VERSION "HNNBNNNYNNNNNNNNNNNNNNNNNNNNNNNNNNNNNNNNNN/4/%%%/4/'%**4NNN///"

NS_ :

BS_:

BU_: BAP_Tester CGS Gateway Gateway_PAG HUD Kombi Kombi_LB Kombi_PAG Waehlhebel_SB

BO_ 980 SMLS_01: 8 Gateway
 SG_ SMLS_01_CRC : 0|8@1+ (1,0) [0|255] ""  Vector__XXX
 SG_ SMLS_01_BZ : 8|4@1+ (1,0) [0|15] ""  Vector__XXX
 SG_ BH_Blinker_li : 12|1@1+ (1.0,0.0) [0.0|1] ""  Vector__XXX
 SG_ BH_Blinker_re : 13|1@1+ (1.0,0.0) [0.0|1] ""  Vector__XXX
 SG_ BH_Lichthupe : 14|1@1+ (1.0,0.0) [0.0|1] ""  Vector__XXX
 SG_ BH_Fernlicht : 15|1@1+ (1.0,0.0) [0.0|1] ""  Vector__XXX
 SG_ WH_Tipwischen : 16|1@1+ (1.0,0.0) [0.0|1] ""  Vector__XXX
 SG_ WH_Intervall : 17|1@1+ (1.0,0.0) [0.0|1] ""  Kombi_LB
 SG_ WH_WischerStufe1 : 18|1@1+ (1.0,0.0) [0.0|1] ""  Kombi_LB
 SG_ WH_WischerStufe2 : 19|1@1+ (1.0,0.0) [0.0|1] ""  Kombi_LB
 SG_ WH_Frontwaschen : 20|1@1+ (1.0,0.0) [0.0|1] ""  Vector__XXX
 SG_ WH_Heckintervall : 21|1@1+ (1.0,0.0) [0.0|1] ""  Kombi,Kombi_LB
 SG_ WH_Heckwaschen : 22|1@1+ (1.0,0.0) [0.0|1] ""  Vector__XXX
 SG_ WH_Intervallstufen : 23|4@1+ (1.0,0.0) [0.0|15] ""  Vector__XXX
 SG_ FAS_Taster : 27|1@1+ (1.0,0.0) [0.0|1] ""  Kombi,Kombi_LB
 SG_ FAS_Taster_Fehler : 28|1@1+ (1.0,0.0) [0.0|1] ""  Vector__XXX
 SG_ SMLS_Hupe : 29|1@1+ (1.0,0.0) [0.0|1] ""  Vector__XXX
 SG_ LRH_On_Off : 30|2@1+ (1.0,0.0) [0.0|3] ""  Kombi,Kombi_LB,Kombi_PAG
 SG_ LRH_aktiv : 40|1@1+ (1.0,0.0) [0.0|1] ""  Vector__XXX
 SG_ SMLS_P_verriegelt_plausibel : 43|1@1+ (1.0,0.0) [0.0|1] ""  Vector__XXX
 SG_ WH_SRA : 44|1@1+ (1.0,0.0) [0.0|1] ""  Vector__XXX
 SG_ WH_Wischer_Fehler : 45|1@1+ (1.0,0.0) [0.0|1] ""  Vector__XXX
 SG_ BH_Blinker_Fehler : 46|1@1+ (1.0,0.0) [0.0|1] ""  Vector__XXX
 SG_ SMLS_PTT : 47|1@1+ (1.0,0.0) [0.0|1] ""  Vector__XXX
 SG_ WH_Tipwischen_lang : 48|1@1+ (1.0,0.0) [0.0|1] ""  Vector__XXX

BO_ 904 SpoilerSG_01: 8 Gateway
 SG_ SpoilerSG_01_CRC : 0|8@1+ (1,0) [0|255] ""  Kombi,Kombi_PAG
 SG_ SpoilerSG_01_BZ : 8|4@1+ (1,0) [0|15] ""  Kombi,Kombi_PAG
 SG_ SpoilerSG_HSpoiler_IstPos : 12|8@1+ (4,0) [0|1012] ""  Kombi_PAG
 SG_ SpoilerSG_Fehler : 20|2@1+ (1.0,0.0) [0.0|3] ""  Kombi,Kombi_PAG
 SG_ SpoilerSG_Anf_ESP_Zuschaltung : 22|1@1+ (1.0,0.0) [0.0|1] ""  Vector__XXX
 SG_ SpoilerSG_Status : 23|2@1+ (1.0,0.0) [0.0|3] ""  Kombi_PAG
 SG_ LFE_Status : 25|1@1+ (1.0,0.0) [0.0|1] ""  Kombi_PAG
 SG_ TE_TrunkEntrapment_Fehler : 26|1@1+ (1.0,0.0) [0.0|1] ""  Vector__XXX
 SG_ SpoilerSG_AeroZustand : 27|4@1+ (1.0,0.0) [0.0|15] ""  Vector__XXX
 SG_ BugSp_AOCCT_Fehlerstatus : 31|1@1+ (1.0,0.0) [0.0|1] ""  Vector__XXX
 SG_ BugSp_AOCCT_Teststatus : 32|1@1+ (1.0,0.0) [0.0|1] ""  Vector__XXX
 SG_ BugSp_AOCCT_timer1_count : 33|1@1+ (1.0,0.0) [0.0|1] ""  Vector__XXX
 SG_ BugSp_AOCCT_timer1_verbaut : 34|1@1+ (1.0,0.0) [0.0|1] ""  Vector__XXX
 SG_ BugSp_AOCCT_timer2_count : 35|1@1+ (1.0,0.0) [0.0|1] ""  Vector__XXX
 SG_ BugSp_AOCCT_timer2_verbaut : 36|1@1+ (1.0,0.0) [0.0|1] ""  Vector__XXX
 SG_ HeckSp_AOCCT_Fehlerstatus : 37|1@1+ (1.0,0.0) [0.0|1] ""  Vector__XXX
 SG_ HeckSp_AOCCT_Teststatus : 38|1@1+ (1.0,0.0) [0.0|1] ""  Vector__XXX
 SG_ HeckSp_AOCCT_timer1_count : 39|1@1+ (1.0,0.0) [0.0|1] ""  Vector__XXX
 SG_ HeckSp_AOCCT_timer1_verbaut : 40|1@1+ (1.0,0.0) [0.0|1] ""  Vector__XXX
 SG_ HeckSp_AOCCT_timer2_count : 41|1@1+ (1.0,0.0) [0.0|1] ""  Vector__XXX
 SG_ HeckSp_AOCCT_timer2_verbaut : 42|1@1+ (1.0,0.0) [0.0|1] ""  Vector__XXX
 SG_ SpoilerSG_SKE_PosSens_Status : 43|2@1+ (1.0,0.0) [0.0|3] ""  Vector__XXX

BO_ 1313 STH_01: 8 Gateway
 SG_ STH_Funk_ein : 0|1@1+ (1.0,0.0) [0.0|1] ""  Vector__XXX
 SG_ STH_Funk_aus : 1|1@1+ (1.0,0.0) [0.0|1] ""  Vector__XXX
 SG_ STH_Zusatzheizung : 2|1@1+ (1.0,0.0) [0.0|1] ""  Vector__XXX
 SG_ STH_LED : 3|1@1+ (1.0,0.0) [0.0|1] ""  Kombi,Kombi_PAG
 SG_ STH_Pumpe_ein : 4|1@1+ (1,0) [0|1] ""  Vector__XXX
 SG_ STH_Geblaese : 5|1@1+ (1.0,0.0) [0.0|1] ""  Vector__XXX
 SG_ STH_EKP_Anst : 6|1@1+ (1.0,0.0) [0.0|1] ""  Vector__XXX
 SG_ STH_Start_folgt : 7|1@1+ (1.0,0.0) [0.0|1] ""  Vector__XXX
 SG_ STH_Ventiloeffnungszeit : 8|6@1+ (1,0) [0|63] "Unit_Minut"  Vector__XXX
 SG_ STH_Ventil_Status : 14|1@1+ (1.0,0.0) [0.0|1] ""  Vector__XXX
 SG_ STH_Fehler_ElWaPu : 15|1@1+ (1.0,0.0) [0.0|1] ""  Vector__XXX
 SG_ STH_Waermeeintrag : 16|6@1+ (1,0) [0|63] "Unit_None"  Vector__XXX
 SG_ STH_Pumpen_Anf_extern : 22|1@1+ (1.0,0.0) [0.0|1] ""  Vector__XXX
 SG_ STH_KL_HUP : 23|1@1+ (1.0,0.0) [0.0|1] ""  Vector__XXX
 SG_ STH_KVS : 24|13@1+ (1,0) [0|8191] "Unit_MilliLiter"  Kombi,Kombi_PAG
 SG_ STH_Fehlerstatus : 37|3@1+ (1.0,0.0) [0.0|7] ""  Vector__XXX
 SG_ STH_Heizleistung : 40|8@1+ (1,0) [0|255] ""  Vector__XXX
 SG_ STH_Wassertemp : 48|8@1+ (0.75,-40) [-40.00|142.25] "Unit_DegreCelsi"  Vector__XXX
 SG_ STH_Texte : 56|3@1+ (1.0,0.0) [0.0|7] ""  Kombi,Kombi_PAG
 SG_ STH_Motorvorwaermung : 59|1@1+ (1.0,0.0) [0.0|1] ""  Vector__XXX
 SG_ STH_Servicemode : 60|1@1+ (1.0,0.0) [0.0|1] ""  Vector__XXX
 SG_ STH_war_aktiv : 61|1@1+ (1.0,0.0) [0.0|1] ""  Vector__XXX
 SG_ STH_KVS_Ueberlauf : 62|1@1+ (1.0,0.0) [0.0|1] ""  Kombi,Kombi_LB,Kombi_PAG
 SG_ STH_SH_ZH : 63|1@1+ (1.0,0.0) [0.0|1] ""  Vector__XXX

BO_ 505 STP_03: 8 Gateway
 SG_ STP_03_CRC : 0|8@1+ (1,0) [0|255] ""  Vector__XXX
 SG_ STP_03_BZ : 8|4@1+ (1,0) [0|15] ""  Vector__XXX
 SG_ STP_Slave_Status : 12|4@1+ (1.0,0.0) [0.0|15] ""  Vector__XXX
 SG_ FZE_STP_Abschaltbedingung : 16|3@1+ (1.0,0.0) [0.0|7] ""  Vector__XXX
 SG_ ACA_HF_Grund_AV_AB : 19|3@1+ (1.0,0.0) [0.0|7] ""  Vector__XXX
 SG_ FZE_STP_Status : 22|2@1+ (1.0,0.0) [0.0|3] ""  Vector__XXX
 SG_ STP_Notlaufaktivierung : 25|1@1+ (1.0,0.0) [0.0|1] ""  Vector__XXX
 SG_ STP_Funktion_freigegeben : 26|1@1+ (1.0,0.0) [0.0|1] ""  Vector__XXX
 SG_ ACA_QF_Status_Anzeige : 27|4@1+ (1.0,0.0) [0.0|15] ""  HUD,Kombi,Kombi_LB,Kombi_PAG
 SG_ ACF_SwuFahrerUnaufmerksam : 31|1@1+ (1.0,0.0) [0.0|1] ""  Vector__XXX
 SG_ ACA_QF_Fahreruebernahme : 32|2@1+ (1.0,0.0) [0.0|3] ""  Kombi_PAG
 SG_ ACA_HF_Status : 34|4@1+ (1.0,0.0) [0.0|15] ""  Vector__XXX
 SG_ FZE_Spurwechsel_erkannt_li : 40|1@1+ (1.0,0.0) [0.0|1] ""  Vector__XXX
 SG_ FZE_Spurwechsel_erkannt_re : 41|1@1+ (1.0,0.0) [0.0|1] ""  Vector__XXX
 SG_ ACF_Spurwechsel_moeglich : 42|1@1+ (1.0,0.0) [0.0|1] ""  Vector__XXX
 SG_ ACF_Spurwechsel_wahrscheinlich : 43|1@1+ (1.0,0.0) [0.0|1] ""  Vector__XXX
 SG_ FZE_STP_Aktivierverhinderung : 44|2@1+ (1.0,0.0) [0.0|3] ""  Vector__XXX

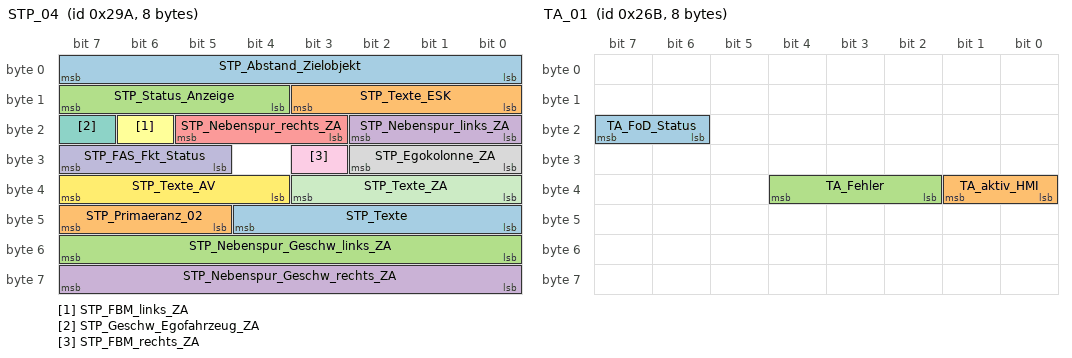
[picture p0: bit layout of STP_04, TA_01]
BO_ 666 STP_04: 8 Gateway
 SG_ STP_Abstand_Zielobjekt : 0|8@1+ (1,0) [1|250] ""  Kombi,Kombi_LB,Kombi_PAG
 SG_ STP_Texte_ESK : 8|4@1+ (1.0,0.0) [0.0|15] ""  Kombi,Kombi_LB,Kombi_PAG
 SG_ STP_Status_Anzeige : 12|4@1+ (1.0,0.0) [0.0|15] ""  HUD,Kombi,Kombi_LB,Kombi_PAG
 SG_ STP_Nebenspur_links_ZA : 16|3@1+ (1.0,0.0) [0.0|7] ""  Kombi,Kombi_LB,Kombi_PAG
 SG_ STP_Nebenspur_rechts_ZA : 19|3@1+ (1.0,0.0) [0.0|7] ""  Kombi,Kombi_LB,Kombi_PAG
 SG_ STP_FBM_links_ZA : 22|1@1+ (1.0,0.0) [0.0|1] ""  Kombi,Kombi_LB,Kombi_PAG
 SG_ STP_Geschw_Egofahrzeug_ZA : 23|1@1+ (1.0,0.0) [0.0|1] ""  Kombi,Kombi_LB,Kombi_PAG
 SG_ STP_Egokolonne_ZA : 24|3@1+ (1.0,0.0) [0.0|7] ""  Kombi,Kombi_LB,Kombi_PAG
 SG_ STP_FBM_rechts_ZA : 27|1@1+ (1.0,0.0) [0.0|1] ""  Kombi,Kombi_LB,Kombi_PAG
 SG_ STP_FAS_Fkt_Status : 29|3@1+ (1.0,0.0) [0.0|7] ""  HUD
 SG_ STP_Texte_ZA : 32|4@1+ (1.0,0.0) [0.0|15] ""  Kombi,Kombi_LB,Kombi_PAG
 SG_ STP_Texte_AV : 36|4@1+ (1.0,0.0) [0.0|15] ""  Kombi,Kombi_LB,Kombi_PAG
 SG_ STP_Texte : 40|5@1+ (1.0,0.0) [0.0|31] ""  Kombi,Kombi_LB,Kombi_PAG
 SG_ STP_Primaeranz_02 : 45|3@1+ (1.0,0.0) [0.0|7] ""  HUD,Kombi,Kombi_LB,Kombi_PAG
 SG_ STP_Nebenspur_Geschw_links_ZA : 48|8@1+ (1,0) [0|250] "Unit_KiloMeterPerHour"  Kombi,Kombi_LB
 SG_ STP_Nebenspur_Geschw_rechts_ZA : 56|8@1+ (1,0) [0|250] "Unit_KiloMeterPerHour"  Kombi,Kombi_LB

BO_ 1172 STS_01: 8 Gateway
 SG_ STS_01_CRC : 0|8@1+ (1,0) [0|255] ""  Vector__XXX
 SG_ STS_01_BZ : 8|4@1+ (1,0) [0|15] ""  Vector__XXX
 SG_ STS_Car_not_under_theft : 12|1@1+ (1.0,0.0) [0.0|1] ""  Vector__XXX
 SG_ STS_Car_under_theft : 13|1@1+ (1.0,0.0) [0.0|1] ""  Vector__XXX
 SG_ STS_Door_Lock : 14|1@1+ (1.0,0.0) [0.0|1] ""  Vector__XXX
 SG_ STS_Anlassersperre : 15|1@1+ (1.0,0.0) [0.0|1] ""  Vector__XXX
 SG_ STS_Typencodierung : 16|5@1+ (1.0,0.0) [0.0|31] ""  Vector__XXX
 SG_ STS_Spiegel_Anklappen : 21|1@1+ (1.0,0.0) [0.0|1] ""  Vector__XXX
 SG_ GW_STS2_Privatsphaere : 22|1@1+ (1.0,0.0) [0.0|1] ""  Vector__XXX
 SG_ STS_LIN_aktiv : 23|1@1+ (1.0,0.0) [0.0|1] ""  Vector__XXX
 SG_ STS_Standlicht : 24|1@1+ (1.0,0.0) [0.0|1] ""  Vector__XXX
 SG_ STS_Fahrlicht : 25|1@1+ (1.0,0.0) [0.0|1] ""  Vector__XXX
 SG_ STS_Alarm_still : 26|1@1+ (1.0,0.0) [0.0|1] ""  Vector__XXX
 SG_ STS_Texte : 27|4@1+ (1.0,0.0) [0.0|15] ""  Kombi,Kombi_LB,Kombi_PAG
 SG_ STS_Laderelais : 38|1@1+ (1.0,0.0) [0.0|1] ""  Vector__XXX
 SG_ STS_Summer : 48|1@1+ (1.0,0.0) [0.0|1] ""  Vector__XXX
 SG_ STS_Alarm_Blinker : 50|1@1+ (1.0,0.0) [0.0|1] ""  Vector__XXX
 SG_ STS_Notstart : 51|1@1+ (1.0,0.0) [0.0|1] ""  Vector__XXX
 SG_ STS_Signalhorn : 55|1@1+ (1.0,0.0) [0.0|1] ""  Vector__XXX
 SG_ STS_Leerlaufschaltung : 56|1@1+ (1.0,0.0) [0.0|1] ""  Vector__XXX

BO_ 783 SWA_01: 8 Gateway
 SG_ SWA_01_CRC : 0|8@1+ (1,0) [0|255] ""  Vector__XXX
 SG_ SWA_01_BZ : 8|4@1+ (1,0) [0|15] ""  Vector__XXX
 SG_ SWA_Anzeigen : 12|4@1+ (1.0,0.0) [0.0|15] ""  Kombi,Kombi_LB,Kombi_PAG
 SG_ SWA_Blindheit_erkannt : 16|1@1+ (1.0,0.0) [0.0|1] ""  Vector__XXX
 SG_ SWA_rel_Nichtverf : 17|1@1+ (1.0,0.0) [0.0|1] ""  Vector__XXX
 SG_ SWA_rel_Fehler : 18|1@1+ (1.0,0.0) [0.0|1] ""  Vector__XXX
 SG_ SWA_Sta_aktiv : 19|1@1+ (1.0,0.0) [0.0|1] ""  Kombi_PAG
 SG_ SWA_Sta_passiv : 20|1@1+ (1.0,0.0) [0.0|1] ""  Kombi_PAG
 SG_ SWA_FT_RueckLED : 21|1@1+ (1.0,0.0) [0.0|1] ""  Vector__XXX
 SG_ ASW_Status : 22|2@1+ (1.0,0.0) [0.0|3] ""  Kombi_PAG
 SG_ SWA_Standziele_li : 24|1@1+ (1.0,0.0) [0.0|1] ""  Vector__XXX
 SG_ SWA_Kolonne_li : 25|1@1+ (1.0,0.0) [0.0|1] ""  Vector__XXX
 SG_ SWA_Infostufe_SWA_li : 26|1@1+ (1.0,0.0) [0.0|1] ""  Kombi
 SG_ SWA_Warnung_SWA_li : 27|1@1+ (1.0,0.0) [0.0|1] ""  Kombi
 SG_ ASW_Warnung_FS : 28|1@1+ (1.0,0.0) [0.0|1] ""  Vector__XXX
 SG_ ASW_Warnung_BFS : 29|1@1+ (1.0,0.0) [0.0|1] ""  Vector__XXX
 SG_ ASW_Kombitexte : 30|3@1+ (1.0,0.0) [0.0|7] ""  Kombi,Kombi_LB,Kombi_PAG
 SG_ SWA_Kolonne_mi : 33|1@1+ (1.0,0.0) [0.0|1] ""  Vector__XXX
 SG_ ASW_Modus : 34|3@1+ (1.0,0.0) [0.0|7] ""  Vector__XXX
 SG_ SWA_Modus : 37|3@1+ (1.0,0.0) [0.0|7] ""  Vector__XXX
 SG_ SWA_Standziele_re : 40|1@1+ (1.0,0.0) [0.0|1] ""  Vector__XXX
 SG_ SWA_Kolonne_re : 41|1@1+ (1.0,0.0) [0.0|1] ""  Vector__XXX
 SG_ SWA_Infostufe_SWA_re : 42|1@1+ (1.0,0.0) [0.0|1] ""  Kombi
 SG_ SWA_Warnung_SWA_re : 43|1@1+ (1.0,0.0) [0.0|1] ""  Kombi
 SG_ HRE_Anzeigetexte : 44|4@1+ (1.0,0.0) [0.0|15] ""  Vector__XXX
 SG_ SWA_Status_02 : 48|2@1+ (1.0,0.0) [0.0|3] ""  Vector__XXX
 SG_ Heckradar_Kombitexte : 56|5@1+ (1.0,0.0) [0.0|31] ""  Kombi,Kombi_LB,Kombi_PAG
 SG_ RCTA_Kombitexte : 61|3@1+ (1.0,0.0) [0.0|7] ""  Kombi,Kombi_LB,Kombi_PAG

BO_ 1413 Systeminfo_01: 8 Gateway
 SG_ SI_Sammel_SG_Fehler : 0|6@1+ (1,0) [0|60] ""  Vector__XXX
 SG_ SI_Diagnose_Aktiv : 7|1@1+ (1.0,0.0) [0.0|1] ""  Vector__XXX
 SG_ SI_QRS_Mode : 8|1@1+ (1.0,0.0) [0.0|1] ""  HUD,Kombi,Kombi_LB,Kombi_PAG
 SG_ SI_T_Mode : 9|1@1+ (1.0,0.0) [0.0|1] ""  HUD,Kombi,Kombi_LB,Kombi_PAG
 SG_ SI_NWDF : 10|1@1+ (1.0,0.0) [0.0|1] ""  CGS,HUD,Kombi,Kombi_LB,Kombi_PAG,Waehlhebel_SB
 SG_ SI_NWDF_gueltig : 11|1@1+ (1.0,0.0) [0.0|1] ""  CGS,HUD,Kombi,Kombi_LB,Kombi_PAG,Waehlhebel_SB
 SG_ SI_Sammelfehler : 12|1@1+ (1.0,0.0) [0.0|1] ""  Kombi,Kombi_LB
 SG_ GW_KD_Fehler : 13|1@1+ (1.0,0.0) [0.0|1] ""  Vector__XXX
 SG_ SI_T_Schutz : 14|1@1+ (1.0,0.0) [0.0|1] ""  Kombi,Kombi_LB,Kombi_PAG
 SG_ SI_BUS_01 : 16|1@1+ (1.0,0.0) [0.0|1] ""  HUD,Kombi,Kombi_LB,Kombi_PAG
 SG_ SI_BUS_02 : 17|1@1+ (1.0,0.0) [0.0|1] ""  Vector__XXX
 SG_ SI_BUS_03 : 18|1@1+ (1.0,0.0) [0.0|1] ""  HUD,Kombi,Kombi_LB,Kombi_PAG
 SG_ SI_BUS_04 : 19|1@1+ (1.0,0.0) [0.0|1] ""  HUD,Kombi,Kombi_LB,Kombi_PAG
 SG_ SI_BUS_05 : 20|1@1+ (1.0,0.0) [0.0|1] ""  Vector__XXX
 SG_ SI_BUS_06 : 21|1@1+ (1.0,0.0) [0.0|1] ""  HUD,Kombi,Kombi_LB,Kombi_PAG
 SG_ SI_BUS_07 : 22|1@1+ (1.0,0.0) [0.0|1] ""  Vector__XXX
 SG_ SI_BUS_08 : 23|1@1+ (1.0,0.0) [0.0|1] ""  Vector__XXX
 SG_ SI_BUS_09 : 24|1@1+ (1.0,0.0) [0.0|1] ""  Vector__XXX
 SG_ SI_BUS_10 : 25|1@1+ (1.0,0.0) [0.0|1] ""  CGS,Kombi,Kombi_LB,Kombi_PAG,Waehlhebel_SB
 SG_ SI_BUS_11 : 26|1@1+ (1.0,0.0) [0.0|1] ""  Vector__XXX
 SG_ SI_BUS_12 : 27|1@1+ (1.0,0.0) [0.0|1] ""  Kombi,Kombi_LB,Kombi_PAG
 SG_ SI_BUS_13 : 28|1@1+ (1.0,0.0) [0.0|1] ""  Kombi,Kombi_LB,Kombi_PAG
 SG_ SI_BUS_14 : 29|1@1+ (1.0,0.0) [0.0|1] ""  Vector__XXX
 SG_ SI_BUS_15 : 30|1@1+ (1.0,0.0) [0.0|1] ""  Vector__XXX
 SG_ SI_Bus_Identifikation : 32|8@1+ (1.0,0.0) [0.0|255] ""  Vector__XXX
 SG_ SI_CAB : 40|24@1+ (1.0,0.0) [0.0|16777215] ""  Vector__XXX

BO_ 619 TA_01: 8 Gateway
 SG_ TA_FoD_Status : 22|2@1+ (1.0,0.0) [0.0|3] ""  Kombi
 SG_ TA_aktiv_HMI : 32|2@1+ (1.0,0.0) [0.0|3] ""  HUD,Kombi
 SG_ TA_Fehler : 34|3@1+ (1.0,0.0) [0.0|7] ""  HUD,Kombi

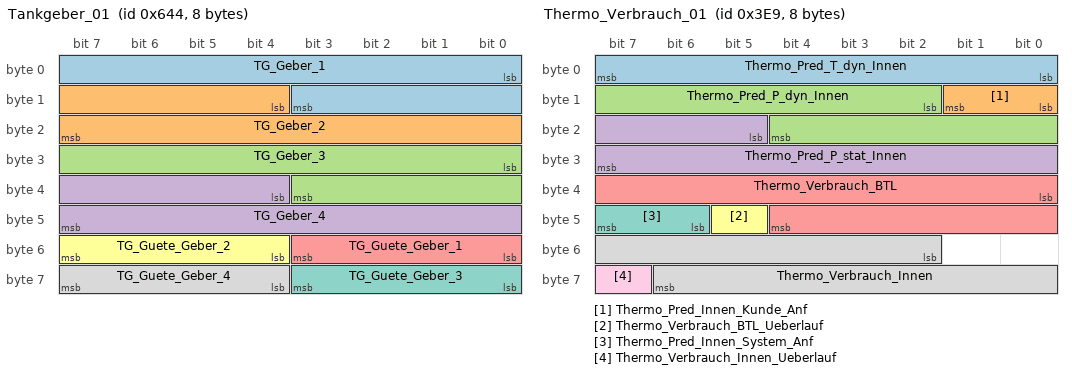
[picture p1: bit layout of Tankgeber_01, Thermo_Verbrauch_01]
BO_ 1604 Tankgeber_01: 8 Gateway
 SG_ TG_Geber_1 : 0|12@1+ (1,0) [1|4094] "Unit_Ohm"  Kombi,Kombi_LB,Kombi_PAG
 SG_ TG_Geber_2 : 12|12@1+ (1,0) [1|4094] "Unit_Ohm"  Kombi,Kombi_LB,Kombi_PAG
 SG_ TG_Geber_3 : 24|12@1+ (1,0) [1|4094] "Unit_Ohm"  Kombi,Kombi_LB,Kombi_PAG
 SG_ TG_Geber_4 : 36|12@1+ (1,0) [1|4094] "Unit_Ohm"  Kombi,Kombi_LB,Kombi_PAG
 SG_ TG_Guete_Geber_1 : 48|4@1+ (1.0,0.0) [0.0|15] ""  Kombi,Kombi_LB,Kombi_PAG
 SG_ TG_Guete_Geber_2 : 52|4@1+ (1.0,0.0) [0.0|15] ""  Kombi,Kombi_LB,Kombi_PAG
 SG_ TG_Guete_Geber_3 : 56|4@1+ (1.0,0.0) [0.0|15] ""  Kombi,Kombi_LB,Kombi_PAG
 SG_ TG_Guete_Geber_4 : 60|4@1+ (1.0,0.0) [0.0|15] ""  Kombi,Kombi_LB,Kombi_PAG

BO_ 1001 Thermo_Verbrauch_01: 8 Gateway
 SG_ Thermo_Pred_T_dyn_Innen : 0|8@1+ (1,0) [0|253] "Unit_Minut"  Kombi,Kombi_LB
 SG_ Thermo_Pred_Innen_Kunde_Anf : 8|2@1+ (1,0) [0|3] "Unit_None"  Kombi,Kombi_LB
 SG_ Thermo_Pred_P_dyn_Innen : 10|11@1+ (10,0) [0|20450] "Unit_Watt"  Kombi,Kombi_LB
 SG_ Thermo_Pred_P_stat_Innen : 21|11@1+ (10,0) [0|20450] "Unit_Watt"  Kombi,Kombi_LB
 SG_ Thermo_Verbrauch_BTL : 32|13@1+ (1,0) [0|8191] "Unit_WattSecond"  Kombi,Kombi_LB,Kombi_PAG
 SG_ Thermo_Verbrauch_BTL_Ueberlauf : 45|1@1+ (1.0,0.0) [0.0|1] ""  Kombi,Kombi_LB,Kombi_PAG
 SG_ Thermo_Pred_Innen_System_Anf : 46|2@1+ (1,0) [0|3] "Unit_None"  Vector__XXX
 SG_ Thermo_Verbrauch_Innen : 50|13@1+ (1,0) [0|8191] "Unit_WattSecond"  Kombi,Kombi_LB,Kombi_PAG
 SG_ Thermo_Verbrauch_Innen_Ueberlauf : 63|1@1+ (1.0,0.0) [0.0|1] ""  Kombi,Kombi_LB,Kombi_PAG

BO_ 1375 TME_10: 8 Gateway
 SG_ TME_VoKo_Strategie_Anzeige : 2|4@1+ (1.0,0.0) [0.0|15] ""  Kombi_PAG
 SG_ TME_Zuheizer_Freigabe : 6|1@1+ (1.0,0.0) [0.0|1] ""  Vector__XXX
 SG_ TME_AC_LED : 7|1@1+ (1.0,0.0) [0.0|1] ""  Vector__XXX
 SG_ TME_Heizstrategie : 8|4@1+ (1.0,0.0) [0.0|15] ""  Vector__XXX
 SG_ TME_Systemstatus : 12|2@1+ (1.0,0.0) [0.0|3] ""  Vector__XXX
 SG_ TME_Kbr_Innenraum : 14|1@1+ (1.0,0.0) [0.0|1] ""  Vector__XXX
 SG_ TME_Freigabe_Vorkond : 15|1@1+ (1.0,0.0) [0.0|1] ""  Vector__XXX
 SG_ TME_Verdampfer_Status : 16|1@1+ (1.0,0.0) [0.0|1] ""  Vector__XXX
 SG_ TME_Kuehlmittel_Sensor : 17|1@1+ (1.0,0.0) [0.0|1] ""  Kombi,Kombi_LB,Kombi_PAG
 SG_ TME_AC_Rueckmeldung : 18|2@1+ (1.0,0.0) [0.0|3] ""  Vector__XXX
 SG_ TME_Heizungspumpen_Anst : 20|4@1+ (10,0) [0|100] "Unit_PerCent"  Vector__XXX
 SG_ TME_Frischluftklappe_Soll : 24|7@1+ (1,0) [0|100] "Unit_PerCent"  Vector__XXX
 SG_ TME_Freigabe_Luft_PTC : 31|1@1+ (1.0,0.0) [0.0|1] ""  Vector__XXX
 SG_ TME_Umluftklappe_Soll : 32|7@1+ (1,0) [0|100] "Unit_PerCent"  Vector__XXX
 SG_ TME_Waermepumpe_aktiv : 39|1@1+ (1.0,0.0) [0.0|1] ""  Vector__XXX
 SG_ TME_Nachlaufzeit_Heizp : 40|6@1+ (15,0) [0|945] "Unit_Secon"  Vector__XXX
 SG_ TME_Absperrventil1_oeffnen : 46|2@1+ (1.0,0.0) [0.0|3] ""  Vector__XXX
 SG_ TME_Klima_Defizit : 48|8@1+ (40,0) [0|10000] "Unit_Watt"  Vector__XXX
 SG_ TME_Temp_KM_vor_HWT : 56|8@1+ (0.75,-40) [-40.00|149.75] "Unit_DegreCelsi"  Vector__XXX

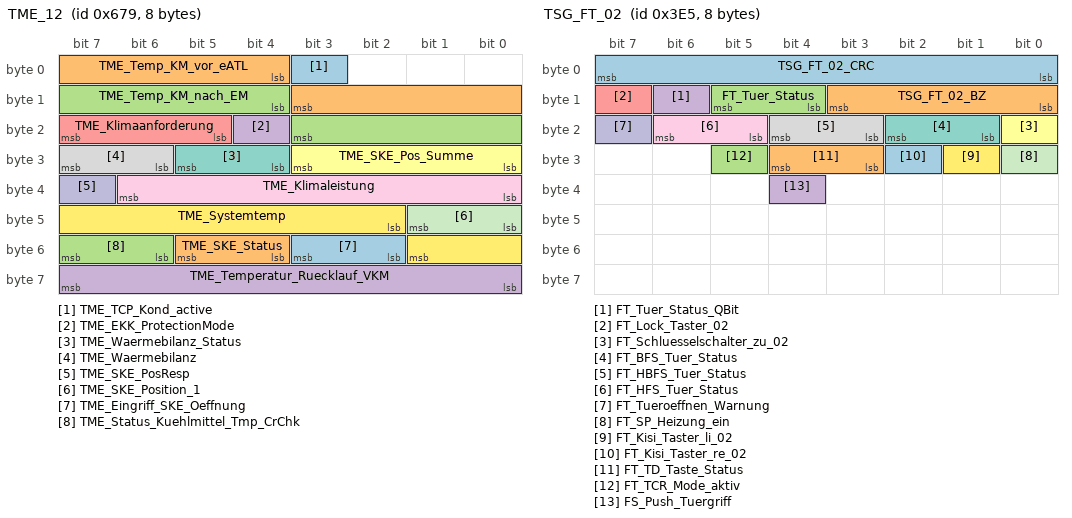
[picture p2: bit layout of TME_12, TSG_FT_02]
BO_ 1657 TME_12: 8 Gateway
 SG_ TME_TCP_Kond_active : 3|1@1+ (1.0,0.0) [0.0|1] ""  Kombi,Kombi_PAG
 SG_ TME_Temp_KM_vor_eATL : 4|8@1+ (1,-40) [-40|213] "Unit_DegreCelsi"  Vector__XXX
 SG_ TME_Temp_KM_nach_EM : 12|8@1+ (0.75,-48) [-48.00|141.00] "Unit_DegreCelsi"  Vector__XXX
 SG_ TME_EKK_ProtectionMode : 20|1@1+ (1.0,0.0) [0.0|1] ""  Vector__XXX
 SG_ TME_Klimaanforderung : 21|3@1+ (1.0,0.0) [0.0|7] ""  Vector__XXX
 SG_ TME_SKE_Pos_Summe : 24|4@1+ (10,0) [0|100] "Unit_PerCent"  Vector__XXX
 SG_ TME_Waermebilanz_Status : 28|2@1+ (1.0,0.0) [0.0|3] ""  Vector__XXX
 SG_ TME_Waermebilanz : 30|2@1+ (1.0,0.0) [0.0|3] ""  Vector__XXX
 SG_ TME_Klimaleistung : 32|7@1+ (0.04,0) [0.00|5.00] "Unit_KiloWatt"  Vector__XXX
 SG_ TME_SKE_PosResp : 39|1@1+ (1.0,0.0) [0.0|1] ""  Vector__XXX
 SG_ TME_SKE_Position_1 : 40|2@1+ (1.0,0.0) [0.0|3] ""  Vector__XXX
 SG_ TME_Systemtemp : 42|8@1+ (0.75,-48) [-48.00|141.75] "Unit_DegreCelsi"  Kombi,Kombi_LB
 SG_ TME_Eingriff_SKE_Oeffnung : 50|2@1+ (1.0,0.0) [0.0|3] ""  Vector__XXX
 SG_ TME_SKE_Status : 52|2@1+ (1.0,0.0) [0.0|3] ""  Vector__XXX
 SG_ TME_Status_Kuehlmittel_Tmp_CrChk : 54|2@1+ (1.0,0.0) [0.0|3] ""  Vector__XXX
 SG_ TME_Temperatur_Ruecklauf_VKM : 56|8@1+ (0.75,-40) [-40.00|149.75] "Unit_DegreCelsi"  Vector__XXX

BO_ 2527679762 TPUI_03: 8 Gateway
 SG_ TPUI_WarnLvlCmft : 12|4@1+ (1.0,0.0) [0.0|15] ""  Kombi
 SG_ TPUI_WarnLvlMaxV : 16|4@1+ (1.0,0.0) [0.0|15] ""  Kombi

BO_ 977 TSG_BT_01: 8 Gateway
 SG_ BT_Tuer_geoeffnet : 0|1@1+ (1.0,0.0) [0.0|1] ""  Vector__XXX
 SG_ BT_verriegelt : 1|1@1+ (1.0,0.0) [0.0|1] ""  Vector__XXX
 SG_ BT_gesafet : 2|1@1+ (1.0,0.0) [0.0|1] ""  Vector__XXX
 SG_ BT_Schluesselschalter_auf : 3|1@1+ (1.0,0.0) [0.0|1] ""  Vector__XXX
 SG_ BT_Schluesselschalter_zu : 4|1@1+ (1.0,0.0) [0.0|1] ""  Vector__XXX
 SG_ BT_Unlock_Taster : 5|1@1+ (1.0,0.0) [0.0|1] ""  Vector__XXX
 SG_ BT_Lock_Taster : 6|1@1+ (1.0,0.0) [0.0|1] ""  Vector__XXX
 SG_ BT_Sperrklinke : 7|1@1+ (1.0,0.0) [0.0|1] ""  Vector__XXX
 SG_ BT_TAG_betaetigt : 8|1@1+ (1.0,0.0) [0.0|1] ""  Vector__XXX
 SG_ BT_TIG_betaetigt : 9|1@1+ (1.0,0.0) [0.0|1] ""  Vector__XXX
 SG_ BT_EC_Spiegel_Helligkeit : 10|5@1+ (3.125,0) [0.000|96.875] "Unit_PerCent"  Vector__XXX
 SG_ BT_Sp_Heizung_Anf : 15|1@1+ (100,0) [0|100] "Unit_PerCent"  Vector__XXX
 SG_ BT_Tuer_Status : 16|2@1+ (1.0,0.0) [0.0|3] ""  Kombi_PAG
 SG_ BT_TSG_hinten_verbaut : 18|1@1+ (1.0,0.0) [0.0|1] ""  Vector__XXX
 SG_ BT_Sp_Blk_def : 19|1@1+ (1.0,0.0) [0.0|1] ""  Kombi,Kombi_LB,Kombi_PAG
 SG_ BT_FH_S_ManHoch : 20|1@1+ (1.0,0.0) [0.0|1] ""  Vector__XXX
 SG_ BT_FH_S_AutoHoch : 21|1@1+ (1.0,0.0) [0.0|1] ""  Vector__XXX
 SG_ BT_FH_S_ManTief : 22|1@1+ (1.0,0.0) [0.0|1] ""  Vector__XXX
 SG_ BT_FH_S_AutoTief : 23|1@1+ (1.0,0.0) [0.0|1] ""  Vector__XXX
 SG_ BT_FH_Oeffnung : 24|8@1+ (0.5,0) [0.0|100.0] "Unit_PerCent"  Vector__XXX
 SG_ BT_FH_Bew_hoch : 32|1@1+ (1.0,0.0) [0.0|1] ""  Vector__XXX
 SG_ BT_FH_Bew_tief : 33|1@1+ (1.0,0.0) [0.0|1] ""  Vector__XXX
 SG_ BT_FH_Fang : 34|1@1+ (1.0,0.0) [0.0|1] ""  Vector__XXX
 SG_ BT_FH_Block : 35|1@1+ (1.0,0.0) [0.0|1] ""  Vector__XXX
 SG_ BT_FH_Thermo : 36|1@1+ (1.0,0.0) [0.0|1] ""  Vector__XXX
 SG_ BT_UEKB_aktiviert : 37|1@1+ (1.0,0.0) [0.0|1] ""  Vector__XXX
 SG_ BT_Kisi_Fehler : 38|1@1+ (1.0,0.0) [0.0|1] ""  Vector__XXX
 SG_ BT_FH_normiert : 39|1@1+ (1.0,0.0) [0.0|1] ""  Vector__XXX
 SG_ BT_Schliesstaster : 40|1@1+ (1.0,0.0) [0.0|1] ""  Vector__XXX
 SG_ BT_Zuziehhilfe_aktiv : 41|1@1+ (1.0,0.0) [0.0|1] ""  Vector__XXX
 SG_ BT_SP_ausgerastet : 42|1@1+ (1.0,0.0) [0.0|1] ""  Vector__XXX
 SG_ BT_SP_lr_aktiv : 43|1@1+ (1.0,0.0) [0.0|1] ""  Vector__XXX
 SG_ BT_SP_ht_aktiv : 44|1@1+ (1.0,0.0) [0.0|1] ""  Vector__XXX
 SG_ BT_SP_Heizung_aktiv : 45|1@1+ (1.0,0.0) [0.0|1] ""  Vector__XXX
 SG_ BT_Oben_Block_erw : 46|1@1+ (1.0,0.0) [0.0|1] ""  Vector__XXX
 SG_ BT_Unten_Block_erw : 47|1@1+ (1.0,0.0) [0.0|1] ""  Vector__XXX
 SG_ BT_Tuer_Status_QBit : 48|1@1+ (1.0,0.0) [0.0|1] ""  Vector__XXX
 SG_ BFS_Status_eTAG : 49|2@1+ (1.0,0.0) [0.0|3] ""  Vector__XXX
 SG_ BT_TCR_Mode_aktiv : 51|1@1+ (1.0,0.0) [0.0|1] ""  Kombi_PAG
 SG_ BT_SP_Heizung_Status : 55|1@1+ (1.0,0.0) [0.0|1] ""  Vector__XXX
 SG_ ASW_Warnung_aktiv_BFS : 56|1@1+ (1.0,0.0) [0.0|1] ""  Kombi,Kombi_LB,Kombi_PAG
 SG_ BT_FH_Pos_oben : 57|1@1+ (1.0,0.0) [0.0|1] ""  Vector__XXX
 SG_ BT_Tuerschloss_defekt : 58|1@1+ (1.0,0.0) [0.0|1] ""  Kombi,Kombi_LB,Kombi_PAG
 SG_ BT_Tueroeffnen_Warnung : 59|1@1+ (1.0,0.0) [0.0|1] ""  Kombi,Kombi_LB,Kombi_PAG
 SG_ BT_Lock_Taster_inv : 60|1@1+ (1.0,0.0) [0.0|1] ""  Vector__XXX
 SG_ BT_Schluesselschalter_zu_inv : 61|1@1+ (1.0,0.0) [0.0|1] ""  Vector__XXX
 SG_ BT_SWA_HMI_defekt : 62|1@1+ (1.0,0.0) [0.0|1] ""  Vector__XXX
 SG_ BT_ASW_HMI_defekt : 63|1@1+ (1.0,0.0) [0.0|1] ""  Vector__XXX

BO_ 976 TSG_FT_01: 8 Gateway
 SG_ FT_Tuer_geoeffnet : 0|1@1+ (1.0,0.0) [0.0|1] ""  Vector__XXX
 SG_ FT_verriegelt : 1|1@1+ (1.0,0.0) [0.0|1] ""  HUD
 SG_ FT_gesafet : 2|1@1+ (1.0,0.0) [0.0|1] ""  Vector__XXX
 SG_ FT_Schluesselschalter_auf : 3|1@1+ (1.0,0.0) [0.0|1] ""  Vector__XXX
 SG_ FT_Schluesselschalter_zu : 4|1@1+ (1.0,0.0) [0.0|1] ""  Vector__XXX
 SG_ FT_Unlock_Taster : 5|1@1+ (1.0,0.0) [0.0|1] ""  Vector__XXX
 SG_ FT_Lock_Taster : 6|1@1+ (1.0,0.0) [0.0|1] ""  Vector__XXX
 SG_ FT_Sperrklinke : 7|1@1+ (1.0,0.0) [0.0|1] ""  Vector__XXX
 SG_ FT_TAG_betaetigt : 8|1@1+ (1.0,0.0) [0.0|1] ""  Vector__XXX
 SG_ FT_TIG_betaetigt : 9|1@1+ (1.0,0.0) [0.0|1] ""  Vector__XXX
 SG_ FT_IRUE_Taste : 10|1@1+ (1.0,0.0) [0.0|1] ""  Vector__XXX
 SG_ FT_HD_Taste : 11|1@1+ (1.0,0.0) [0.0|1] ""  Vector__XXX
 SG_ FT_TD_Taste_Fehler : 12|1@1+ (1.0,0.0) [0.0|1] ""  Vector__XXX
 SG_ FT_TD_Taste : 13|1@1+ (1.0,0.0) [0.0|1] ""  Vector__XXX
 SG_ SSR_Temp_Freigabe : 14|1@1+ (1.0,0.0) [0.0|1] ""  Vector__XXX
 SG_ FT_Sp_Heizung_Anf : 15|1@1+ (100,0) [0|100] "Unit_PerCent"  Vector__XXX
 SG_ FT_HD_Taste_2 : 16|1@1+ (1.0,0.0) [0.0|1] ""  Vector__XXX
 SG_ FT_TSG_hinten_verbaut : 18|1@1+ (1.0,0.0) [0.0|1] ""  Vector__XXX
 SG_ FT_Sp_Blk_def : 19|1@1+ (1.0,0.0) [0.0|1] ""  Kombi,Kombi_LB,Kombi_PAG
 SG_ FT_FH_S_ManHoch : 20|1@1+ (1.0,0.0) [0.0|1] ""  Vector__XXX
 SG_ FT_FH_S_AutoHoch : 21|1@1+ (1.0,0.0) [0.0|1] ""  Vector__XXX
 SG_ FT_FH_S_ManTief : 22|1@1+ (1.0,0.0) [0.0|1] ""  Vector__XXX
 SG_ FT_FH_S_AutoTief : 23|1@1+ (1.0,0.0) [0.0|1] ""  Vector__XXX
 SG_ FT_FH_Oeffnung : 24|8@1+ (0.5,0) [0.0|100.0] "Unit_PerCent"  Vector__XXX
 SG_ FT_FH_Bew_hoch : 32|1@1+ (1.0,0.0) [0.0|1] ""  Vector__XXX
 SG_ FT_FH_Bew_tief : 33|1@1+ (1.0,0.0) [0.0|1] ""  Vector__XXX
 SG_ FT_FH_Fang : 34|1@1+ (1.0,0.0) [0.0|1] ""  Vector__XXX
 SG_ FT_FH_Block : 35|1@1+ (1.0,0.0) [0.0|1] ""  Vector__XXX
 SG_ FT_FH_Thermo : 36|1@1+ (1.0,0.0) [0.0|1] ""  Vector__XXX
 SG_ FT_UEKB_aktiviert : 37|1@1+ (1.0,0.0) [0.0|1] ""  Vector__XXX
 SG_ ASW_HMI_defekt : 38|1@1+ (1.0,0.0) [0.0|1] ""  Vector__XXX
 SG_ FT_FH_normiert : 39|1@1+ (1.0,0.0) [0.0|1] ""  Vector__XXX
 SG_ FT_Schliesstaster : 40|1@1+ (1.0,0.0) [0.0|1] ""  Vector__XXX
 SG_ FT_Zuziehhilfe_aktiv : 41|1@1+ (1.0,0.0) [0.0|1] ""  Vector__XXX
 SG_ FT_SP_ausgerastet : 42|1@1+ (1.0,0.0) [0.0|1] ""  Vector__XXX
 SG_ FT_SP_lr_aktiv : 43|1@1+ (1.0,0.0) [0.0|1] ""  Vector__XXX
 SG_ FT_SP_ht_aktiv : 44|1@1+ (1.0,0.0) [0.0|1] ""  Vector__XXX
 SG_ ASW_wakeup : 45|1@1+ (1.0,0.0) [0.0|1] ""  Vector__XXX
 SG_ FT_Oben_Block_erw : 46|1@1+ (1.0,0.0) [0.0|1] ""  Vector__XXX
 SG_ FT_Unten_Block_erw : 47|1@1+ (1.0,0.0) [0.0|1] ""  Vector__XXX
 SG_ FT_Kisi_li_aktiv : 48|1@1+ (1.0,0.0) [0.0|1] ""  Vector__XXX
 SG_ FT_Kisi_re_aktiv : 49|1@1+ (1.0,0.0) [0.0|1] ""  Vector__XXX
 SG_ FT_Kisi_Taster_li : 50|1@1+ (1.0,0.0) [0.0|1] ""  Vector__XXX
 SG_ FT_Kisi_Taster_re : 51|1@1+ (1.0,0.0) [0.0|1] ""  Vector__XXX
 SG_ FT_BFS_Fond_Freigabe : 52|1@1+ (1.0,0.0) [0.0|1] ""  Vector__XXX
 SG_ FT_Kisi_Fehler : 53|1@1+ (1.0,0.0) [0.0|1] ""  Kombi,Kombi_LB,Kombi_PAG
 SG_ FT_Daemmglas : 54|1@1+ (1.0,0.0) [0.0|1] ""  Vector__XXX
 SG_ FT_SP_Heizung_Status : 55|1@1+ (1.0,0.0) [0.0|1] ""  Vector__XXX
 SG_ ASW_Warnung_aktiv_FS : 56|1@1+ (1.0,0.0) [0.0|1] ""  Kombi,Kombi_LB,Kombi_PAG
 SG_ FT_FH_Pos_oben : 57|1@1+ (1.0,0.0) [0.0|1] ""  Vector__XXX
 SG_ FT_Tuerschloss_defekt : 58|1@1+ (1.0,0.0) [0.0|1] ""  Kombi,Kombi_LB,Kombi_PAG
 SG_ FT_SWA_Taster : 59|1@1+ (1.0,0.0) [0.0|1] ""  Vector__XXX
 SG_ SWA_HMI_Diagnose : 60|2@1+ (1.0,0.0) [0.0|3] ""  Vector__XXX
 SG_ FS_Status_eTAG : 62|2@1+ (1.0,0.0) [0.0|3] ""  Vector__XXX

BO_ 997 TSG_FT_02: 8 Gateway
 SG_ TSG_FT_02_CRC : 0|8@1+ (1,0) [0|255] ""  Kombi,Kombi_LB,Kombi_PAG
 SG_ TSG_FT_02_BZ : 8|4@1+ (1,0) [0|15] ""  Kombi,Kombi_LB,Kombi_PAG
 SG_ FT_Tuer_Status : 12|2@1+ (1.0,0.0) [0.0|3] ""  HUD,Kombi,Kombi_LB,Kombi_PAG
 SG_ FT_Tuer_Status_QBit : 14|1@1+ (1.0,0.0) [0.0|1] ""  Vector__XXX
 SG_ FT_Lock_Taster_02 : 15|1@1+ (1.0,0.0) [0.0|1] ""  Vector__XXX
 SG_ FT_Schluesselschalter_zu_02 : 16|1@1+ (1.0,0.0) [0.0|1] ""  Vector__XXX
 SG_ FT_BFS_Tuer_Status : 17|2@1+ (1.0,0.0) [0.0|3] ""  Vector__XXX
 SG_ FT_HBFS_Tuer_Status : 19|2@1+ (1.0,0.0) [0.0|3] ""  Vector__XXX
 SG_ FT_HFS_Tuer_Status : 21|2@1+ (1.0,0.0) [0.0|3] ""  Vector__XXX
 SG_ FT_Tueroeffnen_Warnung : 23|1@1+ (1.0,0.0) [0.0|1] ""  Kombi,Kombi_LB,Kombi_PAG
 SG_ FT_SP_Heizung_ein : 24|1@1+ (1.0,0.0) [0.0|1] ""  Vector__XXX
 SG_ FT_Kisi_Taster_li_02 : 25|1@1+ (1.0,0.0) [0.0|1] ""  Vector__XXX
 SG_ FT_Kisi_Taster_re_02 : 26|1@1+ (1.0,0.0) [0.0|1] ""  Vector__XXX
 SG_ FT_TD_Taste_Status : 27|2@1+ (1.0,0.0) [0.0|3] ""  Vector__XXX
 SG_ FT_TCR_Mode_aktiv : 29|1@1+ (1.0,0.0) [0.0|1] ""  Kombi_PAG
 SG_ FS_Push_Tuergriff : 36|1@1+ (1.0,0.0) [0.0|1] ""  Vector__XXX

BO_ 975 TSG_HBFS_01: 8 Gateway
 SG_ HBFS_Tuer_geoeffnet : 0|1@1+ (1.0,0.0) [0.0|1] ""  Vector__XXX
 SG_ HBFS_verriegelt : 1|1@1+ (1.0,0.0) [0.0|1] ""  Vector__XXX
 SG_ HBFS_gesafet : 2|1@1+ (1.0,0.0) [0.0|1] ""  Vector__XXX
 SG_ HBFS_Heckrollotaster_betaetigt : 3|1@1+ (1.0,0.0) [0.0|1] ""  Vector__XXX
 SG_ HBFS_Tuerschloss_defekt : 4|1@1+ (1.0,0.0) [0.0|1] ""  Kombi,Kombi_LB,Kombi_PAG
 SG_ HBFS_Unlock_Taster : 5|1@1+ (1.0,0.0) [0.0|1] ""  Vector__XXX
 SG_ HBFS_Lock_Taster : 6|1@1+ (1.0,0.0) [0.0|1] ""  Vector__XXX
 SG_ HBFS_Sperrklinke : 7|1@1+ (1.0,0.0) [0.0|1] ""  Vector__XXX
 SG_ HBFS_TAG_betaetigt : 8|1@1+ (1.0,0.0) [0.0|1] ""  Vector__XXX
 SG_ HBFS_TIG_betaetigt : 9|1@1+ (1.0,0.0) [0.0|1] ""  Vector__XXX
 SG_ HBFS_FH_S_HFS_AutoHoch : 10|1@1+ (1.0,0.0) [0.0|1] ""  Vector__XXX
 SG_ HBFS_FH_S_HFS_AutoTief : 11|1@1+ (1.0,0.0) [0.0|1] ""  Vector__XXX
 SG_ HBFS_FH_S_HFS_ManHoch : 12|1@1+ (1.0,0.0) [0.0|1] ""  Vector__XXX
 SG_ HBFS_FH_S_HFS_ManTief : 13|1@1+ (1.0,0.0) [0.0|1] ""  Vector__XXX
 SG_ HBFS_Tuer_Status : 14|2@1+ (1.0,0.0) [0.0|3] ""  Kombi_PAG
 SG_ HBFS_SAD_Schalter : 16|4@1+ (1.0,0.0) [0.0|15] ""  Vector__XXX
 SG_ HBFS_FH_S_ManHoch : 20|1@1+ (1.0,0.0) [0.0|1] ""  Vector__XXX
 SG_ HBFS_FH_S_AutoHoch : 21|1@1+ (1.0,0.0) [0.0|1] ""  Vector__XXX
 SG_ HBFS_FH_S_ManTief : 22|1@1+ (1.0,0.0) [0.0|1] ""  Vector__XXX
 SG_ HBFS_FH_S_AutoTief : 23|1@1+ (1.0,0.0) [0.0|1] ""  Vector__XXX
 SG_ HBFS_FH_Oeffnung : 24|8@1+ (0.5,0) [0.0|100.0] "Unit_PerCent"  Vector__XXX
 SG_ HBFS_FH_Bew_hoch : 32|1@1+ (1.0,0.0) [0.0|1] ""  Vector__XXX
 SG_ HBFS_FH_Bew_tief : 33|1@1+ (1.0,0.0) [0.0|1] ""  Vector__XXX
 SG_ HBFS_FH_Fang : 34|1@1+ (1.0,0.0) [0.0|1] ""  Vector__XXX
 SG_ HBFS_FH_Block : 35|1@1+ (1.0,0.0) [0.0|1] ""  Vector__XXX
 SG_ HBFS_FH_Thermo : 36|1@1+ (1.0,0.0) [0.0|1] ""  Vector__XXX
 SG_ HBFS_UEKB_aktiviert : 37|1@1+ (1.0,0.0) [0.0|1] ""  Vector__XXX
 SG_ HBFS_Tueroeffnen_Warnung : 38|1@1+ (1.0,0.0) [0.0|1] ""  Kombi,Kombi_LB,Kombi_PAG
 SG_ HBFS_FH_normiert : 39|1@1+ (1.0,0.0) [0.0|1] ""  Vector__XXX
 SG_ ASW_Warnung_aktiv_HBFS : 40|1@1+ (1.0,0.0) [0.0|1] ""  Kombi,Kombi_LB,Kombi_PAG
 SG_ HBFS_Zuziehhilfe_aktiv : 41|1@1+ (1.0,0.0) [0.0|1] ""  Vector__XXX
 SG_ HBFS_Seitenrollo_hoch : 42|1@1+ (1.0,0.0) [0.0|1] ""  Vector__XXX
 SG_ HBFS_Seitenrollo_tief : 43|1@1+ (1.0,0.0) [0.0|1] ""  Vector__XXX
 SG_ HBFS_Status_KiSi : 44|1@1+ (1.0,0.0) [0.0|1] ""  Kombi_PAG
 SG_ SSR_HBFS_Pos_Unten : 45|1@1+ (1.0,0.0) [0.0|1] ""  Vector__XXX
 SG_ HBFS_Oben_Block_erw : 46|1@1+ (1.0,0.0) [0.0|1] ""  Vector__XXX
 SG_ HBFS_Unten_Block_erw : 47|1@1+ (1.0,0.0) [0.0|1] ""  Vector__XXX
 SG_ MTHBFS_M_Taste : 48|1@1+ (1.0,0.0) [0.0|1] ""  Vector__XXX
 SG_ MTHBFS_Pos1 : 49|1@1+ (1.0,0.0) [0.0|1] ""  Vector__XXX
 SG_ MTHBFS_Pos2 : 50|1@1+ (1.0,0.0) [0.0|1] ""  Vector__XXX
 SG_ MTHBFS_Pos3 : 51|1@1+ (1.0,0.0) [0.0|1] ""  Vector__XXX
 SG_ HBFS_MRollo_Schalter : 52|3@1+ (1.0,0.0) [0.0|7] ""  Vector__XXX
 SG_ HBFS_Lock_Taster_inv : 55|1@1+ (1.0,0.0) [0.0|1] ""  Vector__XXX
 SG_ HBFS_Status_KiSi_inv : 56|1@1+ (1.0,0.0) [0.0|1] ""  Vector__XXX
 SG_ HBFS_Status_eTAG : 57|2@1+ (1.0,0.0) [0.0|3] ""  Vector__XXX
 SG_ HBFS_Tuer_Status_QBit : 59|1@1+ (1.0,0.0) [0.0|1] ""  Vector__XXX
 SG_ HBFS_TIG_betaetigt_schliessen : 60|1@1+ (1.0,0.0) [0.0|1] ""  Vector__XXX

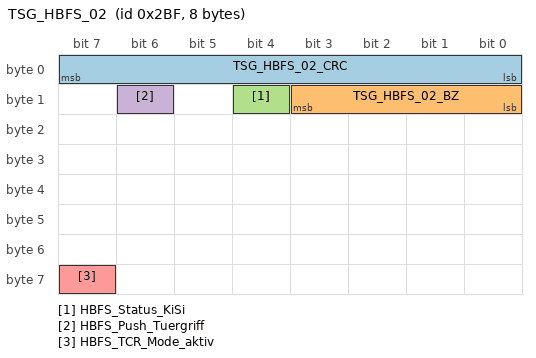
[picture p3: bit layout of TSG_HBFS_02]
BO_ 703 TSG_HBFS_02: 8 Gateway_PAG
 SG_ TSG_HBFS_02_CRC : 0|8@1+ (1,0) [0|255] ""  Vector__XXX
 SG_ TSG_HBFS_02_BZ : 8|4@1+ (1,0) [0|15] ""  Vector__XXX
 SG_ HBFS_Status_KiSi : 12|1@1+ (1.0,0.0) [0.0|1] ""  Vector__XXX
 SG_ HBFS_Push_Tuergriff : 14|1@1+ (1.0,0.0) [0.0|1] ""  Vector__XXX
 SG_ HBFS_TCR_Mode_aktiv : 63|1@1+ (1.0,0.0) [0.0|1] ""  Kombi_PAG

BO_TX_BU_ 980 :Gateway,Gateway_PAG;
BO_TX_BU_ 904 :Gateway,Gateway_PAG;
BO_TX_BU_ 1313 :Gateway,Gateway_PAG;
BO_TX_BU_ 505 :Gateway,Gateway_PAG;
BO_TX_BU_ 666 :Gateway,Gateway_PAG;
BO_TX_BU_ 1172 :Gateway,Gateway_PAG;
BO_TX_BU_ 783 :Gateway,Gateway_PAG;
BO_TX_BU_ 1413 :Gateway,Gateway_PAG;
BO_TX_BU_ 619 :Gateway,Gateway_PAG;
BO_TX_BU_ 1604 :Gateway,Gateway_PAG;
BO_TX_BU_ 1001 :Gateway,Gateway_PAG;
BO_TX_BU_ 1375 :Gateway,Gateway_PAG;
BO_TX_BU_ 1657 :Gateway,Gateway_PAG;
BO_TX_BU_ 2527679762 :Gateway,Gateway_PAG;
BO_TX_BU_ 977 :Gateway,Gateway_PAG;
BO_TX_BU_ 976 :Gateway,Gateway_PAG;
BO_TX_BU_ 997 :Gateway,Gateway_PAG;
BO_TX_BU_ 975 :Gateway,Gateway_PAG;
CM_ BO_ 980 "Ab MQB 7.2";
CM_ BO_ 783 "ab MQB mit CRC-8";
CM_ BO_ 1413 "MQB, MLBevo";
CM_ BO_ 1604 "Tankgeberwerte für Algorithmus im Kombi";
CM_ BO_ 977 "ab MQB 7.05";
CM_ BO_ 976 "ab MQB 7.05";

CM_ SG_ 980 BH_Blinker_Fehler "Anzeige, ob am Lenkstockschalter ein Fehler anliegt.
Notwendig aufgrund ASIL-Einstufung";
CM_ SG_ 980 BH_Blinker_li "Blinkerhebel Richtung links";
CM_ SG_ 980 BH_Blinker_re "Blinkerhebel Richtung rechts";
CM_ SG_ 980 BH_Fernlicht "Betaetigung Fernlicht
";
CM_ SG_ 980 BH_Lichthupe "Betaetigung Lichthupe
";
CM_ SG_ 980 FAS_Taster "Betaetigung FAS Taster
";
CM_ SG_ 980 FAS_Taster_Fehler "Fehlerstatus FAS Taster
";
CM_ SG_ 980 LRH_aktiv "Signal gibt an, ob ein Heizstrom durch die Lenkradheizung fließt. Es dient der Auswertung durch das Energiemanagement.";
CM_ SG_ 980 LRH_On_Off "Status Lenkradheizung";
CM_ SG_ 980 SMLS_01_BZ "4bit Botschaftszaehler, wird mit jeder Sendebotschaft inkrementiert";
CM_ SG_ 980 SMLS_01_CRC "Für MLB:
'Berechnung siehe Lastenheft 'Kommunikationsabsicherung für FlexRay und CAN''

Ab MQB und MLBevo:
'Berechnung siehe Lastenheft 'End-to-End Kommunikationsabsicherung''

Endwerte siehe Begleitdokument 'S-PDU Kennungsfolgen'";
CM_ SG_ 980 SMLS_Hupe "Betaetigung Hupe
";
CM_ SG_ 980 SMLS_P_verriegelt_plausibel "Signal stellt den Plausibilisierungstatus des Signals p_verriegelt auf den Fahrzeugbus zur Verfügung. Eine Plausibilität muss explizit erkannt werden. Initial wird 'unplausibel' gesendet. Ein plausibles Signal wird erkannt, wenn p_verriegelt plausibel geg";
CM_ SG_ 980 SMLS_PTT "Betaetigung PTT";
CM_ SG_ 980 WH_Frontwaschen "Wischerhebel: Stellung Wisch Wasch vorne
";
CM_ SG_ 980 WH_Heckintervall "Wischerhebel: Stellung Heckintervall
";
CM_ SG_ 980 WH_Heckwaschen "Wischerhebel: Stellung Wisch Wasch hinten
";
CM_ SG_ 980 WH_Intervall "Wischerhebel: Stellung Intervall
";
CM_ SG_ 980 WH_Intervallstufen "Wischerhebel: Stellung Intervallstufen";
CM_ SG_ 980 WH_SRA "Scheinwerferreinigungsanlage

derzeit nur bei PAG umgesetzt";
CM_ SG_ 980 WH_Tipwischen "Wischerhebel: Tippwischen

MQB A0/ PQ26: Bei Verbau LSS (kein SMLS): gespiegelter Wert zu Signal WH_WischerStufe1";
CM_ SG_ 980 WH_Tipwischen_lang "Wischerhebel: Tippwischen lang
(dient zur Auswertung für die Unterscheidung Tippwischen oder Serviceposition Wischer)";
CM_ SG_ 980 WH_Wischer_Fehler "Anzeige, ob am Lenkstockschalter ein Fehler anliegt.
Notwendig aufgrund ASIL-Einstufung";
CM_ SG_ 980 WH_WischerStufe1 "Wischerhebel: Stufe Wischen 1
";
CM_ SG_ 980 WH_WischerStufe2 "Wischerhebel: Stufe Wischen 2
";

CM_ SG_ 904 BugSp_AOCCT_Fehlerstatus "Berechnung ActiveOffCycleCreditTechnology: Bug-Spoiler Fehler";
CM_ SG_ 904 BugSp_AOCCT_Teststatus "Berechnung ActiveOffCycleCreditTechnology: Bug-Spoiler Diagnose durchgeführt";
CM_ SG_ 904 BugSp_AOCCT_timer1_count "Berechnung ActiveOffCycleCreditTechnology: Timer 1 für Bug-Spoiler Position <75%";
CM_ SG_ 904 BugSp_AOCCT_timer1_verbaut "Berechnung ActiveOffCycleCreditTechnology: Timer 1 für Bug-Spoiler verbaut und codiert";
CM_ SG_ 904 BugSp_AOCCT_timer2_count "Berechnung ActiveOffCycleCreditTechnology: Timer 2 für Bug-Spoiler Position >=75%";
CM_ SG_ 904 BugSp_AOCCT_timer2_verbaut "Berechnung ActiveOffCycleCreditTechnology: Timer 2 für Bug-Spoiler verbaut und codiert";
CM_ SG_ 904 HeckSp_AOCCT_Fehlerstatus "Berechnung ActiveOffCycleCreditTechnology: Heck-Spoiler Fehler";
CM_ SG_ 904 HeckSp_AOCCT_Teststatus "Berechnung ActiveOffCycleCreditTechnology: Heck-Spoiler Diagnose gelaufen";
CM_ SG_ 904 HeckSp_AOCCT_timer1_count "Berechnung ActiveOffCycleCreditTechnology: Timer 1 für Heck-Spoiler Position <75%";
CM_ SG_ 904 HeckSp_AOCCT_timer1_verbaut "Berechnung ActiveOffCycleCreditTechnology: Timer 1 für Heck-Spoiler verbaut und codiert";
CM_ SG_ 904 HeckSp_AOCCT_timer2_count "Berechnung ActiveOffCycleCreditTechnology: Timer 2 für Heck-Spoiler >=75%";
CM_ SG_ 904 HeckSp_AOCCT_timer2_verbaut "Berechnung ActiveOffCycleCreditTechnology: Timer 2 für Heck-Spoiler verbaut und codiert";
CM_ SG_ 904 LFE_Status "Anzeige des aktuellen Status der Lehnenfernentriegelung (entriegelt / verriegelt) im Kombi.";
CM_ SG_ 904 SpoilerSG_01_BZ "Botschaftszähler";
CM_ SG_ 904 SpoilerSG_01_CRC "Checksumme
End-to-End Kommunikationsabsicherung aufgrund FuSi-relevanter Signale";
CM_ SG_ 904 SpoilerSG_AeroZustand "Aerodynamischer Systemzustand aus Gesamtfahrzeugsicht als Information für die Fahrwerkregelsysteme";
CM_ SG_ 904 SpoilerSG_Anf_ESP_Zuschaltung "Anforderung der Zuschaltung eines deaktivierten ESP";
CM_ SG_ 904 SpoilerSG_Fehler "Anzeige einer Warnung oder Fehlers.";
CM_ SG_ 904 SpoilerSG_HSpoiler_IstPos "Aktuelle Istposition des Heckspoilers.";
CM_ SG_ 904 SpoilerSG_SKE_PosSens_Status "Status der Sensorik Kühlerjalousie";
CM_ SG_ 904 SpoilerSG_Status "Anzeige des aktuellen Status(eingefahren / ausgefahren) des Spoilers.";
CM_ SG_ 904 TE_TrunkEntrapment_Fehler "Fehler Signal für Trunk Entrapment Steuerung";

CM_ SG_ 1313 STH_EKP_Anst "STH sendet die Anforderung zur Ansteuerung der EKP an den Motor, um Kraftstoffbehälter der STH zu befüllen.";
CM_ SG_ 1313 STH_Fehler_ElWaPu "Fehler der el. Zusatzwasserpumpe der zur Deaktivierung der Wasserpumpe führt ";
CM_ SG_ 1313 STH_Fehlerstatus "Übermittlung der unterschiedlichen Fehlerzustände der Standheizung";
CM_ SG_ 1313 STH_Funk_aus "Funkbefehl über Funkfernbedienung zum Ausschalten Standheizung";
CM_ SG_ 1313 STH_Funk_ein "Funkbefehl über Funkfernbedienung zum Einschalten Standheizung";
CM_ SG_ 1313 STH_Geblaese "Ein-/ Ausschaltbefehl an die Klimaanlage, Gebläse";
CM_ SG_ 1313 STH_Heizleistung "Heizleistung in %";
CM_ SG_ 1313 STH_KL_HUP "Signal HUP Aktivierung an Klima

0 = HUP aus
1 = HUP ein";
CM_ SG_ 1313 STH_KVS "Kraftstoffverbrauch";
CM_ SG_ 1313 STH_KVS_Ueberlauf "Kraftstoffverbrauch, Überlauf hat stattgefunden";
CM_ SG_ 1313 STH_LED "Funktionslampe";
CM_ SG_ 1313 STH_Motorvorwaermung "Info an der Motor, dass der Aufheizvorgang mit Motorvorwärmung erfolgt ist";
CM_ SG_ 1313 STH_Pumpen_Anf_extern "Anforderung der motorseitigen elektr. (externen) Wasserpumpe zur Kreislaufunterstützung im Standheizbetrieb";
CM_ SG_ 1313 STH_Servicemode "Rückmeldung, dass die Standheizung sich gerade im Diagnosemodus befindet, gestartet über Diagnosetester";
CM_ SG_ 1313 STH_SH_ZH "0 = Heizgerät ist Standheizung
1 = Heizgerät ist Zuheizer
Gerätekennung WZH oder ZH
";
CM_ SG_ 1313 STH_Start_folgt "Thema Start/Stop: Im Stop-Modus muß das KBT einen Wiederstart anfordern, da ein STH-Start notwendig ist.";
CM_ SG_ 1313 STH_Texte "Anforderung der unterschiedlichen Anzeigetexte im Mitteldisplay des Kombi.

0: Keine Anzeige
1: Kein Standheizungs- bzw Lueftungsbetrieb wegen Batteriemanagementeinschraenkung
2: Kein Standheizungs- bzw Lueftungsbetrieb wegen Kraftstoffmangels
3: Kei";
CM_ SG_ 1313 STH_Ventil_Status "Statusrückmeldung Ansteuerung 3/2 Wege-Ventil";
CM_ SG_ 1313 STH_Ventiloeffnungszeit "Die Standheizung sendet an den Motor die Information darüber wie lange das Magnetventil die Wasserkreisläufe von 'klein' aus 'gross' geschaltet hat. ";
CM_ SG_ 1313 STH_Waermeeintrag "Signal enthält die Brenndauer in 1min-Schritten, über welche die Standheizung gelaufen ist";
CM_ SG_ 1313 STH_war_aktiv "Bit beeinhaltet die Info, dass die Standheizung während der letzten halbe Stunde aktiv war.";
CM_ SG_ 1313 STH_Wassertemp "Kühlmitteltemperatur der Standheizung";
CM_ SG_ 1313 STH_Zusatzheizung "Kraftstoffzuheizer aktiv";

CM_ SG_ 505 ACA_HF_Grund_AV_AB "Abschaltbedingung und Aktivierverhinderung";
CM_ SG_ 505 ACA_HF_Status "Status der Hands-Off-Querfuehrung";
CM_ SG_ 505 ACA_QF_Fahreruebernahme "Anforderung einer Fahrerübernhame durch die ACA Querführung für die HMI Ansteuerung im ACC-SG";
CM_ SG_ 505 ACA_QF_Status_Anzeige "Status der ACA Querführung, angepasst für die HMI Ansteuerung im ACC-SG";
CM_ SG_ 505 ACF_Spurwechsel_moeglich "Spurwechselmöglichkeit in Überholrichtung (verkehrssinnabh.) gegeben";
CM_ SG_ 505 ACF_Spurwechsel_wahrscheinlich "Spurwechsel in Überholrichtung (verkehrssinnabh.) wahrscheinlich";
CM_ SG_ 505 ACF_SwuFahrerUnaufmerksam "Erkannte Fahrerunaufmerksamkeit von der FZE (ACF)";
CM_ SG_ 505 FZE_Spurwechsel_erkannt_li "Spurwechsel nach links erkannt.";
CM_ SG_ 505 FZE_Spurwechsel_erkannt_re "Spurwechsel nach rechts erkannt.";
CM_ SG_ 505 FZE_STP_Abschaltbedingung "Es liegt eine FZE Bedienhandlung für eine Abschaltung vor";
CM_ SG_ 505 FZE_STP_Aktivierverhinderung "Aktivierverhinderungen STP aus Sicht der FZE";
CM_ SG_ 505 FZE_STP_Status "'Initialisierung / Auskodiert
FZE_STP Signale können verwendet werden
Es liegt ein reversibler Fehler für STP Signale vor
Es liegt ein irreversibler Fehler für STP Signale vor'
";
CM_ SG_ 505 STP_03_BZ "Botschaftszähler
Botschaft asynchron geroutet. Zählerwert kann springen.";
CM_ SG_ 505 STP_03_CRC "End-to-End Absicherung";
CM_ SG_ 505 STP_Funktion_freigegeben "Gibt in ASIL D an, ob die Funktion Staupilot zum Betrieb freigegeben ist.";
CM_ SG_ 505 STP_Notlaufaktivierung "Aktivierung des Notlaufs im ESC/EBKV durch den STP";
CM_ SG_ 505 STP_Slave_Status "Zustandsbeschreibung für STP-Slave-State-Machine";

CM_ SG_ 666 STP_Abstand_Zielobjekt "Signal dient zur Anzeige des Abstands des STP Zielobjekts im Kombi";
CM_ SG_ 666 STP_Egokolonne_ZA "Ansteuerung einer Anzeige der Fahrzeugkolonne auf der Egospur in der Zusatzanzeige";
CM_ SG_ 666 STP_FAS_Fkt_Status "Dient zur Interaktion mit dem FAS-Profilemaster. ";
CM_ SG_ 666 STP_FBM_links_ZA "Ansteuerung einer Anzeige der linken Fahrbahnmarkierung in der Zusatzanzeige";
CM_ SG_ 666 STP_FBM_rechts_ZA "Ansteuerung einer Anzeige der rechten Fahrbahnmarkierung in der Zusatzanzeige";
CM_ SG_ 666 STP_Geschw_Egofahrzeug_ZA "Zusatzinformation zur Anzeige des Fahrzeugs auf der Egospur in der Zusatzanzeige";
CM_ SG_ 666 STP_Nebenspur_Geschw_links_ZA "Anzeige von Seitenanimationen in der Kombi-Zusatzanzeige";
CM_ SG_ 666 STP_Nebenspur_Geschw_rechts_ZA "Anzeige von Seitenanimationen in der Kombi-Zusatzanzeige";
CM_ SG_ 666 STP_Nebenspur_links_ZA "Ansteuerung einer Anzeige von Objekten auf der linken Nebenspur in der Zusatzanzeige";
CM_ SG_ 666 STP_Nebenspur_rechts_ZA "Ansteuerung einer Anzeige von Objekten auf der rechten Nebenspur in der Zusatzanzeige";
CM_ SG_ 666 STP_Primaeranz_02 "Primaeranzeige des Staupiloten";
CM_ SG_ 666 STP_Status_Anzeige "Status nur zur Defintion von Anzeige im Kombi.";
CM_ SG_ 666 STP_Texte "Signal zur Ansteuerung von Warnungen und Fahrerhinweisen bzgl. des STP im Mitteldisplay";
CM_ SG_ 666 STP_Texte_AV "Grund der Aktivierverhinderung";
CM_ SG_ 666 STP_Texte_ESK "Grund der Eskalation";
CM_ SG_ 666 STP_Texte_ZA "Signal zur Ansteuerung eines Textes für Fahrerhinweise und bzgl. des STP-Systemzustands in der Zusatzanzeige";

CM_ SG_ 1172 GW_STS2_Privatsphaere "Übertraegt den Status der Privatsphaere vom ZR/MIB an das Steuergeraet VTS (STS2).";
CM_ SG_ 1172 STS_01_BZ "4bit Botschaftszähler, wird in jeder Sendebotschaft inkrementiert
";
CM_ SG_ 1172 STS_01_CRC "Für MLB:
'Berechnung siehe Lastenheft 'Kommunikationsabsicherung für FlexRay und CAN''

Ab MQB und MLBevo:
'Berechnung siehe Lastenheft 'End-to-End Kommunikationsabsicherung''

Endwerte siehe Begleitdokument 'S-PDU Kennungsfolgen'";
CM_ SG_ 1172 STS_Alarm_Blinker "Taxialarmblinken, wie DWA ohne Fanfare";
CM_ SG_ 1172 STS_Alarm_still "VTS hat einen Alarm erkannt. Alarm ist aber noch nicht bestätigt.";
CM_ SG_ 1172 STS_Anlassersperre "Wiederstartverhinderung (Anlassersperre)";
CM_ SG_ 1172 STS_Door_Lock "Remote Door lock angefordert: ZV zu/verriegeln";
CM_ SG_ 1172 STS_Fahrlicht "statisch oder auch mit Blink_modi für interm. Fahrlicht";
CM_ SG_ 1172 STS_Laderelais "Signal für die Auswertung zur Anzeige der Batterie-Schwach-Anzeige im Kombi ";
CM_ SG_ 1172 STS_Leerlaufschaltung "Versetzt das Fahrzeug in einen Zustand in dem es nicht mehr auf EGas-Anforderungen reagiert";
CM_ SG_ 1172 STS_LIN_aktiv "Tracking System über LIN";
CM_ SG_ 1172 STS_Notstart "Signal zeigt an, dass ein Notstart erfolgte.";
CM_ SG_ 1172 STS_Signalhorn "Versehrte, Fahrschule oder Taxi (bei Alarm)";
CM_ SG_ 1172 STS_Spiegel_Anklappen "Anklappen der Außenspiegel über Remote MOD Anforderung";
CM_ SG_ 1172 STS_Standlicht "statisch oder auch mit Blink_modi für Taxialarm";
CM_ SG_ 1172 STS_Summer "Warnsummer für Funkhauptschalter und Fahrschulpedal";
CM_ SG_ 1172 STS_Texte "Nummer des Textes die im Kombi angezeigt werden soll.

Signalwert ---- Meldungstext Audi ---- Meldungstext PAG:
0x0, kein_Text ---- kein Text ---- kein Text
0x1, Text_01 ---- kein Text ---- Driver Card nicht erkannt
0x2, Text_02 ---- Ortungsassistent";
CM_ SG_ 1172 STS_Typencodierung "Typcodierung Schnittstelle für Tracking Systeme
";

CM_ SG_ 783 ASW_Kombitexte "ASW_Kombitexte bestimmt welcher Text im Kombi angezeigt wird. Darüber hinaus werden auch Kombi-Akkustik durch dieses Signal ausgelöst.

Dieses Signal ersetzt SWA_Anzeigen für den ASW-Anteil. Der SWA-Anteil des alten Signals findet sich in SWA-Kombitexte";
CM_ SG_ 783 ASW_Modus "gibt die Verfügbarkeit der ASW Modus an";
CM_ SG_ 783 ASW_Status "Funktionsstatus Ausstiegswarnung (ASW)";
CM_ SG_ 783 ASW_Warnung_BFS "Modus Beifahrerseite der Funktion Ausstiegswarnung (ASW)";
CM_ SG_ 783 ASW_Warnung_FS "Modus Beifahrerseite der Funktion Ausstiegswarnung (ASW)";
CM_ SG_ 783 Heckradar_Kombitexte "Heckradar_Kombitexte bestimmt welcher Text im Kombi angezeigt wird. Darüber hinaus werden auch Kombi-Akkustik durch dieses Signal ausgelöst.

Dieses Signal ersetzt SWA_Anzeigen und deckt alle Kombinationsmöglichkeiten der Heckradarfunktionen ab. Die Fun";
CM_ SG_ 783 HRE_Anzeigetexte "HRE-Texte und -Akustik zur Anzeige im Kombiinstrument";
CM_ SG_ 783 RCTA_Kombitexte "RCTA_Kombitexte bestimmt welcher Text im Kombi angezeigt wird. Darüber hinaus werden auch Kombi-Akkustik durch dieses Signal ausgelöst.";
CM_ SG_ 783 SWA_01_BZ "Fehlende Beschreibung (Import)
Botschaft asynchron geroutet. Zählerwert kann springen.";
CM_ SG_ 783 SWA_01_CRC "Für MLB:
'Berechnung siehe Lastenheft 'Kommunikationsabsicherung für FlexRay und CAN''

Ab MQB und MLBevo:
'Berechnung siehe Lastenheft 'End-to-End Kommunikationsabsicherung''

Endwerte siehe Begleitdokument 'S-PDU Kennungsfolgen'";
CM_ SG_ 783 SWA_Anzeigen "SWA- Texte und -Akustik zur Anzeige im Kombiinstrument
0x7-0xF = reserviert";
CM_ SG_ 783 SWA_Blindheit_erkannt "SWA erkennt selbständig eigene Blindheit durch äußere Einflüsse.";
CM_ SG_ 783 SWA_FT_RueckLED "SWA/ASW Rückmelde-LED. Zeigt den Aktivierungszustand der Funktionen SWA/ASW";
CM_ SG_ 783 SWA_Infostufe_SWA_li "Aktion der SWA-Funktion auf der entsprechenden Fahrzeugseite";
CM_ SG_ 783 SWA_Infostufe_SWA_re "Aktion der SWA-Funktion auf der entsprechenden Fahrzeugseite";
CM_ SG_ 783 SWA_Kolonne_li "Info, dass auf der entspr. Spur mehr als zwei Fahrzeuge zu finden sind. ";
CM_ SG_ 783 SWA_Kolonne_mi "Info, dass auf der entspr. Spur mehr als zwei Fahrzeuge zu finden sind. ";
CM_ SG_ 783 SWA_Kolonne_re "Info, dass auf der entspr. Spur mehr als zwei Fahrzeuge zu finden sind. ";
CM_ SG_ 783 SWA_Modus "gibt die Verfügbarkeit der SWA Modus an";
CM_ SG_ 783 SWA_rel_Fehler "Hinweis: In Zukunft das Signal SWA_Modus anstatt SWA_rel_Fehler verwenden!

SWA erkennt einen Fehler, die Objektdetektion betreffend, mit FSP-Eintrag.";
CM_ SG_ 783 SWA_rel_Nichtverf "Hinweis: In Zukunft das Signal SWA_Modus anstatt SWA_rel_Nichtverf verwenden!

SWA erkennt eine Nichtverfuegbarkeit, die Objektdetektion betreffend, ohne FSP-Eintrag";
CM_ SG_ 783 SWA_Sta_aktiv "SWA Status aktiv; Lampenansteuerung im Kombi";
CM_ SG_ 783 SWA_Sta_passiv "Hinweis: In Zukunft das Signal SWA_Status anstatt SWA_Sta_passiv verwenden!

SWA Status passiv; Lampenansteuerung im Kombi";
CM_ SG_ 783 SWA_Standziele_li "Hinweis: In Zukunft das Signal SWA_StrukturLinks_querAbstand anstatt SWA_Standziele_li verwenden!

Abstand zwischen Fahrzeug und Standziele links geringer als ein applizierbarer Wert.";
CM_ SG_ 783 SWA_Standziele_re "Hinweis: In Zukunft das Signal SWA_StrukturRechts_querAbstand anstatt SWA_Standziele_re verwenden!

Abstand zwischen Fahrzeug und Standziele links geringer als ein applizierbarer Wert.";
CM_ SG_ 783 SWA_Status_02 "gibt die Verfügbarkeit der SWA_Status an";
CM_ SG_ 783 SWA_Warnung_SWA_li "Aktion der SWA-Funktion auf der entsprechenden Fahrzeugseite";
CM_ SG_ 783 SWA_Warnung_SWA_re "Aktion der SWA-Funktion auf der entsprechenden Fahrzeugseite";

CM_ SG_ 1413 GW_KD_Fehler "Kundendienstfehlerbit Gateway zur Anzeige eines im Gateway abgelegten Fehlerspeichereintrages.";
CM_ SG_ 1413 SI_BUS_01 "MQB/MQB_A0/PQ26: ACAN
MQB2020: ACAN(FD)
MLBevo: HCAN
E3_Volumen: ACAN(FD)
MQBw_Baseline: ACAN(FD)";
CM_ SG_ 1413 SI_BUS_02 "MQB/MQB A0 Standard+, High: FCAN
MQB2020: FCAN(FD)
MLBevo: Frei
E3_Volumen: FCAN(FD)
MQBw_Baseline: FCAN(FD)";
CM_ SG_ 1413 SI_BUS_03 "MQB/MQB A0/PQ26: KCAN
MQB2020: KCAN
MLBevo: KCAN
E3_Volumen: KCAN(HS) / K2CAN(FD) (Buskopplung)
MQBw_Baseline: KCAN(HS)";
CM_ SG_ 1413 SI_BUS_04 "MQB/MQB A0 Standard+, High: ICAN
MQB2020: ICAN(HS)
MLBevo: ICAN
E3_Volumen: ABCAN(FD)
MQBw_Baseline: ICAN(HS)";
CM_ SG_ 1413 SI_BUS_05 "MQB/MQB A0/PQ26: DiagCAN
MQB2020: DiagCAN(FD)
MLBevo: DiagCAN
E3_Volumen: DiagCAN(FD)
MQBw_Baseline: DiagCAN(FD)";
CM_ SG_ 1413 SI_BUS_06 "MQB/MQB A0/PQ26: ECAN
MQB2020: FASCAN(FD)
MLBevo: ECAN
E3_Volumen: FASCAN_1(FD)
MQBw_Baseline: FASCAN_1(FD)";
CM_ SG_ 1413 SI_BUS_07 "MQB: LIN1 (Energie)
MQB2020: LIN1 (Energie)
MLBevo: LIN1 (Energie)
E3_Volumen: LIN 1 (Energie)
MQBw_Baseline: LIN1 (Energie)";
CM_ SG_ 1413 SI_BUS_08 "MQB: LIN2 (MFL)
MQB2020: LIN2 (MFL)
MLBevo: LIN2 (MFL)
E3_Volumen: LIN2 (MFL)
MQBw_Baseline: LIN2 (MFL)";
CM_ SG_ 1413 SI_BUS_09 "MQB: LIN3 (unbelegt)
MQB2020: LIN3 (Uhr/FES)
MLBevo: LIN3 (Energie2)
MEB: LIN3
E³ 1.1 UNECE: MDKCAN";
CM_ SG_ 1413 SI_BUS_10 "MLBevo: Flexray
MQB2020: MCAN
MQBw_Baseline: FASCAN_2(FD)
E³ 1.1 UNECE: FASCAN_2(FD)";
CM_ SG_ 1413 SI_BUS_11 "MLBevo: Ethernet
MEB: LIN4";
CM_ SG_ 1413 SI_BUS_12 "MQB: unbelegt
MLBevo: K2CAN
E3_Volumen: MFLCAN
MQBw_Baseline: K2CAN(FD)";
CM_ SG_ 1413 SI_BUS_13 "MQB: unbelegt
MLBevo: DCAN
MEB: CCAN
MQBw_Baseline: K3CAN(FD)";
CM_ SG_ 1413 SI_BUS_14 "MQB/MQB A0: unbelegt
MQB2020: HCAN
MLBevo: CCAN
E3_Volumen: EVCAN(FD)
MQBw_Baseline: EVCANFD(FD)";
CM_ SG_ 1413 SI_BUS_15 "MQB: frei
MQB2020: frei
MLBevo: frei
MEB: AFSCAN";
CM_ SG_ 1413 SI_Bus_Identifikation "Das Signal identifiziert den Bus eindeutig. Das Signal ist konstant auf jedem Bus.
Der Signalwert entspricht dem Wert 'Busnummer' aus der VW80127 Gateway_component_list_databus_identification (0x2A2D) 'Bus-Identifier'.";
CM_ SG_ 1413 SI_CAB "CAB = Clusteraktivbits 
(Verwendung nur für Empfänger die nicht den AutoSar-SSW Stack implementiert haben)";
CM_ SG_ 1413 SI_Diagnose_Aktiv "Gibt an ob Diagnose-Botschaften empfangen werden und somit eine Diagnose aktiv ist.
MQB: Gibt an ob Diagnose-Bus Botschaften empfangen werden und somit eine Diagnose aktiv ist.";
CM_ SG_ 1413 SI_NWDF "Netzwerk-Diagnose Freigebe zur zentralen Aktivierung der Netzwerkdiagnose";
CM_ SG_ 1413 SI_NWDF_gueltig "Gültigkeitsbit zu SI_NWDF gemäß Lastenheft: Zentrale Aktivierung Netzwerkdiagnose";
CM_ SG_ 1413 SI_QRS_Mode "Messmodus Quick-Ruhestrom";
CM_ SG_ 1413 SI_Sammel_SG_Fehler "Anzahl der gesetzten KD-Fehler direkt angeschlossener Steuergeräte der DK3 und DK4 gemäß 80127.
Hinweis: Ein Subbusmaster stellt nur die gesammelte Information der an ihn angeschlossenen Steuergeräte der DK3 und DK4 zur Verfügung.

Für ServiceKey Auswe";
CM_ SG_ 1413 SI_Sammelfehler "Sammelfehlermeldung zur Anzeige im Kombi - siehe Spez. Sammelfehlermeldung
Hinweis: Einzelne Steuergeräte können zur Anpassung an den Produktionsprozess im Gateway auskodiert werden!";
CM_ SG_ 1413 SI_T_Mode "0x0: Transportmodus nicht aktiv
0x1: Transportmodus aktiv";
CM_ SG_ 1413 SI_T_Schutz "Transportschutz-Signal, das bei Transportmodus und Motorlauf aktiv bleibt
0x0: Transportschutz nicht aktiv
0x1: Transportschutz aktiv";

CM_ SG_ 619 TA_aktiv_HMI "Signalwert an Anzeigegerät welche Funktion aktiv";
CM_ SG_ 619 TA_Fehler "Fehler im Modus Travel Assist";
CM_ SG_ 619 TA_FoD_Status "TAwird durch FoD geschützt sein und so reicht die PR/Zieldatencontainer basierte Codierung nicht mehr aus.

Aus diesem Grund brauch wir ein separates Signal, dass uns den Freischaltezustand mitteilt.";

CM_ SG_ 1604 TG_Geber_1 "Rohwert der Tankgeber";
CM_ SG_ 1604 TG_Geber_2 "Rohwert der Tankgeber";
CM_ SG_ 1604 TG_Geber_3 "Rohwert der Tankgeber";
CM_ SG_ 1604 TG_Geber_4 "Rohwert der Tankgeber";
CM_ SG_ 1604 TG_Guete_Geber_1 "Güte-Information der Rohwerte der Tankgeber";
CM_ SG_ 1604 TG_Guete_Geber_2 "Güte-Information der Rohwerte der Tankgeber";
CM_ SG_ 1604 TG_Guete_Geber_3 "Güte-Information der Rohwerte der Tankgeber";
CM_ SG_ 1604 TG_Guete_Geber_4 "Güte-Information der Rohwerte der Tankgeber";

CM_ SG_ 1001 Thermo_Pred_Innen_Kunde_Anf "Änderung der Prädiktion iniziiert durch Kundenaktion";
CM_ SG_ 1001 Thermo_Pred_Innen_System_Anf "Systemseitig initiierte Änderung der Prädiktion; Signal ist einheitsloser Zähler mit Überlauf. 
Eine Inkrementierung steht für die Änderung der Umgebungsbedingungen mit dazugehöriger Klimaleistungsänderung.";
CM_ SG_ 1001 Thermo_Pred_P_dyn_Innen "Dynamsiche Leistung für Headup / Cooldown";
CM_ SG_ 1001 Thermo_Pred_P_stat_Innen "Stationäre Leistung für Heizen / Kühlen";
CM_ SG_ 1001 Thermo_Pred_T_dyn_Innen "Zeit bis zum Übergang vom dynamischen in stationären Betrieb";
CM_ SG_ 1001 Thermo_Verbrauch_BTL "Verbrauch für Heizen und Kühlen der Bauteile";
CM_ SG_ 1001 Thermo_Verbrauch_BTL_Ueberlauf "Überlauf-Bit Verbrauch Bauteil";
CM_ SG_ 1001 Thermo_Verbrauch_Innen "Verbrauch für Heizen und Kühlen Innenraum";
CM_ SG_ 1001 Thermo_Verbrauch_Innen_Ueberlauf "Überlauf-Bit Verbrauch Innenraum";

CM_ SG_ 1375 TME_Absperrventil1_oeffnen "Signal an Standheizungs-SG das Absperrrventil anzusteuern";
CM_ SG_ 1375 TME_AC_LED "Steuerung der LED in der AC-Taste des KBTs";
CM_ SG_ 1375 TME_AC_Rueckmeldung "Status des Elektrischen Klimakompressors";
CM_ SG_ 1375 TME_Freigabe_Luft_PTC "Freigabe des Zuheizers im Klimagerät";
CM_ SG_ 1375 TME_Freigabe_Vorkond "Freigabe an das KBT, mit dem Innenraumkonditionieren zu beginnen.";
CM_ SG_ 1375 TME_Frischluftklappe_Soll "Sollvorgabe der Frischluftklappenstellung bei speziellem Heizbetrieb, z.B. Wärmepumpe";
CM_ SG_ 1375 TME_Heizstrategie "Info über aktuelle Heizstrategie an KBT";
CM_ SG_ 1375 TME_Heizungspumpen_Anst "Anforderung Heizungspumpenansteuerung";
CM_ SG_ 1375 TME_Kbr_Innenraum "Vorhandensein der Klimabereitschaft für Innenraum";
CM_ SG_ 1375 TME_Klima_Defizit "Für Innennraumklimatisierung aktuell nicht verfügbare  Leistung (Defizit = Istleistung - Solleistung)";
CM_ SG_ 1375 TME_Kuehlmittel_Sensor "Signal der Sensorelektroden für die Kühlmittelreserve aktuell, entstört, bewertet (OK/Mangel)
Signalaenderung BEV: Zusaetzlich zum Kuehlmittelsensor werden Fehler an Wasserpumpe des Kuehlsystems auf das Fehlerbit gemappt.";
CM_ SG_ 1375 TME_Nachlaufzeit_Heizp "Nachlaufzeit für Heizungspumpe";
CM_ SG_ 1375 TME_Systemstatus "Systemstatus der TME";
CM_ SG_ 1375 TME_Temp_KM_vor_HWT "Kühlmitteltemperatur vor HWT";
CM_ SG_ 1375 TME_Umluftklappe_Soll "Sollvorgabe der Umluftklappenstellung bei speziellem Heizbetrieb, z.B. Wärmepumpe";
CM_ SG_ 1375 TME_Verdampfer_Status "Verdampfer wird vom Kältemittel durchströmt";
CM_ SG_ 1375 TME_VoKo_Strategie_Anzeige "rueckgemeldete VoKo-Strategie fuer Anzeige
";
CM_ SG_ 1375 TME_Waermepumpe_aktiv "Aktivierungszustand der Wärmepumpe für Innenraumheizen";
CM_ SG_ 1375 TME_Zuheizer_Freigabe "Freigabe-Signal für Verbrennungszuheizfunktion";

CM_ SG_ 1657 TME_Eingriff_SKE_Oeffnung "TME Anforderung zur Öffnung der SKE";
CM_ SG_ 1657 TME_EKK_ProtectionMode "Bei akuter Ueberhitzungsgefahr des elektrischen Klimakompressors wird der ProtectionMode aktiviert.";
CM_ SG_ 1657 TME_Klimaanforderung "Anforderungsgrund der Klimaapplikation durch die TME";
CM_ SG_ 1657 TME_Klimaleistung "Leistung des elektrischen Klimakompressors";
CM_ SG_ 1657 TME_SKE_Pos_Summe "Aerodynamisch wirksamer Gesamtöffnungswinkel der am TME angeschlossenen Kühlerjalousiesteller.";
CM_ SG_ 1657 TME_SKE_Position_1 "Position der SKE 1

0 => Geöffnet
1 => Teilgeschlossen
2 => Geschlossen
3 => Init / Anforderung Initialisierung / Anforderung Referenzierung / Fehler heilen";
CM_ SG_ 1657 TME_SKE_PosResp "Rückmeldung SKE Position erreicht";
CM_ SG_ 1657 TME_SKE_Status "Status Information über den Zustand der SKE";
CM_ SG_ 1657 TME_Status_Kuehlmittel_Tmp_CrChk "Status des Cross Checks der Kuehlmitteltemperaturen von TME und MSG";
CM_ SG_ 1657 TME_Systemtemp "Systemtemperatur Antriebe für Kombi";
CM_ SG_ 1657 TME_TCP_Kond_active "Info über eine aktive HV-Batterie Konditionierung welche durch den Turbo Charging Planer ausgelöst wurde";
CM_ SG_ 1657 TME_Temp_KM_nach_EM "Momentanwert Kuehlmitteltemperatur nach E-Maschine";
CM_ SG_ 1657 TME_Temp_KM_vor_eATL "Kühlwassertemperatur vor eATL";
CM_ SG_ 1657 TME_Temperatur_Ruecklauf_VKM "Kühlmitteltemperatur Rücklauf VKM";
CM_ SG_ 1657 TME_Waermebilanz "TME bilanziert die Wärmeentnahme aus VKM";
CM_ SG_ 1657 TME_Waermebilanz_Status "Diagnosestatus zur Wärmebilanz. OBDI berücksichtigt die elektrischen Diagnosen. OBDII berücksichtigt die funktionalen Diagnosen bzw. Sensorwertplausibilisierung.";

CM_ SG_ 2527679762 TPUI_WarnLvlCmft "Display warning level for comfort pressure warning";
CM_ SG_ 2527679762 TPUI_WarnLvlMaxV "Display warning level for maxSpeed warning";

CM_ SG_ 977 ASW_Warnung_aktiv_BFS "Abschaltung der Ambientefunktion Beifahrertür bei aktiver ASW Warnung an der Fahrertür";
CM_ SG_ 977 BFS_Status_eTAG "Status des elektrischen Tueraussengriffes Beifahrertuer";
CM_ SG_ 977 BT_ASW_HMI_defekt "Zeigt an, ob die ASW-Anzeige defekt ist.";
CM_ SG_ 977 BT_EC_Spiegel_Helligkeit "Dimmung für den Aussenspiegel in %";
CM_ SG_ 977 BT_FH_Bew_hoch "Fensterheber in Bewegung Richtung hoch";
CM_ SG_ 977 BT_FH_Bew_tief "Fensterheber in Bewegung Richtung tief";
CM_ SG_ 977 BT_FH_Block "Fensterscheibe befindet sich im mechanischen Block (oben oder unten)";
CM_ SG_ 977 BT_FH_Fang "Fangbereich ist 4mm von oberer Lippendichtung";
CM_ SG_ 977 BT_FH_normiert "Die Position der Fensterheberscheibe ist bekannt";
CM_ SG_ 977 BT_FH_Oeffnung "Gibt den Fensteröffnungswert in % an.";
CM_ SG_ 977 BT_FH_S_AutoHoch "FH Schalter automatisch hoch gedrückt";
CM_ SG_ 977 BT_FH_S_AutoTief "FH Schalter automatisch tief gedrückt";
CM_ SG_ 977 BT_FH_S_ManHoch "FH Schalter manuell hoch gedrückt";
CM_ SG_ 977 BT_FH_S_ManTief "FH Schalter manuell tief gedrückt";
CM_ SG_ 977 BT_FH_Thermo "gibt an ob Fensterheber im Thermoschutz ist";
CM_ SG_ 977 BT_gesafet "Im Zustand Safe wird auch das Signal BT_verriegelt = 1 gesendet";
CM_ SG_ 977 BT_Kisi_Fehler "Fehlerstatus Kindersicherungsfunktion";
CM_ SG_ 977 BT_Lock_Taster "Verriegelungstaster";
CM_ SG_ 977 BT_Lock_Taster_inv "Lock Taster nicht betätigt";
CM_ SG_ 977 BT_Oben_Block_erw "Fensterheber in Blockerwartung oben";
CM_ SG_ 977 BT_Schluesselschalter_auf "Schlüsselschalter Richtung auf betätigt";
CM_ SG_ 977 BT_Schluesselschalter_zu "Schluesselschalter Richtung zu betaetigt";
CM_ SG_ 977 BT_Schluesselschalter_zu_inv "Schluesselschalter zu nicht betaetigt";
CM_ SG_ 977 BT_SP_ausgerastet "Spiegel ausgerastet";
CM_ SG_ 977 BT_Sp_Blk_def "Blinker am Spiegel defekt";
CM_ SG_ 977 BT_Sp_Heizung_Anf "Kundenanforderung der Außenspiegelheizung Beifahrertür";
CM_ SG_ 977 BT_SP_Heizung_Status "Status der Spiegelheizung";
CM_ SG_ 977 BT_SP_ht_aktiv "Spiegelverstellung in Richtung hoch/tief aktiv";
CM_ SG_ 977 BT_SP_lr_aktiv "Spiegelverstellung in Richtung links/rechts aktiv";
CM_ SG_ 977 BT_Sperrklinke "Vorraste für Schloß

zwischen Vor- und Hauptraste Signal kurz auf 1, danach wieder auf 0 wenn Tür in Hauptraste (Tür ist sicher zu wenn Sperrklinke und Türkontakt auf 0 sind)";
CM_ SG_ 977 BT_SWA_HMI_defekt "Zeigt an, ob die SWA-Anzeige defekt ist.";
CM_ SG_ 977 BT_TAG_betaetigt "Türaussengriff";
CM_ SG_ 977 BT_TCR_Mode_aktiv "Signal zeigt eine aktive mechanische Redundanz am Türschloss an.";
CM_ SG_ 977 BT_TIG_betaetigt "Türinnengriff";
CM_ SG_ 977 BT_Tuer_geoeffnet "Zeigt eine geöffnete Tür an";
CM_ SG_ 977 BT_Tuer_Status "Türstatus mit Fehler und Initwert";
CM_ SG_ 977 BT_Tuer_Status_QBit "Dieses Bit gibt die Zuverlässigkeit des Türkontakts an. Ein auf dieses Bit folgender Fehlereintrag ist mit dem Sender des Bits abzustimmen (gültig ab PPE).";
CM_ SG_ 977 BT_Tueroeffnen_Warnung "Bit wird gesetzt, wenn Tür während der Fahrt geoeffnet werden soll.";
CM_ SG_ 977 BT_Tuerschloss_defekt "Das Beifahrertürschloss ist nicht mehr funktionsfähig.";
CM_ SG_ 977 BT_UEKB_aktiviert "Überschutzbegrenzungskraft bei Reversieren";
CM_ SG_ 977 BT_Unlock_Taster "Entriegelungstaster betätigt";
CM_ SG_ 977 BT_Unten_Block_erw "Fensterheber in Blockerwartung unten";
CM_ SG_ 977 BT_verriegelt "Zeigt eine verriegelte Tür an ( Status wird erst nach vollständiger Schlossansteuerung ausgegeben (<=1,5sek))";
CM_ SG_ 977 BT_Zuziehhilfe_aktiv "Zuziehhilfe aktiv";

CM_ SG_ 976 ASW_HMI_defekt "HMI Status der Funktion AusstiegsWarnung (ASW). HMI wird durch das TSG angesteuert.";
CM_ SG_ 976 ASW_wakeup "Trigger Start Nachlaufzeit t_1 für die Funktion Ausstieswarnung (ASW)";
CM_ SG_ 976 ASW_Warnung_aktiv_FS "Abschaltung der Ambientefunktion Fahrertür bei aktiver ASW Warnung an der Fahrertür";
CM_ SG_ 976 FS_Status_eTAG "Status des elektrischen Tueraussengriffes Fahrertuer";
CM_ SG_ 976 FT_BFS_Fond_Freigabe "Freigabe für Fondverstellung";
CM_ SG_ 976 FT_Daemmglas "Daemmglas verbaut";
CM_ SG_ 976 FT_FH_Bew_hoch "Fensterheber in Bewegung Richtung hoch";
CM_ SG_ 976 FT_FH_Bew_tief "Fensterheber in Bewegung Richtung tief";
CM_ SG_ 976 FT_FH_Block "Fensterscheibe befindet sich im mechanischen Block (oben oder unten)";
CM_ SG_ 976 FT_FH_Fang "Fangbereich ist 4mm von oberer Lippendichtung";
CM_ SG_ 976 FT_FH_normiert "Die Position der Fensterheberscheibe ist bekannt";
CM_ SG_ 976 FT_FH_Oeffnung "Gibt den Fensteröffnungswert in % an.";
CM_ SG_ 976 FT_FH_S_AutoHoch "FH Schalter automatisch hoch gedrückt";
CM_ SG_ 976 FT_FH_S_AutoTief "FH Schalter automatisch tief gedrückt";
CM_ SG_ 976 FT_FH_S_ManHoch "FH Schalter manuell hoch gedrückt";
CM_ SG_ 976 FT_FH_S_ManTief "FH Schalter manuell tief gedrückt";
CM_ SG_ 976 FT_FH_Thermo "gibt an ob Fensterheber im Thermoschutz ist";
CM_ SG_ 976 FT_gesafet "Im Zustand Safe wird auch das Signal FT_verriegelt = 1 gesendet";
CM_ SG_ 976 FT_HD_Taste "Taste in der Fahrertür zum Öffnen des Heckschlosses";
CM_ SG_ 976 FT_HD_Taste_2 "2. HD-Taste im Bedienfeld 
Funktion: Heckdeckel schließen";
CM_ SG_ 976 FT_IRUE_Taste "Betätigung IRUE-Taster (Innenraumüberwachung)
MQB: Bei Verbau eines einzelnen Taster zur Deaktivierung von IRUE und NGS wird dieses Signal als Deaktivierungsanforderung beider DWA-Alarmquellen gesendet.";
CM_ SG_ 976 FT_Kisi_Fehler "Fehlerstatus Kindersicherungsfunktion";
CM_ SG_ 976 FT_Kisi_li_aktiv "Aktivierungsstatus der Kindersicherung links";
CM_ SG_ 976 FT_Kisi_re_aktiv "Aktivierungsstatus der Kindersicherung rechts";
CM_ SG_ 976 FT_Kisi_Taster_li "Linker Kisi Taster betaetigt";
CM_ SG_ 976 FT_Kisi_Taster_re "Rechter Kisi Taster betaetigt";
CM_ SG_ 976 FT_Lock_Taster "Verriegelungstaster betätigt";
CM_ SG_ 976 FT_Oben_Block_erw "Fensterheber in Blockerwartung oben";
CM_ SG_ 976 FT_Schliesstaster "Vorhalt";
CM_ SG_ 976 FT_Schluesselschalter_auf "Schlüsselschalter Richtung auf betätigt";
CM_ SG_ 976 FT_SP_ausgerastet "Spiegel ausgerastet";
CM_ SG_ 976 FT_Sp_Blk_def "Blinker am Spiegel defekt";
CM_ SG_ 976 FT_Sp_Heizung_Anf "Kundenanforderung der Außenspiegelheizung Fahrertür";
CM_ SG_ 976 FT_SP_Heizung_Status "Status der Spiegelheizung";
CM_ SG_ 976 FT_SP_ht_aktiv "Spiegelverstellung in Richtung hoch/tief aktiv";
CM_ SG_ 976 FT_SP_lr_aktiv "Spiegelverstellung in Richtung links/rechts aktiv";
CM_ SG_ 976 FT_Sperrklinke "Vorraste für Schloß

zwischen Vor- und Hauptraste Signal kurz auf 1, danach wieder auf 0 wenn Tür in Hauptraste (Tür ist sicher zu wenn Sperrklinke und Türkontakt auf 0 sind)";
CM_ SG_ 976 FT_SWA_Taster "SWA/ASW Taster Fahrertür";
CM_ SG_ 976 FT_TAG_betaetigt "Türaussengriff

wird nicht im MLB-B8 verwendet";
CM_ SG_ 976 FT_TD_Taste "Tankdeckelentriegelungs-Taste betätigt";
CM_ SG_ 976 FT_TD_Taste_Fehler "Fehlerstatus des Tankdeckelentriegelungstasters. Wird bei Drucktankkonzepten vom MSG zusammen mit dem Signal FT_TD_Taste ausgewertet, um Tankbereitschaft herzustellen.
Der Fehler beschreibt einen hängenden TD_Taster. Ein Kurzschluss oder Leitungsunterbre";
CM_ SG_ 976 FT_TIG_betaetigt "Türinnengriff

wird nicht im MLB-B8 verwendet";
CM_ SG_ 976 FT_Tuer_geoeffnet "Zeigt eine geöffnete Tür an";
CM_ SG_ 976 FT_Tuerschloss_defekt "Das Fahrertürschloss ist nicht mehr funktionsfähig.";
CM_ SG_ 976 FT_UEKB_aktiviert "Überschutzbegrenzungskraft bei Reversieren";
CM_ SG_ 976 FT_Unlock_Taster "Entriegelungstaster betätigt";
CM_ SG_ 976 FT_Unten_Block_erw "Fensterheber in Blockerwartung unten";
CM_ SG_ 976 FT_verriegelt "Zeigt eine verriegelte Tür an ( Status wird erst nach vollständiger Schlossansteuerung ausgegeben (<=1,5sek))";
CM_ SG_ 976 FT_Zuziehhilfe_aktiv "Zuziehhilfe aktiv";
CM_ SG_ 976 SSR_Temp_Freigabe "Freigabe des Seitenscheibenrollos. Bit wird  für die Deaktivierung des SSR bei Innenraumtemperaturen kleiner -10 Grad verwendet.";
CM_ SG_ 976 SWA_HMI_Diagnose "SWA HMI Diagnose beim TSG";

CM_ SG_ 997 FS_Push_Tuergriff "Push zum Ausfahren der Flush-Tuergriffe";
CM_ SG_ 997 FT_BFS_Tuer_Status "Gesammelte Türstatusbotschaft";
CM_ SG_ 997 FT_HBFS_Tuer_Status "Türstatus mit Fehler und Initwert";
CM_ SG_ 997 FT_HFS_Tuer_Status "Türstatus mit Fehler und Initwert";
CM_ SG_ 997 FT_Kisi_Taster_li_02 "Der Kindersicherungstaster hinten links aktiv.";
CM_ SG_ 997 FT_Kisi_Taster_re_02 "Der Kindersicherungstaster hinten rechts aktiv.";
CM_ SG_ 997 FT_Lock_Taster_02 "Lock-Taster betätigt";
CM_ SG_ 997 FT_Schluesselschalter_zu_02 "Schlüsselschalter für Schließen betätigt";
CM_ SG_ 997 FT_SP_Heizung_ein "Dieses Signal zeigt die tatsächliche Ansteuerung der  Spiegelheizung incl. PWM an. 
Zudem wird aufgrund des Teilnetzbetriebs das Signal zur Ansteuerung der Beifahrer-Spiegelheizung benutzt.

";
CM_ SG_ 997 FT_TCR_Mode_aktiv "Signal zeigt eine aktive mechanische Redundanz am Türschloss an.";
CM_ SG_ 997 FT_TD_Taste_Status "Status Taste für Tankdeckel";
CM_ SG_ 997 FT_Tuer_Status "Tür geöffnet oder Tür geschlossen";
CM_ SG_ 997 FT_Tuer_Status_QBit "Dieses Bit gibt die Zuverlässigkeit des Türkontakts an.";
CM_ SG_ 997 FT_Tueroeffnen_Warnung "Bit wird gesetzt, wenn Tür während der Fahrt geoeffnet werden soll.";
CM_ SG_ 997 TSG_FT_02_BZ "4bit Botschaftszaehler, wird mit jeder Sendebotschaft inkrementiert";
CM_ SG_ 997 TSG_FT_02_CRC "Für MLB:
'Berechnung siehe Lastenheft 'Kommunikationsabsicherung für FlexRay und CAN''

Ab MQB und MLBevo:
'Berechnung siehe Lastenheft 'End-to-End Kommunikationsabsicherung''

Endwerte siehe Begleitdokument 'S-PDU Kennungsfolgen'";

CM_ SG_ 975 ASW_Warnung_aktiv_HBFS "Abschaltung der Ambientefunktion Tür hinten der Beifahrerseite bei aktiver ASW Warnung an der Fahrertür";
CM_ SG_ 975 HBFS_FH_Bew_hoch "HBFS Fenster bewegt sich in Richtung hoch";
CM_ SG_ 975 HBFS_FH_Bew_tief "HBFS Fenster bewegt sich in Richtung tief";
CM_ SG_ 975 HBFS_FH_Block "Fensterscheibe befindet sich im mechanischen Block (oben oder unten)";
CM_ SG_ 975 HBFS_FH_Fang "Fangbereich ist 4mm von oberer Lippendichtung";
CM_ SG_ 975 HBFS_FH_normiert "Die Position der Fensterheberscheibe ist bekannt.";
CM_ SG_ 975 HBFS_FH_Oeffnung "Gibt den Fensteröffnungswert in % an.";
CM_ SG_ 975 HBFS_FH_S_AutoHoch "Betaetigung FH Schalter auto tief ";
CM_ SG_ 975 HBFS_FH_S_AutoTief "Betaetigung FH Schalter auto hoch";
CM_ SG_ 975 HBFS_FH_S_HFS_AutoHoch "Automatisches Hochfahren der Seitenscheibe HFS";
CM_ SG_ 975 HBFS_FH_S_HFS_AutoTief "Automatisches Absenken der Seitenscheibe HFS";
CM_ SG_ 975 HBFS_FH_S_HFS_ManHoch "Manuelles Hochfahren der Seitenscheibe HFS";
CM_ SG_ 975 HBFS_FH_S_HFS_ManTief "Manuelles Absenken der Seitenscheibe HFS";
CM_ SG_ 975 HBFS_FH_S_ManHoch "Betaetigung FH Schalter man hoch ";
CM_ SG_ 975 HBFS_FH_S_ManTief "Betaetigung FH Schalter man tief";
CM_ SG_ 975 HBFS_FH_Thermo "gibt an ob Fensterheber im Thermoschutz ist";
CM_ SG_ 975 HBFS_gesafet "HBFS Tuer gesafet.
Im Zustand Safe wird auch das Signal HBFS_verriegelt = 1 gesendet.";
CM_ SG_ 975 HBFS_Heckrollotaster_betaetigt "Verfahren des Heckrollos in Richtung Hoch

Bei Einfachtaster wird Bit als Togglebit verwendet (Heckrollo hoch, tief)";
CM_ SG_ 975 HBFS_Lock_Taster "Betaetigung Lock-Taster";
CM_ SG_ 975 HBFS_Lock_Taster_inv "Lock Taster nicht betätigt";
CM_ SG_ 975 HBFS_MRollo_Schalter "  | MRollo2
-----------------------------
0 | nicht_betaetigt
1 | (m) Zu
2 | (a) Zu
3 | (m) Auf
4 | (a) Auf
5 | Schalter nicht verfuegbar
6 | Init
7 | Fehlerfall";
CM_ SG_ 975 HBFS_Oben_Block_erw "Fensterheber in Blockerwartung oben";
CM_ SG_ 975 HBFS_SAD_Schalter "  |   Ausstelldach MD3
-----------------------------
0 | nicht_betaetigt
1 |
2 |
3 |
4 |
5 | (m) Auf
6 | (a) Auf
7 | (m) Zu
8 | (a) Zu
13| Schalter nicht verfuegbar
14| Init
15| Fehlerfall";
CM_ SG_ 975 HBFS_Seitenrollo_tief "Seitenrollo in Bewegung Richtung tief";
CM_ SG_ 975 HBFS_Sperrklinke "Vorraste für Schloß

zwischen Vor- und Hauptraste Signal kurz auf 1, danach wieder auf 0 wenn Tür in Hauptraste (Tür ist sicher zu wenn Sperrklinke und Türkontakt auf 0 sind)";
CM_ SG_ 975 HBFS_Status_eTAG "Status des elektrischen Tueraussengriffes Tuer Beifahrerseite hinten";
CM_ SG_ 975 HBFS_Status_KiSi "Status Kindersicherung HBFS
";
CM_ SG_ 975 HBFS_Status_KiSi_inv "Inverser Status der elektrischen Kindersicherung Beifahrerseite hinten";
CM_ SG_ 975 HBFS_TAG_betaetigt "Betaetigung Türaussengriff";
CM_ SG_ 975 HBFS_TIG_betaetigt "Betaetigung Tuerinnengriff";
CM_ SG_ 975 HBFS_TIG_betaetigt_schliessen "Türinnenbetätigung, Taster Tür schließen.";
CM_ SG_ 975 HBFS_Tuer_geoeffnet "HBFS Tuer geoeffnet";
CM_ SG_ 975 HBFS_Tuer_Status "Türstatus mit Fehler und Initwert";
CM_ SG_ 975 HBFS_Tuer_Status_QBit "Dieses Bit gibt die Zuverlässigkeit des Türkontakts an. Ein auf dieses Bit folgender Fehlereintrag ist mit dem Sender des Bits abzustimmen (gültig ab PPE).";
CM_ SG_ 975 HBFS_Tueroeffnen_Warnung "Bit wird gesetzt, wenn Tür während der Fahrt geoeffnet werden soll.";
CM_ SG_ 975 HBFS_Tuerschloss_defekt "Das hintere Tuerschloss auf der Beifahrerseite ist nicht mehr funktionsfähig.";
CM_ SG_ 975 HBFS_UEKB_aktiviert "Überschutzbegrenzungskraft bei Reversieren";
CM_ SG_ 975 HBFS_Unlock_Taster "Betaetigung Unlock Taster";
CM_ SG_ 975 HBFS_Unten_Block_erw "Fensterheber in Blockerwartung unten";
CM_ SG_ 975 HBFS_verriegelt "Verriegelungsstatus Tür";
CM_ SG_ 975 HBFS_Zuziehhilfe_aktiv "Zuziehhilfe aktiv";
CM_ SG_ 975 MTHBFS_M_Taste "Betätigung M-Taste HBFS";
CM_ SG_ 975 MTHBFS_Pos1 "Betätigung Postionstaste 1 HBFS";
CM_ SG_ 975 MTHBFS_Pos2 "Betätigung Postionstaste 2 HBFS
";
CM_ SG_ 975 MTHBFS_Pos3 "Betätigung Postionstaste 3 HBFS";
CM_ SG_ 975 SSR_HBFS_Pos_Unten "Signal für die 'Global Close'. Über dieses Bit wissen die anderen TSGs, ob der SSR oder der FH verfahren werden darf.";

CM_ SG_ 703 HBFS_Push_Tuergriff "Push zum Ausfahren der Flush-Tuergriffe";
CM_ SG_ 703 HBFS_Status_KiSi "Status Kindersicherung HBFS
";
CM_ SG_ 703 HBFS_TCR_Mode_aktiv "Signal zeigt eine aktive mechanische Redundanz am Türschloss an.";
CM_ SG_ 703 TSG_HBFS_02_BZ "4bit Botschaftszähler, wird mit jeder Sendebotschaft inkrementiert";
CM_ SG_ 703 TSG_HBFS_02_CRC "Für MLB:
Berechnung siehe Lastenheft 'Kommunikationsabsicherung für FlexRay und CAN'
Ab MQB und MLBevo:
Berechnung siehe Lastenheft 'End-to-End Kommunikationsabsicherung'

Endwerte siehe Begleitdokument 'S-PDU Kennungsfolgen'";
BA_DEF_REL_ BU_SG_REL_  "GenSigTimeoutTime" INT 0 65535;
BA_DEF_ BO_  "DiagRequest" ENUM "No", "Yes";
BA_DEF_ BO_  "DiagResponse" ENUM "No", "Yes";
BA_DEF_ BO_  "DiagState" ENUM "No", "Yes";
BA_DEF_ BO_  "GenMsgChkConstant" HEX 0 4095;
BA_DEF_ BO_  "GenMsgCycleTime" INT 0 65535;
BA_DEF_ BO_  "GenMsgCycleTimeFast" INT 0 65535;
BA_DEF_ BO_  "GenMsgDelayTime" INT 0 100000;
BA_DEF_ BO_  "GenMsgILSupport" ENUM "No", "Yes";
BA_DEF_ BO_  "GenMsgNrOfRepetition" INT 0 100;
BA_DEF_ BO_  "GenMsgPDUConstants" STRING;
BA_DEF_ BO_  "GenMsgSendType" ENUM "Cyclic", "not_used", "not_used", "not_used", "not_used", "not_used", "not_used", "IfActive", "NoMsgSendType";
BA_DEF_ BO_  "GenMsgStartDelayTime" INT 0 100000;
BA_DEF_ BO_  "NmMessage" ENUM "No", "Yes";
BA_DEF_ BO_  "NmhMessage" ENUM "No", "Yes";
BA_DEF_ BO_  "MsgType" ENUM "Application", "NM ", "NMH", "TP2.0", "ISO-TP ", "BAP", "EID", "KS", "XCP_PRE_CONFIGURED", "XCP_RUNTIME_CONFIGURED";
BA_DEF_ BO_  "VAGTP20_API" HEX 0 255;
BA_DEF_ BO_  "VAGTP20_DynConnection" ENUM "No", "Yes";
BA_DEF_ BO_  "VAGTP20_DynSetup" ENUM "No", "Yes";
BA_DEF_ BO_  "VAGTP20_StatConnection" ENUM "No", "Yes";
BA_DEF_ SG_  "GenSigActiveRepetitions" INT -2147483648 2147483647;
BA_DEF_ SG_  "GenSigInactiveValue" INT -2147483648 2147483647;
BA_DEF_ SG_  "GenSigSendType" ENUM "Cyclic", "OnWrite", "OnWriteWithRepetition", "OnChange", "OnChangeWithRepetition", "IfActive", "IfActiveWithRepetition", "NoSigSendType", "OnChangeAndIfActive", "OnChangeAndIfActiveWithRepetition";
BA_DEF_ SG_  "GenSigStartValue" INT -2147483648 2147483647;
BA_DEF_ SG_  "NWM-WakeupAllowed" ENUM "No", "Yes";
BA_DEF_ SG_  "GenSigFuncType" ENUM "NoFunction", "MsgCounter", "CRC-8", "XOR", "XOR-2", "DatedBit", "SW-Kl15", "CHK", "Constant", "Protocol", "CRC-8-SAE_J1850", "CRC-32", "DataLength", "DataID", "MsgCounter16", "SOK-Signatur", "Cluster";
BA_DEF_ SG_  "GenSigSwitchedByIgnition" ENUM "No", "Yes";
BA_DEF_ SG_  "Fehlerwert" HEX 0 2147483647;
BA_DEF_ SG_  "GenSigMissingSourceValue" HEX 0 2147483647;
BA_DEF_DEF_REL_  "GenSigTimeoutTime" 0;
BA_DEF_DEF_  "DiagRequest" "No";
BA_DEF_DEF_  "DiagResponse" "No";
BA_DEF_DEF_  "DiagState" "No";
BA_DEF_DEF_  "GenMsgChkConstant" 0;
BA_DEF_DEF_  "GenMsgCycleTime" 0;
BA_DEF_DEF_  "GenMsgCycleTimeFast" 0;
BA_DEF_DEF_  "GenMsgDelayTime" 0;
BA_DEF_DEF_  "GenMsgILSupport" "No";
BA_DEF_DEF_  "GenMsgNrOfRepetition" 0;
BA_DEF_DEF_  "GenMsgPDUConstants" "";
BA_DEF_DEF_  "GenMsgSendType" "NoMsgSendType";
BA_DEF_DEF_  "GenMsgStartDelayTime" 0;
BA_DEF_DEF_  "NmMessage" "No";
BA_DEF_DEF_  "NmhMessage" "No";
BA_DEF_DEF_  "MsgType" "Application";
BA_DEF_DEF_  "VAGTP20_API" 0;
BA_DEF_DEF_  "VAGTP20_DynConnection" "No";
BA_DEF_DEF_  "VAGTP20_DynSetup" "No";
BA_DEF_DEF_  "VAGTP20_StatConnection" "No";
BA_DEF_DEF_  "GenSigActiveRepetitions" 0;
BA_DEF_DEF_  "GenSigInactiveValue" 0;
BA_DEF_DEF_  "GenSigSendType" "NoSigSendType";
BA_DEF_DEF_  "GenSigStartValue" 0;
BA_DEF_DEF_  "NWM-WakeupAllowed" "No";
BA_DEF_DEF_  "GenSigFuncType" "NoFunction";
BA_DEF_DEF_  "GenSigSwitchedByIgnition" "Yes";
BA_DEF_DEF_  "Fehlerwert" 0;
BA_DEF_DEF_  "GenSigMissingSourceValue" 0;
BA_ "GenMsgCycleTime" BO_ 980 200;
BA_ "GenMsgCycleTimeFast" BO_ 980 80;
BA_ "GenMsgDelayTime" BO_ 980 40;
BA_ "GenMsgILSupport" BO_ 980 1;
BA_ "GenMsgNrOfRepetition" BO_ 980 5;
BA_ "GenMsgPDUConstants" BO_ 980 "0xc3,0x79,0xbf,0xdb,0xe9,0x11,0x46,0x86,0x69,0xb6,0x9b,0x29,0x15,0x9c,0x45,0x0d";
BA_ "GenMsgSendType" BO_ 980 0;
BA_ "GenMsgCycleTime" BO_ 904 100;
BA_ "GenMsgILSupport" BO_ 904 1;
BA_ "GenMsgPDUConstants" BO_ 904 "0x1d,0x3c,0xee,0x54,0xe4,0xcf,0xad,0xa3,0x6b,0x81,0xb6,0x93,0xc8,0x0b,0x44,0xc7";
BA_ "GenMsgSendType" BO_ 904 0;
BA_ "GenMsgCycleTime" BO_ 1313 200;
BA_ "GenMsgILSupport" BO_ 1313 1;
BA_ "GenMsgSendType" BO_ 1313 0;
BA_ "GenMsgCycleTime" BO_ 505 20;
BA_ "GenMsgILSupport" BO_ 505 1;
BA_ "GenMsgPDUConstants" BO_ 505 "0x14,0xf8,0xf6,0x94,0x2a,0x12,0x39,0x3d,0x98,0x3f,0xfb,0x9d,0x36,0xca,0x1d,0xe0";
BA_ "GenMsgSendType" BO_ 505 0;
BA_ "GenMsgCycleTime" BO_ 666 400;
BA_ "GenMsgDelayTime" BO_ 666 40;
BA_ "GenMsgILSupport" BO_ 666 1;
BA_ "GenMsgSendType" BO_ 666 0;
BA_ "GenMsgChkConstant" BO_ 1172 144;
BA_ "GenMsgCycleTime" BO_ 1172 200;
BA_ "GenMsgDelayTime" BO_ 1172 20;
BA_ "GenMsgILSupport" BO_ 1172 1;
BA_ "GenMsgPDUConstants" BO_ 1172 "0x90,0x90,0x90,0x90,0x90,0x90,0x90,0x90,0x90,0x90,0x90,0x90,0x90,0x90,0x90,0x90";
BA_ "GenMsgSendType" BO_ 1172 0;
BA_ "GenMsgChkConstant" BO_ 783 12;
BA_ "GenMsgCycleTime" BO_ 783 200;
BA_ "GenMsgDelayTime" BO_ 783 50;
BA_ "GenMsgILSupport" BO_ 783 1;
BA_ "GenMsgPDUConstants" BO_ 783 "0x0c,0x0c,0x0c,0x0c,0x0c,0x0c,0x0c,0x0c,0x0c,0x0c,0x0c,0x0c,0x0c,0x0c,0x0c,0x0c";
BA_ "GenMsgSendType" BO_ 783 0;
BA_ "GenMsgCycleTime" BO_ 1413 1000;
BA_ "GenMsgDelayTime" BO_ 1413 10;
BA_ "GenMsgILSupport" BO_ 1413 1;
BA_ "GenMsgSendType" BO_ 1413 0;
BA_ "GenMsgStartDelayTime" BO_ 1413 85;
BA_ "GenMsgCycleTime" BO_ 619 400;
BA_ "GenMsgDelayTime" BO_ 619 40;
BA_ "GenMsgILSupport" BO_ 619 1;
BA_ "GenMsgPDUConstants" BO_ 619 "0xce,0xcc,0xbd,0x69,0xa1,0x3c,0x18,0x76,0x0f,0x04,0xf2,0x3a,0x93,0x24,0x19,0x51";
BA_ "GenMsgSendType" BO_ 619 0;
BA_ "GenMsgCycleTime" BO_ 1604 500;
BA_ "GenMsgILSupport" BO_ 1604 1;
BA_ "GenMsgSendType" BO_ 1604 0;
BA_ "GenMsgCycleTime" BO_ 1001 100;
BA_ "GenMsgILSupport" BO_ 1001 1;
BA_ "GenMsgSendType" BO_ 1001 0;
BA_ "GenMsgCycleTime" BO_ 1375 500;
BA_ "GenMsgDelayTime" BO_ 1375 20;
BA_ "GenMsgILSupport" BO_ 1375 1;
BA_ "GenMsgSendType" BO_ 1375 0;
BA_ "GenMsgCycleTime" BO_ 1657 500;
BA_ "GenMsgILSupport" BO_ 1657 1;
BA_ "GenMsgSendType" BO_ 1657 0;
BA_ "GenMsgCycleTime" BO_ 2527679762 200;
BA_ "GenMsgILSupport" BO_ 2527679762 1;
BA_ "GenMsgSendType" BO_ 2527679762 0;
BA_ "GenMsgCycleTime" BO_ 977 500;
BA_ "GenMsgDelayTime" BO_ 977 100;
BA_ "GenMsgILSupport" BO_ 977 1;
BA_ "GenMsgSendType" BO_ 977 0;
BA_ "GenMsgCycleTime" BO_ 976 100;
BA_ "GenMsgDelayTime" BO_ 976 20;
BA_ "GenMsgILSupport" BO_ 976 1;
BA_ "GenMsgSendType" BO_ 976 0;
BA_ "GenMsgCycleTime" BO_ 997 100;
BA_ "GenMsgDelayTime" BO_ 997 20;
BA_ "GenMsgILSupport" BO_ 997 1;
BA_ "GenMsgPDUConstants" BO_ 997 "0xc4,0x6a,0x69,0x30,0xcf,0x61,0x58,0x51,0x1b,0x86,0x99,0xd3,0xf6,0x1d,0x9a,0x37";
BA_ "GenMsgSendType" BO_ 997 0;
BA_ "GenMsgCycleTime" BO_ 975 500;
BA_ "GenMsgDelayTime" BO_ 975 100;
BA_ "GenMsgILSupport" BO_ 975 1;
BA_ "GenMsgSendType" BO_ 975 0;
BA_ "GenMsgCycleTime" BO_ 703 100;
BA_ "GenMsgDelayTime" BO_ 703 20;
BA_ "GenMsgILSupport" BO_ 703 1;
BA_ "GenMsgPDUConstants" BO_ 703 "0x6c,0x8f,0xc9,0xf3,0xb1,0x77,0xed,0x53,0xcd,0x44,0x40,0xf1,0x15,0x2d,0x37,0xe6";
BA_ "GenMsgSendType" BO_ 703 0;
BA_ "GenSigSendType" SG_ 980 BH_Blinker_Fehler 3;
BA_ "GenSigSwitchedByIgnition" SG_ 980 BH_Blinker_Fehler 0;
BA_ "Fehlerwert" SG_ 980 BH_Blinker_Fehler 1;
BA_ "GenSigActiveRepetitions" SG_ 980 BH_Blinker_li 5;
BA_ "GenSigSendType" SG_ 980 BH_Blinker_li 4;
BA_ "GenSigSwitchedByIgnition" SG_ 980 BH_Blinker_li 0;
BA_ "GenSigActiveRepetitions" SG_ 980 BH_Blinker_re 5;
BA_ "GenSigSendType" SG_ 980 BH_Blinker_re 4;
BA_ "GenSigSwitchedByIgnition" SG_ 980 BH_Blinker_re 0;
BA_ "GenSigSendType" SG_ 980 BH_Fernlicht 3;
BA_ "GenSigSwitchedByIgnition" SG_ 980 BH_Fernlicht 0;
BA_ "GenSigActiveRepetitions" SG_ 980 BH_Lichthupe 5;
BA_ "GenSigSendType" SG_ 980 BH_Lichthupe 4;
BA_ "GenSigSwitchedByIgnition" SG_ 980 BH_Lichthupe 0;
BA_ "GenSigSendType" SG_ 980 FAS_Taster 3;
BA_ "GenSigSwitchedByIgnition" SG_ 980 FAS_Taster 0;
BA_ "GenSigSendType" SG_ 980 FAS_Taster_Fehler 3;
BA_ "GenSigSwitchedByIgnition" SG_ 980 FAS_Taster_Fehler 0;
BA_ "Fehlerwert" SG_ 980 FAS_Taster_Fehler 1;
BA_ "GenSigSendType" SG_ 980 LRH_aktiv 3;
BA_ "GenSigSwitchedByIgnition" SG_ 980 LRH_aktiv 0;
BA_ "GenSigSendType" SG_ 980 LRH_On_Off 3;
BA_ "GenSigSwitchedByIgnition" SG_ 980 LRH_On_Off 0;
BA_ "Fehlerwert" SG_ 980 LRH_On_Off 3;
BA_ "GenSigSendType" SG_ 980 SMLS_01_BZ 0;
BA_ "GenSigFuncType" SG_ 980 SMLS_01_BZ 1;
BA_ "GenSigSwitchedByIgnition" SG_ 980 SMLS_01_BZ 0;
BA_ "GenSigSendType" SG_ 980 SMLS_01_CRC 0;
BA_ "GenSigFuncType" SG_ 980 SMLS_01_CRC 2;
BA_ "GenSigSwitchedByIgnition" SG_ 980 SMLS_01_CRC 0;
BA_ "GenSigActiveRepetitions" SG_ 980 SMLS_Hupe 5;
BA_ "GenSigSendType" SG_ 980 SMLS_Hupe 4;
BA_ "GenSigSwitchedByIgnition" SG_ 980 SMLS_Hupe 0;
BA_ "GenSigSendType" SG_ 980 SMLS_P_verriegelt_plausibel 3;
BA_ "GenSigSwitchedByIgnition" SG_ 980 SMLS_P_verriegelt_plausibel 0;
BA_ "GenSigActiveRepetitions" SG_ 980 SMLS_PTT 5;
BA_ "GenSigSendType" SG_ 980 SMLS_PTT 4;
BA_ "GenSigSendType" SG_ 980 WH_Frontwaschen 3;
BA_ "GenSigSwitchedByIgnition" SG_ 980 WH_Frontwaschen 0;
BA_ "GenSigSendType" SG_ 980 WH_Heckintervall 3;
BA_ "GenSigSwitchedByIgnition" SG_ 980 WH_Heckintervall 0;
BA_ "GenSigSendType" SG_ 980 WH_Heckwaschen 3;
BA_ "GenSigSwitchedByIgnition" SG_ 980 WH_Heckwaschen 0;
BA_ "GenSigSendType" SG_ 980 WH_Intervall 3;
BA_ "GenSigSwitchedByIgnition" SG_ 980 WH_Intervall 0;
BA_ "GenSigSendType" SG_ 980 WH_Intervallstufen 3;
BA_ "GenSigSwitchedByIgnition" SG_ 980 WH_Intervallstufen 0;
BA_ "Fehlerwert" SG_ 980 WH_Intervallstufen 15;
BA_ "GenSigMissingSourceValue" SG_ 980 WH_Intervallstufen 15;
BA_ "GenSigActiveRepetitions" SG_ 980 WH_SRA 5;
BA_ "GenSigSendType" SG_ 980 WH_SRA 4;
BA_ "GenSigSwitchedByIgnition" SG_ 980 WH_SRA 0;
BA_ "GenSigActiveRepetitions" SG_ 980 WH_Tipwischen 5;
BA_ "GenSigSendType" SG_ 980 WH_Tipwischen 4;
BA_ "GenSigSwitchedByIgnition" SG_ 980 WH_Tipwischen 0;
BA_ "GenSigActiveRepetitions" SG_ 980 WH_Tipwischen_lang 5;
BA_ "GenSigSendType" SG_ 980 WH_Tipwischen_lang 4;
BA_ "GenSigSwitchedByIgnition" SG_ 980 WH_Tipwischen_lang 0;
BA_ "GenSigSendType" SG_ 980 WH_Wischer_Fehler 3;
BA_ "GenSigSwitchedByIgnition" SG_ 980 WH_Wischer_Fehler 0;
BA_ "Fehlerwert" SG_ 980 WH_Wischer_Fehler 1;
BA_ "GenSigSendType" SG_ 980 WH_WischerStufe1 3;
BA_ "GenSigSwitchedByIgnition" SG_ 980 WH_WischerStufe1 0;
BA_ "GenSigSendType" SG_ 980 WH_WischerStufe2 3;
BA_ "GenSigSwitchedByIgnition" SG_ 980 WH_WischerStufe2 0;
BA_ "GenSigSendType" SG_ 904 BugSp_AOCCT_Fehlerstatus 0;
BA_ "GenSigSwitchedByIgnition" SG_ 904 BugSp_AOCCT_Fehlerstatus 0;
BA_ "GenSigSendType" SG_ 904 BugSp_AOCCT_Teststatus 0;
BA_ "GenSigSwitchedByIgnition" SG_ 904 BugSp_AOCCT_Teststatus 0;
BA_ "GenSigSendType" SG_ 904 BugSp_AOCCT_timer1_count 0;
BA_ "GenSigSwitchedByIgnition" SG_ 904 BugSp_AOCCT_timer1_count 0;
BA_ "GenSigSendType" SG_ 904 BugSp_AOCCT_timer1_verbaut 0;
BA_ "GenSigSwitchedByIgnition" SG_ 904 BugSp_AOCCT_timer1_verbaut 0;
BA_ "GenSigSendType" SG_ 904 BugSp_AOCCT_timer2_count 0;
BA_ "GenSigSwitchedByIgnition" SG_ 904 BugSp_AOCCT_timer2_count 0;
BA_ "GenSigSendType" SG_ 904 BugSp_AOCCT_timer2_verbaut 0;
BA_ "GenSigSwitchedByIgnition" SG_ 904 BugSp_AOCCT_timer2_verbaut 0;
BA_ "GenSigSendType" SG_ 904 HeckSp_AOCCT_Fehlerstatus 0;
BA_ "GenSigSwitchedByIgnition" SG_ 904 HeckSp_AOCCT_Fehlerstatus 0;
BA_ "GenSigSendType" SG_ 904 HeckSp_AOCCT_Teststatus 0;
BA_ "GenSigSwitchedByIgnition" SG_ 904 HeckSp_AOCCT_Teststatus 0;
BA_ "GenSigSendType" SG_ 904 HeckSp_AOCCT_timer1_count 0;
BA_ "GenSigSwitchedByIgnition" SG_ 904 HeckSp_AOCCT_timer1_count 0;
BA_ "GenSigSendType" SG_ 904 HeckSp_AOCCT_timer1_verbaut 0;
BA_ "GenSigSwitchedByIgnition" SG_ 904 HeckSp_AOCCT_timer1_verbaut 0;
BA_ "GenSigSendType" SG_ 904 HeckSp_AOCCT_timer2_count 0;
BA_ "GenSigSwitchedByIgnition" SG_ 904 HeckSp_AOCCT_timer2_count 0;
BA_ "GenSigSendType" SG_ 904 HeckSp_AOCCT_timer2_verbaut 0;
BA_ "GenSigSwitchedByIgnition" SG_ 904 HeckSp_AOCCT_timer2_verbaut 0;
BA_ "GenSigSendType" SG_ 904 LFE_Status 0;
BA_ "GenSigSwitchedByIgnition" SG_ 904 LFE_Status 0;
BA_ "GenSigSendType" SG_ 904 SpoilerSG_01_BZ 0;
BA_ "GenSigFuncType" SG_ 904 SpoilerSG_01_BZ 1;
BA_ "GenSigSwitchedByIgnition" SG_ 904 SpoilerSG_01_BZ 0;
BA_ "GenSigSendType" SG_ 904 SpoilerSG_01_CRC 0;
BA_ "GenSigFuncType" SG_ 904 SpoilerSG_01_CRC 2;
BA_ "GenSigSwitchedByIgnition" SG_ 904 SpoilerSG_01_CRC 0;
BA_ "GenSigSendType" SG_ 904 SpoilerSG_AeroZustand 0;
BA_ "GenSigStartValue" SG_ 904 SpoilerSG_AeroZustand 14;
BA_ "GenSigSwitchedByIgnition" SG_ 904 SpoilerSG_AeroZustand 0;
BA_ "Fehlerwert" SG_ 904 SpoilerSG_AeroZustand 15;
BA_ "GenSigSendType" SG_ 904 SpoilerSG_Anf_ESP_Zuschaltung 0;
BA_ "GenSigSwitchedByIgnition" SG_ 904 SpoilerSG_Anf_ESP_Zuschaltung 0;
BA_ "GenSigSendType" SG_ 904 SpoilerSG_Fehler 0;
BA_ "GenSigSwitchedByIgnition" SG_ 904 SpoilerSG_Fehler 0;
BA_ "GenSigSendType" SG_ 904 SpoilerSG_HSpoiler_IstPos 0;
BA_ "GenSigStartValue" SG_ 904 SpoilerSG_HSpoiler_IstPos 254;
BA_ "GenSigSwitchedByIgnition" SG_ 904 SpoilerSG_HSpoiler_IstPos 0;
BA_ "Fehlerwert" SG_ 904 SpoilerSG_HSpoiler_IstPos 255;
BA_ "GenSigSendType" SG_ 904 SpoilerSG_SKE_PosSens_Status 0;
BA_ "GenSigSwitchedByIgnition" SG_ 904 SpoilerSG_SKE_PosSens_Status 0;
BA_ "Fehlerwert" SG_ 904 SpoilerSG_SKE_PosSens_Status 3;
BA_ "GenSigSendType" SG_ 904 SpoilerSG_Status 0;
BA_ "GenSigSwitchedByIgnition" SG_ 904 SpoilerSG_Status 0;
BA_ "GenSigSendType" SG_ 904 TE_TrunkEntrapment_Fehler 0;
BA_ "GenSigStartValue" SG_ 904 TE_TrunkEntrapment_Fehler 1;
BA_ "GenSigSwitchedByIgnition" SG_ 904 TE_TrunkEntrapment_Fehler 0;
BA_ "GenSigSendType" SG_ 1313 STH_EKP_Anst 0;
BA_ "GenSigSwitchedByIgnition" SG_ 1313 STH_EKP_Anst 0;
BA_ "GenSigSendType" SG_ 1313 STH_Fehler_ElWaPu 0;
BA_ "GenSigSwitchedByIgnition" SG_ 1313 STH_Fehler_ElWaPu 0;
BA_ "Fehlerwert" SG_ 1313 STH_Fehler_ElWaPu 1;
BA_ "GenSigSendType" SG_ 1313 STH_Fehlerstatus 0;
BA_ "GenSigSwitchedByIgnition" SG_ 1313 STH_Fehlerstatus 0;
BA_ "GenSigSendType" SG_ 1313 STH_Funk_aus 0;
BA_ "GenSigSwitchedByIgnition" SG_ 1313 STH_Funk_aus 0;
BA_ "GenSigSendType" SG_ 1313 STH_Funk_ein 0;
BA_ "GenSigSwitchedByIgnition" SG_ 1313 STH_Funk_ein 0;
BA_ "GenSigSendType" SG_ 1313 STH_Geblaese 0;
BA_ "GenSigSwitchedByIgnition" SG_ 1313 STH_Geblaese 0;
BA_ "GenSigSendType" SG_ 1313 STH_Heizleistung 0;
BA_ "GenSigSwitchedByIgnition" SG_ 1313 STH_Heizleistung 0;
BA_ "GenSigSendType" SG_ 1313 STH_KL_HUP 0;
BA_ "GenSigSwitchedByIgnition" SG_ 1313 STH_KL_HUP 0;
BA_ "GenSigSendType" SG_ 1313 STH_KVS 0;
BA_ "GenSigSwitchedByIgnition" SG_ 1313 STH_KVS 0;
BA_ "GenSigSendType" SG_ 1313 STH_KVS_Ueberlauf 0;
BA_ "GenSigSwitchedByIgnition" SG_ 1313 STH_KVS_Ueberlauf 0;
BA_ "GenSigSendType" SG_ 1313 STH_LED 0;
BA_ "GenSigSwitchedByIgnition" SG_ 1313 STH_LED 0;
BA_ "GenSigSendType" SG_ 1313 STH_Motorvorwaermung 0;
BA_ "GenSigSwitchedByIgnition" SG_ 1313 STH_Motorvorwaermung 0;
BA_ "GenSigSendType" SG_ 1313 STH_Pumpe_ein 0;
BA_ "GenSigSwitchedByIgnition" SG_ 1313 STH_Pumpe_ein 0;
BA_ "GenSigSendType" SG_ 1313 STH_Pumpen_Anf_extern 0;
BA_ "GenSigSwitchedByIgnition" SG_ 1313 STH_Pumpen_Anf_extern 0;
BA_ "GenSigSendType" SG_ 1313 STH_Servicemode 0;
BA_ "GenSigSwitchedByIgnition" SG_ 1313 STH_Servicemode 0;
BA_ "GenSigSendType" SG_ 1313 STH_SH_ZH 0;
BA_ "GenSigSwitchedByIgnition" SG_ 1313 STH_SH_ZH 0;
BA_ "GenSigSendType" SG_ 1313 STH_Start_folgt 0;
BA_ "GenSigSwitchedByIgnition" SG_ 1313 STH_Start_folgt 0;
BA_ "GenSigSendType" SG_ 1313 STH_Texte 0;
BA_ "GenSigSwitchedByIgnition" SG_ 1313 STH_Texte 0;
BA_ "GenSigSendType" SG_ 1313 STH_Ventil_Status 0;
BA_ "GenSigSwitchedByIgnition" SG_ 1313 STH_Ventil_Status 0;
BA_ "GenSigSendType" SG_ 1313 STH_Ventiloeffnungszeit 0;
BA_ "GenSigSwitchedByIgnition" SG_ 1313 STH_Ventiloeffnungszeit 0;
BA_ "GenSigSendType" SG_ 1313 STH_Waermeeintrag 0;
BA_ "GenSigSwitchedByIgnition" SG_ 1313 STH_Waermeeintrag 0;
BA_ "GenSigSendType" SG_ 1313 STH_war_aktiv 0;
BA_ "GenSigSwitchedByIgnition" SG_ 1313 STH_war_aktiv 0;
BA_ "GenSigSendType" SG_ 1313 STH_Wassertemp 0;
BA_ "GenSigStartValue" SG_ 1313 STH_Wassertemp 254;
BA_ "GenSigSwitchedByIgnition" SG_ 1313 STH_Wassertemp 0;
BA_ "Fehlerwert" SG_ 1313 STH_Wassertemp 255;
BA_ "GenSigSendType" SG_ 1313 STH_Zusatzheizung 0;
BA_ "GenSigSwitchedByIgnition" SG_ 1313 STH_Zusatzheizung 0;
BA_ "GenSigSendType" SG_ 505 ACA_HF_Grund_AV_AB 0;
BA_ "GenSigSendType" SG_ 505 ACA_HF_Status 0;
BA_ "GenSigStartValue" SG_ 505 ACA_HF_Status 1;
BA_ "GenSigSendType" SG_ 505 ACA_QF_Fahreruebernahme 0;
BA_ "GenSigSendType" SG_ 505 ACA_QF_Status_Anzeige 0;
BA_ "GenSigSendType" SG_ 505 ACF_Spurwechsel_moeglich 0;
BA_ "GenSigSendType" SG_ 505 ACF_Spurwechsel_wahrscheinlich 0;
BA_ "GenSigSendType" SG_ 505 ACF_SwuFahrerUnaufmerksam 0;
BA_ "GenSigSwitchedByIgnition" SG_ 505 ACF_SwuFahrerUnaufmerksam 0;
BA_ "GenSigSendType" SG_ 505 FZE_Spurwechsel_erkannt_li 0;
BA_ "GenSigSendType" SG_ 505 FZE_Spurwechsel_erkannt_re 0;
BA_ "GenSigSendType" SG_ 505 FZE_STP_Abschaltbedingung 0;
BA_ "GenSigStartValue" SG_ 505 FZE_STP_Abschaltbedingung 1;
BA_ "GenSigSendType" SG_ 505 FZE_STP_Aktivierverhinderung 0;
BA_ "GenSigSwitchedByIgnition" SG_ 505 FZE_STP_Aktivierverhinderung 0;
BA_ "GenSigSendType" SG_ 505 FZE_STP_Status 0;
BA_ "GenSigSendType" SG_ 505 STP_03_BZ 0;
BA_ "GenSigFuncType" SG_ 505 STP_03_BZ 1;
BA_ "GenSigSendType" SG_ 505 STP_03_CRC 0;
BA_ "GenSigFuncType" SG_ 505 STP_03_CRC 2;
BA_ "GenSigSendType" SG_ 505 STP_Funktion_freigegeben 0;
BA_ "GenSigSendType" SG_ 505 STP_Notlaufaktivierung 0;
BA_ "GenSigSendType" SG_ 505 STP_Slave_Status 0;
BA_ "GenSigSendType" SG_ 666 STP_Abstand_Zielobjekt 3;
BA_ "GenSigSendType" SG_ 666 STP_Egokolonne_ZA 3;
BA_ "GenSigSendType" SG_ 666 STP_FAS_Fkt_Status 3;
BA_ "Fehlerwert" SG_ 666 STP_FAS_Fkt_Status 3;
BA_ "GenSigSendType" SG_ 666 STP_FBM_links_ZA 3;
BA_ "GenSigSendType" SG_ 666 STP_FBM_rechts_ZA 3;
BA_ "GenSigSendType" SG_ 666 STP_Geschw_Egofahrzeug_ZA 3;
BA_ "GenSigSendType" SG_ 666 STP_Nebenspur_Geschw_links_ZA 3;
BA_ "GenSigStartValue" SG_ 666 STP_Nebenspur_Geschw_links_ZA 255;
BA_ "GenSigSendType" SG_ 666 STP_Nebenspur_Geschw_rechts_ZA 3;
BA_ "GenSigStartValue" SG_ 666 STP_Nebenspur_Geschw_rechts_ZA 255;
BA_ "GenSigSendType" SG_ 666 STP_Nebenspur_links_ZA 3;
BA_ "GenSigSendType" SG_ 666 STP_Nebenspur_rechts_ZA 3;
BA_ "GenSigSendType" SG_ 666 STP_Primaeranz_02 3;
BA_ "GenSigSendType" SG_ 666 STP_Status_Anzeige 3;
BA_ "GenSigSendType" SG_ 666 STP_Texte 3;
BA_ "GenSigSendType" SG_ 666 STP_Texte_AV 3;
BA_ "GenSigSendType" SG_ 666 STP_Texte_ESK 3;
BA_ "GenSigSendType" SG_ 666 STP_Texte_ZA 3;
BA_ "GenSigSendType" SG_ 1172 GW_STS2_Privatsphaere 0;
BA_ "GenSigSwitchedByIgnition" SG_ 1172 GW_STS2_Privatsphaere 0;
BA_ "GenSigSendType" SG_ 1172 STS_01_BZ 0;
BA_ "GenSigFuncType" SG_ 1172 STS_01_BZ 1;
BA_ "GenSigSwitchedByIgnition" SG_ 1172 STS_01_BZ 0;
BA_ "GenSigSendType" SG_ 1172 STS_01_CRC 0;
BA_ "GenSigFuncType" SG_ 1172 STS_01_CRC 2;
BA_ "GenSigSwitchedByIgnition" SG_ 1172 STS_01_CRC 0;
BA_ "GenSigSendType" SG_ 1172 STS_Alarm_Blinker 3;
BA_ "GenSigSwitchedByIgnition" SG_ 1172 STS_Alarm_Blinker 0;
BA_ "GenSigSendType" SG_ 1172 STS_Alarm_still 0;
BA_ "GenSigSwitchedByIgnition" SG_ 1172 STS_Alarm_still 0;
BA_ "GenSigSendType" SG_ 1172 STS_Anlassersperre 0;
BA_ "GenSigSwitchedByIgnition" SG_ 1172 STS_Anlassersperre 0;
BA_ "GenSigSendType" SG_ 1172 STS_Car_not_under_theft 0;
BA_ "GenSigStartValue" SG_ 1172 STS_Car_not_under_theft 1;
BA_ "GenSigSwitchedByIgnition" SG_ 1172 STS_Car_not_under_theft 0;
BA_ "GenSigSendType" SG_ 1172 STS_Car_under_theft 0;
BA_ "GenSigSwitchedByIgnition" SG_ 1172 STS_Car_under_theft 0;
BA_ "GenSigSendType" SG_ 1172 STS_Door_Lock 3;
BA_ "GenSigSwitchedByIgnition" SG_ 1172 STS_Door_Lock 0;
BA_ "GenSigSendType" SG_ 1172 STS_Fahrlicht 3;
BA_ "GenSigSwitchedByIgnition" SG_ 1172 STS_Fahrlicht 0;
BA_ "GenSigSendType" SG_ 1172 STS_Laderelais 3;
BA_ "GenSigSwitchedByIgnition" SG_ 1172 STS_Laderelais 0;
BA_ "GenSigSendType" SG_ 1172 STS_Leerlaufschaltung 0;
BA_ "GenSigSwitchedByIgnition" SG_ 1172 STS_Leerlaufschaltung 0;
BA_ "GenSigSendType" SG_ 1172 STS_LIN_aktiv 0;
BA_ "GenSigSwitchedByIgnition" SG_ 1172 STS_LIN_aktiv 0;
BA_ "GenSigSendType" SG_ 1172 STS_Notstart 3;
BA_ "GenSigSwitchedByIgnition" SG_ 1172 STS_Notstart 0;
BA_ "GenSigSendType" SG_ 1172 STS_Signalhorn 3;
BA_ "GenSigSwitchedByIgnition" SG_ 1172 STS_Signalhorn 0;
BA_ "GenSigSendType" SG_ 1172 STS_Spiegel_Anklappen 3;
BA_ "GenSigSwitchedByIgnition" SG_ 1172 STS_Spiegel_Anklappen 0;
BA_ "GenSigSendType" SG_ 1172 STS_Standlicht 3;
BA_ "GenSigSwitchedByIgnition" SG_ 1172 STS_Standlicht 0;
BA_ "GenSigSendType" SG_ 1172 STS_Summer 3;
BA_ "GenSigSwitchedByIgnition" SG_ 1172 STS_Summer 0;
BA_ "GenSigSendType" SG_ 1172 STS_Texte 0;
BA_ "GenSigStartValue" SG_ 1172 STS_Texte 14;
BA_ "GenSigSwitchedByIgnition" SG_ 1172 STS_Texte 0;
BA_ "Fehlerwert" SG_ 1172 STS_Texte 15;
BA_ "GenSigSendType" SG_ 1172 STS_Typencodierung 0;
BA_ "GenSigSwitchedByIgnition" SG_ 1172 STS_Typencodierung 0;
BA_ "GenSigSendType" SG_ 783 ASW_Kombitexte 3;
BA_ "GenSigSwitchedByIgnition" SG_ 783 ASW_Kombitexte 0;
BA_ "GenSigSendType" SG_ 783 ASW_Modus 0;
BA_ "GenSigStartValue" SG_ 783 ASW_Modus 4;
BA_ "GenSigSendType" SG_ 783 ASW_Status 3;
BA_ "GenSigSwitchedByIgnition" SG_ 783 ASW_Status 0;
BA_ "Fehlerwert" SG_ 783 ASW_Status 2;
BA_ "GenSigSendType" SG_ 783 ASW_Warnung_BFS 3;
BA_ "GenSigSwitchedByIgnition" SG_ 783 ASW_Warnung_BFS 0;
BA_ "GenSigSendType" SG_ 783 ASW_Warnung_FS 3;
BA_ "GenSigSwitchedByIgnition" SG_ 783 ASW_Warnung_FS 0;
BA_ "GenSigSendType" SG_ 783 Heckradar_Kombitexte 3;
BA_ "GenSigSwitchedByIgnition" SG_ 783 Heckradar_Kombitexte 0;
BA_ "GenSigSendType" SG_ 783 HRE_Anzeigetexte 0;
BA_ "GenSigSwitchedByIgnition" SG_ 783 HRE_Anzeigetexte 0;
BA_ "GenSigSendType" SG_ 783 RCTA_Kombitexte 3;
BA_ "GenSigSwitchedByIgnition" SG_ 783 RCTA_Kombitexte 0;
BA_ "GenSigSendType" SG_ 783 SWA_01_BZ 0;
BA_ "GenSigFuncType" SG_ 783 SWA_01_BZ 1;
BA_ "GenSigSwitchedByIgnition" SG_ 783 SWA_01_BZ 0;
BA_ "GenSigSendType" SG_ 783 SWA_01_CRC 0;
BA_ "GenSigFuncType" SG_ 783 SWA_01_CRC 2;
BA_ "GenSigSwitchedByIgnition" SG_ 783 SWA_01_CRC 0;
BA_ "GenSigSendType" SG_ 783 SWA_Anzeigen 3;
BA_ "GenSigSwitchedByIgnition" SG_ 783 SWA_Anzeigen 0;
BA_ "GenSigSendType" SG_ 783 SWA_Blindheit_erkannt 0;
BA_ "GenSigSendType" SG_ 783 SWA_FT_RueckLED 3;
BA_ "GenSigSwitchedByIgnition" SG_ 783 SWA_FT_RueckLED 0;
BA_ "GenSigSendType" SG_ 783 SWA_Infostufe_SWA_li 0;
BA_ "GenSigSendType" SG_ 783 SWA_Infostufe_SWA_re 0;
BA_ "GenSigSendType" SG_ 783 SWA_Kolonne_li 0;
BA_ "GenSigSendType" SG_ 783 SWA_Kolonne_mi 0;
BA_ "GenSigSendType" SG_ 783 SWA_Kolonne_re 0;
BA_ "GenSigSendType" SG_ 783 SWA_Modus 0;
BA_ "GenSigSendType" SG_ 783 SWA_rel_Fehler 0;
BA_ "Fehlerwert" SG_ 783 SWA_rel_Fehler 1;
BA_ "GenSigSendType" SG_ 783 SWA_rel_Nichtverf 0;
BA_ "GenSigSendType" SG_ 783 SWA_Sta_aktiv 0;
BA_ "GenSigSendType" SG_ 783 SWA_Sta_passiv 0;
BA_ "GenSigSendType" SG_ 783 SWA_Standziele_li 0;
BA_ "GenSigSendType" SG_ 783 SWA_Standziele_re 0;
BA_ "GenSigSendType" SG_ 783 SWA_Status_02 0;
BA_ "Fehlerwert" SG_ 783 SWA_Status_02 3;
BA_ "GenSigSendType" SG_ 783 SWA_Warnung_SWA_li 0;
BA_ "GenSigSendType" SG_ 783 SWA_Warnung_SWA_re 0;
BA_ "GenSigSendType" SG_ 1413 GW_KD_Fehler 3;
BA_ "GenSigSendType" SG_ 1413 SI_BUS_01 3;
BA_ "GenSigStartValue" SG_ 1413 SI_BUS_01 1;
BA_ "GenSigSwitchedByIgnition" SG_ 1413 SI_BUS_01 0;
BA_ "GenSigSendType" SG_ 1413 SI_BUS_02 3;
BA_ "GenSigStartValue" SG_ 1413 SI_BUS_02 1;
BA_ "GenSigSwitchedByIgnition" SG_ 1413 SI_BUS_02 0;
BA_ "GenSigSendType" SG_ 1413 SI_BUS_03 3;
BA_ "GenSigStartValue" SG_ 1413 SI_BUS_03 1;
BA_ "GenSigSwitchedByIgnition" SG_ 1413 SI_BUS_03 0;
BA_ "GenSigSendType" SG_ 1413 SI_BUS_04 3;
BA_ "GenSigStartValue" SG_ 1413 SI_BUS_04 1;
BA_ "GenSigSwitchedByIgnition" SG_ 1413 SI_BUS_04 0;
BA_ "GenSigSendType" SG_ 1413 SI_BUS_05 3;
BA_ "GenSigStartValue" SG_ 1413 SI_BUS_05 1;
BA_ "GenSigSwitchedByIgnition" SG_ 1413 SI_BUS_05 0;
BA_ "GenSigSendType" SG_ 1413 SI_BUS_06 3;
BA_ "GenSigStartValue" SG_ 1413 SI_BUS_06 1;
BA_ "GenSigSwitchedByIgnition" SG_ 1413 SI_BUS_06 0;
BA_ "GenSigSendType" SG_ 1413 SI_BUS_07 3;
BA_ "GenSigStartValue" SG_ 1413 SI_BUS_07 1;
BA_ "GenSigSwitchedByIgnition" SG_ 1413 SI_BUS_07 0;
BA_ "GenSigSendType" SG_ 1413 SI_BUS_08 3;
BA_ "GenSigStartValue" SG_ 1413 SI_BUS_08 1;
BA_ "GenSigSwitchedByIgnition" SG_ 1413 SI_BUS_08 0;
BA_ "GenSigSendType" SG_ 1413 SI_BUS_09 3;
BA_ "GenSigStartValue" SG_ 1413 SI_BUS_09 1;
BA_ "GenSigSwitchedByIgnition" SG_ 1413 SI_BUS_09 0;
BA_ "GenSigSendType" SG_ 1413 SI_BUS_10 3;
BA_ "GenSigStartValue" SG_ 1413 SI_BUS_10 1;
BA_ "GenSigSwitchedByIgnition" SG_ 1413 SI_BUS_10 0;
BA_ "GenSigSendType" SG_ 1413 SI_BUS_11 3;
BA_ "GenSigStartValue" SG_ 1413 SI_BUS_11 1;
BA_ "GenSigSwitchedByIgnition" SG_ 1413 SI_BUS_11 0;
BA_ "GenSigSendType" SG_ 1413 SI_BUS_12 3;
BA_ "GenSigStartValue" SG_ 1413 SI_BUS_12 1;
BA_ "GenSigSwitchedByIgnition" SG_ 1413 SI_BUS_12 0;
BA_ "GenSigSendType" SG_ 1413 SI_BUS_13 3;
BA_ "GenSigStartValue" SG_ 1413 SI_BUS_13 1;
BA_ "GenSigSwitchedByIgnition" SG_ 1413 SI_BUS_13 0;
BA_ "GenSigSendType" SG_ 1413 SI_BUS_14 3;
BA_ "GenSigStartValue" SG_ 1413 SI_BUS_14 1;
BA_ "GenSigSwitchedByIgnition" SG_ 1413 SI_BUS_14 0;
BA_ "GenSigSendType" SG_ 1413 SI_BUS_15 3;
BA_ "GenSigStartValue" SG_ 1413 SI_BUS_15 1;
BA_ "GenSigSwitchedByIgnition" SG_ 1413 SI_BUS_15 0;
BA_ "GenSigSendType" SG_ 1413 SI_Bus_Identifikation 0;
BA_ "GenSigSwitchedByIgnition" SG_ 1413 SI_Bus_Identifikation 0;
BA_ "GenSigSendType" SG_ 1413 SI_CAB 3;
BA_ "GenSigFuncType" SG_ 1413 SI_CAB 16;
BA_ "GenSigSwitchedByIgnition" SG_ 1413 SI_CAB 0;
BA_ "GenSigSendType" SG_ 1413 SI_Diagnose_Aktiv 3;
BA_ "GenSigSwitchedByIgnition" SG_ 1413 SI_Diagnose_Aktiv 0;
BA_ "GenSigSendType" SG_ 1413 SI_NWDF 3;
BA_ "GenSigSwitchedByIgnition" SG_ 1413 SI_NWDF 0;
BA_ "GenSigSendType" SG_ 1413 SI_NWDF_gueltig 3;
BA_ "GenSigFuncType" SG_ 1413 SI_NWDF_gueltig 8;
BA_ "GenSigSwitchedByIgnition" SG_ 1413 SI_NWDF_gueltig 0;
BA_ "GenSigSendType" SG_ 1413 SI_QRS_Mode 3;
BA_ "GenSigSwitchedByIgnition" SG_ 1413 SI_QRS_Mode 0;
BA_ "GenSigSendType" SG_ 1413 SI_Sammel_SG_Fehler 0;
BA_ "GenSigStartValue" SG_ 1413 SI_Sammel_SG_Fehler 63;
BA_ "GenSigSwitchedByIgnition" SG_ 1413 SI_Sammel_SG_Fehler 0;
BA_ "GenSigSendType" SG_ 1413 SI_Sammelfehler 3;
BA_ "GenSigSwitchedByIgnition" SG_ 1413 SI_Sammelfehler 0;
BA_ "GenSigSendType" SG_ 1413 SI_T_Mode 3;
BA_ "GenSigSwitchedByIgnition" SG_ 1413 SI_T_Mode 0;
BA_ "GenSigSendType" SG_ 1413 SI_T_Schutz 3;
BA_ "GenSigSwitchedByIgnition" SG_ 1413 SI_T_Schutz 0;
BA_ "GenSigSendType" SG_ 619 TA_aktiv_HMI 3;
BA_ "GenSigSendType" SG_ 619 TA_Fehler 3;
BA_ "GenSigSendType" SG_ 619 TA_FoD_Status 3;
BA_ "GenSigSendType" SG_ 1604 TG_Geber_1 0;
BA_ "GenSigSwitchedByIgnition" SG_ 1604 TG_Geber_1 0;
BA_ "Fehlerwert" SG_ 1604 TG_Geber_1 4095;
BA_ "GenSigSendType" SG_ 1604 TG_Geber_2 0;
BA_ "GenSigSwitchedByIgnition" SG_ 1604 TG_Geber_2 0;
BA_ "Fehlerwert" SG_ 1604 TG_Geber_2 4095;
BA_ "GenSigSendType" SG_ 1604 TG_Geber_3 0;
BA_ "GenSigSwitchedByIgnition" SG_ 1604 TG_Geber_3 0;
BA_ "Fehlerwert" SG_ 1604 TG_Geber_3 4095;
BA_ "GenSigSendType" SG_ 1604 TG_Geber_4 0;
BA_ "GenSigSwitchedByIgnition" SG_ 1604 TG_Geber_4 0;
BA_ "Fehlerwert" SG_ 1604 TG_Geber_4 4095;
BA_ "GenSigSendType" SG_ 1604 TG_Guete_Geber_1 0;
BA_ "GenSigStartValue" SG_ 1604 TG_Guete_Geber_1 14;
BA_ "GenSigSwitchedByIgnition" SG_ 1604 TG_Guete_Geber_1 0;
BA_ "Fehlerwert" SG_ 1604 TG_Guete_Geber_1 15;
BA_ "GenSigSendType" SG_ 1604 TG_Guete_Geber_2 0;
BA_ "GenSigStartValue" SG_ 1604 TG_Guete_Geber_2 14;
BA_ "GenSigSwitchedByIgnition" SG_ 1604 TG_Guete_Geber_2 0;
BA_ "Fehlerwert" SG_ 1604 TG_Guete_Geber_2 15;
BA_ "GenSigSendType" SG_ 1604 TG_Guete_Geber_3 0;
BA_ "GenSigStartValue" SG_ 1604 TG_Guete_Geber_3 14;
BA_ "GenSigSwitchedByIgnition" SG_ 1604 TG_Guete_Geber_3 0;
BA_ "Fehlerwert" SG_ 1604 TG_Guete_Geber_3 15;
BA_ "GenSigSendType" SG_ 1604 TG_Guete_Geber_4 0;
BA_ "GenSigStartValue" SG_ 1604 TG_Guete_Geber_4 14;
BA_ "GenSigSwitchedByIgnition" SG_ 1604 TG_Guete_Geber_4 0;
BA_ "Fehlerwert" SG_ 1604 TG_Guete_Geber_4 15;
BA_ "GenSigSendType" SG_ 1001 Thermo_Pred_Innen_Kunde_Anf 0;
BA_ "GenSigSwitchedByIgnition" SG_ 1001 Thermo_Pred_Innen_Kunde_Anf 0;
BA_ "GenSigSendType" SG_ 1001 Thermo_Pred_Innen_System_Anf 0;
BA_ "GenSigSwitchedByIgnition" SG_ 1001 Thermo_Pred_Innen_System_Anf 0;
BA_ "GenSigSendType" SG_ 1001 Thermo_Pred_P_dyn_Innen 0;
BA_ "GenSigStartValue" SG_ 1001 Thermo_Pred_P_dyn_Innen 2046;
BA_ "GenSigSwitchedByIgnition" SG_ 1001 Thermo_Pred_P_dyn_Innen 0;
BA_ "Fehlerwert" SG_ 1001 Thermo_Pred_P_dyn_Innen 2047;
BA_ "GenSigSendType" SG_ 1001 Thermo_Pred_P_stat_Innen 0;
BA_ "GenSigStartValue" SG_ 1001 Thermo_Pred_P_stat_Innen 2046;
BA_ "GenSigSwitchedByIgnition" SG_ 1001 Thermo_Pred_P_stat_Innen 0;
BA_ "Fehlerwert" SG_ 1001 Thermo_Pred_P_stat_Innen 2047;
BA_ "GenSigSendType" SG_ 1001 Thermo_Pred_T_dyn_Innen 0;
BA_ "GenSigStartValue" SG_ 1001 Thermo_Pred_T_dyn_Innen 254;
BA_ "GenSigSwitchedByIgnition" SG_ 1001 Thermo_Pred_T_dyn_Innen 0;
BA_ "Fehlerwert" SG_ 1001 Thermo_Pred_T_dyn_Innen 255;
BA_ "GenSigSendType" SG_ 1001 Thermo_Verbrauch_BTL 0;
BA_ "GenSigSwitchedByIgnition" SG_ 1001 Thermo_Verbrauch_BTL 0;
BA_ "GenSigSendType" SG_ 1001 Thermo_Verbrauch_BTL_Ueberlauf 0;
BA_ "GenSigSwitchedByIgnition" SG_ 1001 Thermo_Verbrauch_BTL_Ueberlauf 0;
BA_ "GenSigSendType" SG_ 1001 Thermo_Verbrauch_Innen 0;
BA_ "GenSigSwitchedByIgnition" SG_ 1001 Thermo_Verbrauch_Innen 0;
BA_ "GenSigSendType" SG_ 1001 Thermo_Verbrauch_Innen_Ueberlauf 0;
BA_ "GenSigSwitchedByIgnition" SG_ 1001 Thermo_Verbrauch_Innen_Ueberlauf 0;
BA_ "GenSigSendType" SG_ 1375 TME_Absperrventil1_oeffnen 0;
BA_ "GenSigSwitchedByIgnition" SG_ 1375 TME_Absperrventil1_oeffnen 0;
BA_ "GenSigSendType" SG_ 1375 TME_AC_LED 3;
BA_ "GenSigSwitchedByIgnition" SG_ 1375 TME_AC_LED 0;
BA_ "GenSigSendType" SG_ 1375 TME_AC_Rueckmeldung 0;
BA_ "GenSigSwitchedByIgnition" SG_ 1375 TME_AC_Rueckmeldung 0;
BA_ "Fehlerwert" SG_ 1375 TME_AC_Rueckmeldung 3;
BA_ "GenSigSendType" SG_ 1375 TME_Freigabe_Luft_PTC 0;
BA_ "GenSigSwitchedByIgnition" SG_ 1375 TME_Freigabe_Luft_PTC 0;
BA_ "GenSigSendType" SG_ 1375 TME_Freigabe_Vorkond 3;
BA_ "GenSigSwitchedByIgnition" SG_ 1375 TME_Freigabe_Vorkond 0;
BA_ "GenSigSendType" SG_ 1375 TME_Frischluftklappe_Soll 0;
BA_ "GenSigStartValue" SG_ 1375 TME_Frischluftklappe_Soll 126;
BA_ "GenSigSwitchedByIgnition" SG_ 1375 TME_Frischluftklappe_Soll 0;
BA_ "Fehlerwert" SG_ 1375 TME_Frischluftklappe_Soll 127;
BA_ "GenSigSendType" SG_ 1375 TME_Heizstrategie 3;
BA_ "GenSigSwitchedByIgnition" SG_ 1375 TME_Heizstrategie 0;
BA_ "Fehlerwert" SG_ 1375 TME_Heizstrategie 15;
BA_ "GenSigSendType" SG_ 1375 TME_Heizungspumpen_Anst 0;
BA_ "GenSigStartValue" SG_ 1375 TME_Heizungspumpen_Anst 14;
BA_ "GenSigSwitchedByIgnition" SG_ 1375 TME_Heizungspumpen_Anst 0;
BA_ "Fehlerwert" SG_ 1375 TME_Heizungspumpen_Anst 13;
BA_ "GenSigSendType" SG_ 1375 TME_Kbr_Innenraum 3;
BA_ "GenSigSwitchedByIgnition" SG_ 1375 TME_Kbr_Innenraum 0;
BA_ "GenSigSendType" SG_ 1375 TME_Klima_Defizit 0;
BA_ "GenSigStartValue" SG_ 1375 TME_Klima_Defizit 254;
BA_ "GenSigSwitchedByIgnition" SG_ 1375 TME_Klima_Defizit 0;
BA_ "Fehlerwert" SG_ 1375 TME_Klima_Defizit 255;
BA_ "GenSigSendType" SG_ 1375 TME_Kuehlmittel_Sensor 0;
BA_ "GenSigSwitchedByIgnition" SG_ 1375 TME_Kuehlmittel_Sensor 0;
BA_ "GenSigSendType" SG_ 1375 TME_Nachlaufzeit_Heizp 0;
BA_ "GenSigSwitchedByIgnition" SG_ 1375 TME_Nachlaufzeit_Heizp 0;
BA_ "GenSigSendType" SG_ 1375 TME_Systemstatus 3;
BA_ "GenSigSwitchedByIgnition" SG_ 1375 TME_Systemstatus 0;
BA_ "Fehlerwert" SG_ 1375 TME_Systemstatus 3;
BA_ "GenSigSendType" SG_ 1375 TME_Temp_KM_vor_HWT 0;
BA_ "GenSigStartValue" SG_ 1375 TME_Temp_KM_vor_HWT 254;
BA_ "GenSigSwitchedByIgnition" SG_ 1375 TME_Temp_KM_vor_HWT 0;
BA_ "Fehlerwert" SG_ 1375 TME_Temp_KM_vor_HWT 255;
BA_ "GenSigSendType" SG_ 1375 TME_Umluftklappe_Soll 0;
BA_ "GenSigSwitchedByIgnition" SG_ 1375 TME_Umluftklappe_Soll 0;
BA_ "Fehlerwert" SG_ 1375 TME_Umluftklappe_Soll 127;
BA_ "GenSigSendType" SG_ 1375 TME_Verdampfer_Status 3;
BA_ "GenSigSwitchedByIgnition" SG_ 1375 TME_Verdampfer_Status 0;
BA_ "GenSigSendType" SG_ 1375 TME_VoKo_Strategie_Anzeige 3;
BA_ "GenSigStartValue" SG_ 1375 TME_VoKo_Strategie_Anzeige 14;
BA_ "GenSigSwitchedByIgnition" SG_ 1375 TME_VoKo_Strategie_Anzeige 0;
BA_ "Fehlerwert" SG_ 1375 TME_VoKo_Strategie_Anzeige 15;
BA_ "GenSigSendType" SG_ 1375 TME_Waermepumpe_aktiv 0;
BA_ "GenSigSwitchedByIgnition" SG_ 1375 TME_Waermepumpe_aktiv 0;
BA_ "GenSigSendType" SG_ 1375 TME_Zuheizer_Freigabe 3;
BA_ "GenSigSwitchedByIgnition" SG_ 1375 TME_Zuheizer_Freigabe 0;
BA_ "GenSigSendType" SG_ 1657 TME_Eingriff_SKE_Oeffnung 0;
BA_ "GenSigSwitchedByIgnition" SG_ 1657 TME_Eingriff_SKE_Oeffnung 0;
BA_ "GenSigSendType" SG_ 1657 TME_EKK_ProtectionMode 0;
BA_ "GenSigSwitchedByIgnition" SG_ 1657 TME_EKK_ProtectionMode 0;
BA_ "GenSigSendType" SG_ 1657 TME_Klimaanforderung 0;
BA_ "GenSigSwitchedByIgnition" SG_ 1657 TME_Klimaanforderung 0;
BA_ "GenSigSendType" SG_ 1657 TME_Klimaleistung 0;
BA_ "GenSigStartValue" SG_ 1657 TME_Klimaleistung 126;
BA_ "GenSigSwitchedByIgnition" SG_ 1657 TME_Klimaleistung 0;
BA_ "GenSigSendType" SG_ 1657 TME_SKE_Pos_Summe 0;
BA_ "GenSigStartValue" SG_ 1657 TME_SKE_Pos_Summe 14;
BA_ "GenSigSwitchedByIgnition" SG_ 1657 TME_SKE_Pos_Summe 0;
BA_ "GenSigSendType" SG_ 1657 TME_SKE_Position_1 0;
BA_ "GenSigStartValue" SG_ 1657 TME_SKE_Position_1 3;
BA_ "GenSigSwitchedByIgnition" SG_ 1657 TME_SKE_Position_1 0;
BA_ "GenSigSendType" SG_ 1657 TME_SKE_PosResp 0;
BA_ "GenSigStartValue" SG_ 1657 TME_SKE_PosResp 1;
BA_ "GenSigSwitchedByIgnition" SG_ 1657 TME_SKE_PosResp 0;
BA_ "GenSigSendType" SG_ 1657 TME_SKE_Status 0;
BA_ "GenSigSwitchedByIgnition" SG_ 1657 TME_SKE_Status 0;
BA_ "Fehlerwert" SG_ 1657 TME_SKE_Status 3;
BA_ "GenSigSendType" SG_ 1657 TME_Status_Kuehlmittel_Tmp_CrChk 0;
BA_ "GenSigSwitchedByIgnition" SG_ 1657 TME_Status_Kuehlmittel_Tmp_CrChk 0;
BA_ "GenSigSendType" SG_ 1657 TME_Systemtemp 0;
BA_ "GenSigStartValue" SG_ 1657 TME_Systemtemp 254;
BA_ "GenSigSwitchedByIgnition" SG_ 1657 TME_Systemtemp 0;
BA_ "Fehlerwert" SG_ 1657 TME_Systemtemp 255;
BA_ "GenSigSendType" SG_ 1657 TME_TCP_Kond_active 0;
BA_ "GenSigSwitchedByIgnition" SG_ 1657 TME_TCP_Kond_active 0;
BA_ "GenSigSendType" SG_ 1657 TME_Temp_KM_nach_EM 0;
BA_ "GenSigStartValue" SG_ 1657 TME_Temp_KM_nach_EM 254;
BA_ "GenSigSwitchedByIgnition" SG_ 1657 TME_Temp_KM_nach_EM 0;
BA_ "Fehlerwert" SG_ 1657 TME_Temp_KM_nach_EM 255;
BA_ "GenSigSendType" SG_ 1657 TME_Temp_KM_vor_eATL 0;
BA_ "GenSigSwitchedByIgnition" SG_ 1657 TME_Temp_KM_vor_eATL 0;
BA_ "Fehlerwert" SG_ 1657 TME_Temp_KM_vor_eATL 255;
BA_ "GenSigSendType" SG_ 1657 TME_Temperatur_Ruecklauf_VKM 0;
BA_ "GenSigStartValue" SG_ 1657 TME_Temperatur_Ruecklauf_VKM 254;
BA_ "GenSigSwitchedByIgnition" SG_ 1657 TME_Temperatur_Ruecklauf_VKM 0;
BA_ "Fehlerwert" SG_ 1657 TME_Temperatur_Ruecklauf_VKM 255;
BA_ "GenSigSendType" SG_ 1657 TME_Waermebilanz 0;
BA_ "GenSigSwitchedByIgnition" SG_ 1657 TME_Waermebilanz 0;
BA_ "GenSigSendType" SG_ 1657 TME_Waermebilanz_Status 0;
BA_ "GenSigSwitchedByIgnition" SG_ 1657 TME_Waermebilanz_Status 0;
BA_ "Fehlerwert" SG_ 1657 TME_Waermebilanz_Status 3;
BA_ "GenSigSendType" SG_ 2527679762 TPUI_WarnLvlCmft 0;
BA_ "GenSigStartValue" SG_ 2527679762 TPUI_WarnLvlCmft 14;
BA_ "GenSigSwitchedByIgnition" SG_ 2527679762 TPUI_WarnLvlCmft 0;
BA_ "Fehlerwert" SG_ 2527679762 TPUI_WarnLvlCmft 15;
BA_ "GenSigSendType" SG_ 2527679762 TPUI_WarnLvlMaxV 0;
BA_ "GenSigStartValue" SG_ 2527679762 TPUI_WarnLvlMaxV 14;
BA_ "GenSigSwitchedByIgnition" SG_ 2527679762 TPUI_WarnLvlMaxV 0;
BA_ "Fehlerwert" SG_ 2527679762 TPUI_WarnLvlMaxV 15;
BA_ "GenSigSendType" SG_ 977 ASW_Warnung_aktiv_BFS 0;
BA_ "GenSigSwitchedByIgnition" SG_ 977 ASW_Warnung_aktiv_BFS 0;
BA_ "GenSigSendType" SG_ 977 BFS_Status_eTAG 0;
BA_ "GenSigSwitchedByIgnition" SG_ 977 BFS_Status_eTAG 0;
BA_ "Fehlerwert" SG_ 977 BFS_Status_eTAG 3;
BA_ "GenSigSendType" SG_ 977 BT_ASW_HMI_defekt 0;
BA_ "GenSigSwitchedByIgnition" SG_ 977 BT_ASW_HMI_defekt 0;
BA_ "GenSigSendType" SG_ 977 BT_EC_Spiegel_Helligkeit 0;
BA_ "GenSigSwitchedByIgnition" SG_ 977 BT_EC_Spiegel_Helligkeit 0;
BA_ "GenSigSendType" SG_ 977 BT_FH_Bew_hoch 0;
BA_ "GenSigSwitchedByIgnition" SG_ 977 BT_FH_Bew_hoch 0;
BA_ "GenSigSendType" SG_ 977 BT_FH_Bew_tief 0;
BA_ "GenSigSwitchedByIgnition" SG_ 977 BT_FH_Bew_tief 0;
BA_ "GenSigSendType" SG_ 977 BT_FH_Block 0;
BA_ "GenSigSwitchedByIgnition" SG_ 977 BT_FH_Block 0;
BA_ "GenSigSendType" SG_ 977 BT_FH_Fang 0;
BA_ "GenSigSwitchedByIgnition" SG_ 977 BT_FH_Fang 0;
BA_ "GenSigSendType" SG_ 977 BT_FH_normiert 0;
BA_ "GenSigSwitchedByIgnition" SG_ 977 BT_FH_normiert 0;
BA_ "GenSigSendType" SG_ 977 BT_FH_Oeffnung 3;
BA_ "GenSigSwitchedByIgnition" SG_ 977 BT_FH_Oeffnung 0;
BA_ "GenSigSendType" SG_ 977 BT_FH_Pos_oben 0;
BA_ "GenSigSwitchedByIgnition" SG_ 977 BT_FH_Pos_oben 0;
BA_ "GenSigSendType" SG_ 977 BT_FH_S_AutoHoch 0;
BA_ "GenSigSwitchedByIgnition" SG_ 977 BT_FH_S_AutoHoch 0;
BA_ "GenSigSendType" SG_ 977 BT_FH_S_AutoTief 0;
BA_ "GenSigSwitchedByIgnition" SG_ 977 BT_FH_S_AutoTief 0;
BA_ "GenSigSendType" SG_ 977 BT_FH_S_ManHoch 0;
BA_ "GenSigSwitchedByIgnition" SG_ 977 BT_FH_S_ManHoch 0;
BA_ "GenSigSendType" SG_ 977 BT_FH_S_ManTief 0;
BA_ "GenSigSwitchedByIgnition" SG_ 977 BT_FH_S_ManTief 0;
BA_ "GenSigSendType" SG_ 977 BT_FH_Thermo 0;
BA_ "GenSigSwitchedByIgnition" SG_ 977 BT_FH_Thermo 0;
BA_ "GenSigSendType" SG_ 977 BT_gesafet 0;
BA_ "GenSigSwitchedByIgnition" SG_ 977 BT_gesafet 0;
BA_ "GenSigSendType" SG_ 977 BT_Kisi_Fehler 0;
BA_ "GenSigSwitchedByIgnition" SG_ 977 BT_Kisi_Fehler 0;
BA_ "Fehlerwert" SG_ 977 BT_Kisi_Fehler 1;
BA_ "GenSigSendType" SG_ 977 BT_Lock_Taster 0;
BA_ "GenSigSwitchedByIgnition" SG_ 977 BT_Lock_Taster 0;
BA_ "GenSigSendType" SG_ 977 BT_Lock_Taster_inv 0;
BA_ "GenSigSwitchedByIgnition" SG_ 977 BT_Lock_Taster_inv 0;
BA_ "GenSigSendType" SG_ 977 BT_Oben_Block_erw 0;
BA_ "GenSigSwitchedByIgnition" SG_ 977 BT_Oben_Block_erw 0;
BA_ "GenSigSendType" SG_ 977 BT_Schliesstaster 0;
BA_ "GenSigSwitchedByIgnition" SG_ 977 BT_Schliesstaster 0;
BA_ "GenSigSendType" SG_ 977 BT_Schluesselschalter_auf 0;
BA_ "GenSigSwitchedByIgnition" SG_ 977 BT_Schluesselschalter_auf 0;
BA_ "GenSigSendType" SG_ 977 BT_Schluesselschalter_zu 0;
BA_ "GenSigSwitchedByIgnition" SG_ 977 BT_Schluesselschalter_zu 0;
BA_ "GenSigSendType" SG_ 977 BT_Schluesselschalter_zu_inv 0;
BA_ "GenSigSwitchedByIgnition" SG_ 977 BT_Schluesselschalter_zu_inv 0;
BA_ "GenSigSendType" SG_ 977 BT_SP_ausgerastet 0;
BA_ "GenSigSwitchedByIgnition" SG_ 977 BT_SP_ausgerastet 0;
BA_ "GenSigSendType" SG_ 977 BT_Sp_Blk_def 0;
BA_ "GenSigSwitchedByIgnition" SG_ 977 BT_Sp_Blk_def 0;
BA_ "GenSigSendType" SG_ 977 BT_SP_Heizung_aktiv 0;
BA_ "GenSigSwitchedByIgnition" SG_ 977 BT_SP_Heizung_aktiv 0;
BA_ "GenSigSendType" SG_ 977 BT_Sp_Heizung_Anf 0;
BA_ "GenSigSwitchedByIgnition" SG_ 977 BT_Sp_Heizung_Anf 0;
BA_ "GenSigSendType" SG_ 977 BT_SP_Heizung_Status 0;
BA_ "GenSigSwitchedByIgnition" SG_ 977 BT_SP_Heizung_Status 0;
BA_ "GenSigSendType" SG_ 977 BT_SP_ht_aktiv 0;
BA_ "GenSigSwitchedByIgnition" SG_ 977 BT_SP_ht_aktiv 0;
BA_ "GenSigSendType" SG_ 977 BT_SP_lr_aktiv 0;
BA_ "GenSigSwitchedByIgnition" SG_ 977 BT_SP_lr_aktiv 0;
BA_ "GenSigSendType" SG_ 977 BT_Sperrklinke 0;
BA_ "GenSigSwitchedByIgnition" SG_ 977 BT_Sperrklinke 0;
BA_ "GenSigSendType" SG_ 977 BT_SWA_HMI_defekt 0;
BA_ "GenSigSwitchedByIgnition" SG_ 977 BT_SWA_HMI_defekt 0;
BA_ "GenSigSendType" SG_ 977 BT_TAG_betaetigt 0;
BA_ "GenSigSwitchedByIgnition" SG_ 977 BT_TAG_betaetigt 0;
BA_ "GenSigSendType" SG_ 977 BT_TCR_Mode_aktiv 0;
BA_ "GenSigSwitchedByIgnition" SG_ 977 BT_TCR_Mode_aktiv 0;
BA_ "GenSigSendType" SG_ 977 BT_TIG_betaetigt 0;
BA_ "GenSigSwitchedByIgnition" SG_ 977 BT_TIG_betaetigt 0;
BA_ "GenSigSendType" SG_ 977 BT_TSG_hinten_verbaut 0;
BA_ "GenSigSwitchedByIgnition" SG_ 977 BT_TSG_hinten_verbaut 0;
BA_ "GenSigSendType" SG_ 977 BT_Tuer_geoeffnet 3;
BA_ "GenSigSwitchedByIgnition" SG_ 977 BT_Tuer_geoeffnet 0;
BA_ "GenSigSendType" SG_ 977 BT_Tuer_Status 0;
BA_ "GenSigSwitchedByIgnition" SG_ 977 BT_Tuer_Status 0;
BA_ "Fehlerwert" SG_ 977 BT_Tuer_Status 3;
BA_ "GenSigSendType" SG_ 977 BT_Tuer_Status_QBit 0;
BA_ "GenSigSwitchedByIgnition" SG_ 977 BT_Tuer_Status_QBit 0;
BA_ "GenSigSendType" SG_ 977 BT_Tueroeffnen_Warnung 3;
BA_ "GenSigSwitchedByIgnition" SG_ 977 BT_Tueroeffnen_Warnung 0;
BA_ "GenSigSendType" SG_ 977 BT_Tuerschloss_defekt 3;
BA_ "GenSigSwitchedByIgnition" SG_ 977 BT_Tuerschloss_defekt 0;
BA_ "GenSigSendType" SG_ 977 BT_UEKB_aktiviert 0;
BA_ "GenSigSwitchedByIgnition" SG_ 977 BT_UEKB_aktiviert 0;
BA_ "GenSigSendType" SG_ 977 BT_Unlock_Taster 0;
BA_ "GenSigSwitchedByIgnition" SG_ 977 BT_Unlock_Taster 0;
BA_ "GenSigSendType" SG_ 977 BT_Unten_Block_erw 0;
BA_ "GenSigSwitchedByIgnition" SG_ 977 BT_Unten_Block_erw 0;
BA_ "GenSigSendType" SG_ 977 BT_verriegelt 0;
BA_ "GenSigSwitchedByIgnition" SG_ 977 BT_verriegelt 0;
BA_ "GenSigSendType" SG_ 977 BT_Zuziehhilfe_aktiv 0;
BA_ "GenSigSwitchedByIgnition" SG_ 977 BT_Zuziehhilfe_aktiv 0;
BA_ "GenSigSendType" SG_ 976 ASW_HMI_defekt 0;
BA_ "GenSigSwitchedByIgnition" SG_ 976 ASW_HMI_defekt 0;
BA_ "GenSigSendType" SG_ 976 ASW_wakeup 0;
BA_ "GenSigSwitchedByIgnition" SG_ 976 ASW_wakeup 0;
BA_ "GenSigSendType" SG_ 976 ASW_Warnung_aktiv_FS 0;
BA_ "GenSigSwitchedByIgnition" SG_ 976 ASW_Warnung_aktiv_FS 0;
BA_ "GenSigSendType" SG_ 976 FS_Status_eTAG 0;
BA_ "GenSigSwitchedByIgnition" SG_ 976 FS_Status_eTAG 0;
BA_ "Fehlerwert" SG_ 976 FS_Status_eTAG 3;
BA_ "GenSigSendType" SG_ 976 FT_BFS_Fond_Freigabe 0;
BA_ "GenSigSwitchedByIgnition" SG_ 976 FT_BFS_Fond_Freigabe 0;
BA_ "GenSigSendType" SG_ 976 FT_Daemmglas 0;
BA_ "GenSigSwitchedByIgnition" SG_ 976 FT_Daemmglas 0;
BA_ "GenSigSendType" SG_ 976 FT_FH_Bew_hoch 0;
BA_ "GenSigSwitchedByIgnition" SG_ 976 FT_FH_Bew_hoch 0;
BA_ "GenSigSendType" SG_ 976 FT_FH_Bew_tief 0;
BA_ "GenSigSwitchedByIgnition" SG_ 976 FT_FH_Bew_tief 0;
BA_ "GenSigSendType" SG_ 976 FT_FH_Block 0;
BA_ "GenSigSwitchedByIgnition" SG_ 976 FT_FH_Block 0;
BA_ "GenSigSendType" SG_ 976 FT_FH_Fang 0;
BA_ "GenSigSwitchedByIgnition" SG_ 976 FT_FH_Fang 0;
BA_ "GenSigSendType" SG_ 976 FT_FH_normiert 0;
BA_ "GenSigSwitchedByIgnition" SG_ 976 FT_FH_normiert 0;
BA_ "GenSigSendType" SG_ 976 FT_FH_Oeffnung 3;
BA_ "GenSigSwitchedByIgnition" SG_ 976 FT_FH_Oeffnung 0;
BA_ "GenSigSendType" SG_ 976 FT_FH_Pos_oben 0;
BA_ "GenSigSwitchedByIgnition" SG_ 976 FT_FH_Pos_oben 0;
BA_ "GenSigSendType" SG_ 976 FT_FH_S_AutoHoch 0;
BA_ "GenSigSwitchedByIgnition" SG_ 976 FT_FH_S_AutoHoch 0;
BA_ "GenSigSendType" SG_ 976 FT_FH_S_AutoTief 0;
BA_ "GenSigSwitchedByIgnition" SG_ 976 FT_FH_S_AutoTief 0;
BA_ "GenSigSendType" SG_ 976 FT_FH_S_ManHoch 0;
BA_ "GenSigSwitchedByIgnition" SG_ 976 FT_FH_S_ManHoch 0;
BA_ "GenSigSendType" SG_ 976 FT_FH_S_ManTief 0;
BA_ "GenSigSwitchedByIgnition" SG_ 976 FT_FH_S_ManTief 0;
BA_ "GenSigSendType" SG_ 976 FT_FH_Thermo 0;
BA_ "GenSigSwitchedByIgnition" SG_ 976 FT_FH_Thermo 0;
BA_ "GenSigSendType" SG_ 976 FT_gesafet 0;
BA_ "GenSigSwitchedByIgnition" SG_ 976 FT_gesafet 0;
BA_ "GenSigSendType" SG_ 976 FT_HD_Taste 0;
BA_ "GenSigSwitchedByIgnition" SG_ 976 FT_HD_Taste 0;
BA_ "GenSigSendType" SG_ 976 FT_HD_Taste_2 3;
BA_ "GenSigSwitchedByIgnition" SG_ 976 FT_HD_Taste_2 0;
BA_ "GenSigSendType" SG_ 976 FT_IRUE_Taste 0;
BA_ "GenSigSwitchedByIgnition" SG_ 976 FT_IRUE_Taste 0;
BA_ "GenSigSendType" SG_ 976 FT_Kisi_Fehler 3;
BA_ "GenSigSwitchedByIgnition" SG_ 976 FT_Kisi_Fehler 0;
BA_ "Fehlerwert" SG_ 976 FT_Kisi_Fehler 1;
BA_ "GenSigSendType" SG_ 976 FT_Kisi_li_aktiv 0;
BA_ "GenSigSwitchedByIgnition" SG_ 976 FT_Kisi_li_aktiv 0;
BA_ "GenSigSendType" SG_ 976 FT_Kisi_re_aktiv 0;
BA_ "GenSigSwitchedByIgnition" SG_ 976 FT_Kisi_re_aktiv 0;
BA_ "GenSigSendType" SG_ 976 FT_Kisi_Taster_li 0;
BA_ "GenSigSwitchedByIgnition" SG_ 976 FT_Kisi_Taster_li 0;
BA_ "GenSigSendType" SG_ 976 FT_Kisi_Taster_re 0;
BA_ "GenSigSwitchedByIgnition" SG_ 976 FT_Kisi_Taster_re 0;
BA_ "GenSigSendType" SG_ 976 FT_Lock_Taster 0;
BA_ "GenSigSwitchedByIgnition" SG_ 976 FT_Lock_Taster 0;
BA_ "GenSigSendType" SG_ 976 FT_Oben_Block_erw 0;
BA_ "GenSigSwitchedByIgnition" SG_ 976 FT_Oben_Block_erw 0;
BA_ "GenSigSendType" SG_ 976 FT_Schliesstaster 0;
BA_ "GenSigSwitchedByIgnition" SG_ 976 FT_Schliesstaster 0;
BA_ "GenSigSendType" SG_ 976 FT_Schluesselschalter_auf 0;
BA_ "GenSigSwitchedByIgnition" SG_ 976 FT_Schluesselschalter_auf 0;
BA_ "GenSigSendType" SG_ 976 FT_Schluesselschalter_zu 0;
BA_ "GenSigSwitchedByIgnition" SG_ 976 FT_Schluesselschalter_zu 0;
BA_ "GenSigSendType" SG_ 976 FT_SP_ausgerastet 0;
BA_ "GenSigSwitchedByIgnition" SG_ 976 FT_SP_ausgerastet 0;
BA_ "GenSigSendType" SG_ 976 FT_Sp_Blk_def 0;
BA_ "GenSigSwitchedByIgnition" SG_ 976 FT_Sp_Blk_def 0;
BA_ "GenSigSendType" SG_ 976 FT_Sp_Heizung_Anf 0;
BA_ "GenSigSwitchedByIgnition" SG_ 976 FT_Sp_Heizung_Anf 0;
BA_ "GenSigSendType" SG_ 976 FT_SP_Heizung_Status 0;
BA_ "GenSigSwitchedByIgnition" SG_ 976 FT_SP_Heizung_Status 0;
BA_ "GenSigSendType" SG_ 976 FT_SP_ht_aktiv 0;
BA_ "GenSigSwitchedByIgnition" SG_ 976 FT_SP_ht_aktiv 0;
BA_ "GenSigSendType" SG_ 976 FT_SP_lr_aktiv 0;
BA_ "GenSigSwitchedByIgnition" SG_ 976 FT_SP_lr_aktiv 0;
BA_ "GenSigSendType" SG_ 976 FT_Sperrklinke 0;
BA_ "GenSigSwitchedByIgnition" SG_ 976 FT_Sperrklinke 0;
BA_ "GenSigSendType" SG_ 976 FT_SWA_Taster 0;
BA_ "GenSigSwitchedByIgnition" SG_ 976 FT_SWA_Taster 0;
BA_ "GenSigSendType" SG_ 976 FT_TAG_betaetigt 0;
BA_ "GenSigSwitchedByIgnition" SG_ 976 FT_TAG_betaetigt 0;
BA_ "GenSigSendType" SG_ 976 FT_TD_Taste 0;
BA_ "GenSigSwitchedByIgnition" SG_ 976 FT_TD_Taste 0;
BA_ "GenSigSendType" SG_ 976 FT_TD_Taste_Fehler 0;
BA_ "GenSigSwitchedByIgnition" SG_ 976 FT_TD_Taste_Fehler 0;
BA_ "GenSigSendType" SG_ 976 FT_TIG_betaetigt 0;
BA_ "GenSigSwitchedByIgnition" SG_ 976 FT_TIG_betaetigt 0;
BA_ "GenSigSendType" SG_ 976 FT_TSG_hinten_verbaut 0;
BA_ "GenSigSwitchedByIgnition" SG_ 976 FT_TSG_hinten_verbaut 0;
BA_ "GenSigSendType" SG_ 976 FT_Tuer_geoeffnet 3;
BA_ "GenSigSwitchedByIgnition" SG_ 976 FT_Tuer_geoeffnet 0;
BA_ "GenSigSendType" SG_ 976 FT_Tuerschloss_defekt 3;
BA_ "GenSigSwitchedByIgnition" SG_ 976 FT_Tuerschloss_defekt 0;
BA_ "GenSigSendType" SG_ 976 FT_UEKB_aktiviert 0;
BA_ "GenSigSwitchedByIgnition" SG_ 976 FT_UEKB_aktiviert 0;
BA_ "GenSigSendType" SG_ 976 FT_Unlock_Taster 0;
BA_ "GenSigSwitchedByIgnition" SG_ 976 FT_Unlock_Taster 0;
BA_ "GenSigSendType" SG_ 976 FT_Unten_Block_erw 0;
BA_ "GenSigSwitchedByIgnition" SG_ 976 FT_Unten_Block_erw 0;
BA_ "GenSigSendType" SG_ 976 FT_verriegelt 0;
BA_ "GenSigSwitchedByIgnition" SG_ 976 FT_verriegelt 0;
BA_ "GenSigSendType" SG_ 976 FT_Zuziehhilfe_aktiv 0;
BA_ "GenSigSwitchedByIgnition" SG_ 976 FT_Zuziehhilfe_aktiv 0;
BA_ "GenSigSendType" SG_ 976 SSR_Temp_Freigabe 0;
BA_ "GenSigSwitchedByIgnition" SG_ 976 SSR_Temp_Freigabe 0;
BA_ "GenSigSendType" SG_ 976 SWA_HMI_Diagnose 0;
BA_ "GenSigSwitchedByIgnition" SG_ 976 SWA_HMI_Diagnose 0;
BA_ "GenSigSendType" SG_ 997 FS_Push_Tuergriff 3;
BA_ "GenSigSwitchedByIgnition" SG_ 997 FS_Push_Tuergriff 0;
BA_ "GenSigSendType" SG_ 997 FT_BFS_Tuer_Status 3;
BA_ "GenSigSwitchedByIgnition" SG_ 997 FT_BFS_Tuer_Status 0;
BA_ "Fehlerwert" SG_ 997 FT_BFS_Tuer_Status 3;
BA_ "GenSigSendType" SG_ 997 FT_HBFS_Tuer_Status 3;
BA_ "GenSigSwitchedByIgnition" SG_ 997 FT_HBFS_Tuer_Status 0;
BA_ "Fehlerwert" SG_ 997 FT_HBFS_Tuer_Status 3;
BA_ "GenSigSendType" SG_ 997 FT_HFS_Tuer_Status 3;
BA_ "GenSigSwitchedByIgnition" SG_ 997 FT_HFS_Tuer_Status 0;
BA_ "Fehlerwert" SG_ 997 FT_HFS_Tuer_Status 3;
BA_ "GenSigSendType" SG_ 997 FT_Kisi_Taster_li_02 3;
BA_ "GenSigSwitchedByIgnition" SG_ 997 FT_Kisi_Taster_li_02 0;
BA_ "GenSigSendType" SG_ 997 FT_Kisi_Taster_re_02 3;
BA_ "GenSigSwitchedByIgnition" SG_ 997 FT_Kisi_Taster_re_02 0;
BA_ "GenSigSendType" SG_ 997 FT_Lock_Taster_02 3;
BA_ "GenSigSwitchedByIgnition" SG_ 997 FT_Lock_Taster_02 0;
BA_ "GenSigSendType" SG_ 997 FT_Schluesselschalter_zu_02 3;
BA_ "GenSigSwitchedByIgnition" SG_ 997 FT_Schluesselschalter_zu_02 0;
BA_ "GenSigSendType" SG_ 997 FT_SP_Heizung_ein 3;
BA_ "GenSigSwitchedByIgnition" SG_ 997 FT_SP_Heizung_ein 0;
BA_ "GenSigSendType" SG_ 997 FT_TCR_Mode_aktiv 3;
BA_ "GenSigSwitchedByIgnition" SG_ 997 FT_TCR_Mode_aktiv 0;
BA_ "GenSigSendType" SG_ 997 FT_TD_Taste_Status 3;
BA_ "GenSigSwitchedByIgnition" SG_ 997 FT_TD_Taste_Status 0;
BA_ "GenSigSendType" SG_ 997 FT_Tuer_Status 3;
BA_ "GenSigSwitchedByIgnition" SG_ 997 FT_Tuer_Status 0;
BA_ "Fehlerwert" SG_ 997 FT_Tuer_Status 3;
BA_ "GenSigSendType" SG_ 997 FT_Tuer_Status_QBit 3;
BA_ "GenSigSwitchedByIgnition" SG_ 997 FT_Tuer_Status_QBit 0;
BA_ "GenSigSendType" SG_ 997 FT_Tueroeffnen_Warnung 3;
BA_ "GenSigSwitchedByIgnition" SG_ 997 FT_Tueroeffnen_Warnung 0;
BA_ "GenSigSendType" SG_ 997 TSG_FT_02_BZ 0;
BA_ "GenSigFuncType" SG_ 997 TSG_FT_02_BZ 1;
BA_ "GenSigSwitchedByIgnition" SG_ 997 TSG_FT_02_BZ 0;
BA_ "GenSigSendType" SG_ 997 TSG_FT_02_CRC 0;
BA_ "GenSigFuncType" SG_ 997 TSG_FT_02_CRC 2;
BA_ "GenSigSwitchedByIgnition" SG_ 997 TSG_FT_02_CRC 0;
BA_ "GenSigSendType" SG_ 975 ASW_Warnung_aktiv_HBFS 0;
BA_ "GenSigSwitchedByIgnition" SG_ 975 ASW_Warnung_aktiv_HBFS 0;
BA_ "GenSigSendType" SG_ 975 HBFS_FH_Bew_hoch 0;
BA_ "GenSigSwitchedByIgnition" SG_ 975 HBFS_FH_Bew_hoch 0;
BA_ "GenSigSendType" SG_ 975 HBFS_FH_Bew_tief 0;
BA_ "GenSigSwitchedByIgnition" SG_ 975 HBFS_FH_Bew_tief 0;
BA_ "GenSigSendType" SG_ 975 HBFS_FH_Block 0;
BA_ "GenSigSwitchedByIgnition" SG_ 975 HBFS_FH_Block 0;
BA_ "GenSigSendType" SG_ 975 HBFS_FH_Fang 0;
BA_ "GenSigSwitchedByIgnition" SG_ 975 HBFS_FH_Fang 0;
BA_ "GenSigSendType" SG_ 975 HBFS_FH_normiert 0;
BA_ "GenSigSwitchedByIgnition" SG_ 975 HBFS_FH_normiert 0;
BA_ "GenSigSendType" SG_ 975 HBFS_FH_Oeffnung 3;
BA_ "GenSigSwitchedByIgnition" SG_ 975 HBFS_FH_Oeffnung 0;
BA_ "GenSigSendType" SG_ 975 HBFS_FH_S_AutoHoch 0;
BA_ "GenSigSwitchedByIgnition" SG_ 975 HBFS_FH_S_AutoHoch 0;
BA_ "GenSigSendType" SG_ 975 HBFS_FH_S_AutoTief 0;
BA_ "GenSigSwitchedByIgnition" SG_ 975 HBFS_FH_S_AutoTief 0;
BA_ "GenSigSendType" SG_ 975 HBFS_FH_S_HFS_AutoHoch 0;
BA_ "GenSigSwitchedByIgnition" SG_ 975 HBFS_FH_S_HFS_AutoHoch 0;
BA_ "GenSigSendType" SG_ 975 HBFS_FH_S_HFS_AutoTief 0;
BA_ "GenSigSwitchedByIgnition" SG_ 975 HBFS_FH_S_HFS_AutoTief 0;
BA_ "GenSigSendType" SG_ 975 HBFS_FH_S_HFS_ManHoch 0;
BA_ "GenSigSwitchedByIgnition" SG_ 975 HBFS_FH_S_HFS_ManHoch 0;
BA_ "GenSigSendType" SG_ 975 HBFS_FH_S_HFS_ManTief 0;
BA_ "GenSigSwitchedByIgnition" SG_ 975 HBFS_FH_S_HFS_ManTief 0;
BA_ "GenSigSendType" SG_ 975 HBFS_FH_S_ManHoch 0;
BA_ "GenSigSwitchedByIgnition" SG_ 975 HBFS_FH_S_ManHoch 0;
BA_ "GenSigSendType" SG_ 975 HBFS_FH_S_ManTief 0;
BA_ "GenSigSwitchedByIgnition" SG_ 975 HBFS_FH_S_ManTief 0;
BA_ "GenSigSendType" SG_ 975 HBFS_FH_Thermo 0;
BA_ "GenSigSwitchedByIgnition" SG_ 975 HBFS_FH_Thermo 0;
BA_ "GenSigSendType" SG_ 975 HBFS_gesafet 0;
BA_ "GenSigSwitchedByIgnition" SG_ 975 HBFS_gesafet 0;
BA_ "GenSigSendType" SG_ 975 HBFS_Heckrollotaster_betaetigt 0;
BA_ "GenSigSwitchedByIgnition" SG_ 975 HBFS_Heckrollotaster_betaetigt 0;
BA_ "GenSigSendType" SG_ 975 HBFS_Lock_Taster 0;
BA_ "GenSigSwitchedByIgnition" SG_ 975 HBFS_Lock_Taster 0;
BA_ "GenSigSendType" SG_ 975 HBFS_Lock_Taster_inv 0;
BA_ "GenSigSwitchedByIgnition" SG_ 975 HBFS_Lock_Taster_inv 0;
BA_ "GenSigSendType" SG_ 975 HBFS_MRollo_Schalter 0;
BA_ "GenSigStartValue" SG_ 975 HBFS_MRollo_Schalter 6;
BA_ "GenSigSwitchedByIgnition" SG_ 975 HBFS_MRollo_Schalter 0;
BA_ "Fehlerwert" SG_ 975 HBFS_MRollo_Schalter 7;
BA_ "GenSigSendType" SG_ 975 HBFS_Oben_Block_erw 0;
BA_ "GenSigSwitchedByIgnition" SG_ 975 HBFS_Oben_Block_erw 0;
BA_ "GenSigSendType" SG_ 975 HBFS_SAD_Schalter 0;
BA_ "GenSigStartValue" SG_ 975 HBFS_SAD_Schalter 14;
BA_ "GenSigSwitchedByIgnition" SG_ 975 HBFS_SAD_Schalter 0;
BA_ "Fehlerwert" SG_ 975 HBFS_SAD_Schalter 15;
BA_ "GenSigSendType" SG_ 975 HBFS_Seitenrollo_hoch 0;
BA_ "GenSigSwitchedByIgnition" SG_ 975 HBFS_Seitenrollo_hoch 0;
BA_ "GenSigSendType" SG_ 975 HBFS_Seitenrollo_tief 0;
BA_ "GenSigSwitchedByIgnition" SG_ 975 HBFS_Seitenrollo_tief 0;
BA_ "GenSigSendType" SG_ 975 HBFS_Sperrklinke 0;
BA_ "GenSigSwitchedByIgnition" SG_ 975 HBFS_Sperrklinke 0;
BA_ "GenSigSendType" SG_ 975 HBFS_Status_eTAG 0;
BA_ "GenSigSwitchedByIgnition" SG_ 975 HBFS_Status_eTAG 0;
BA_ "Fehlerwert" SG_ 975 HBFS_Status_eTAG 3;
BA_ "GenSigSendType" SG_ 975 HBFS_Status_KiSi 0;
BA_ "GenSigSwitchedByIgnition" SG_ 975 HBFS_Status_KiSi 0;
BA_ "GenSigSendType" SG_ 975 HBFS_Status_KiSi_inv 0;
BA_ "GenSigStartValue" SG_ 975 HBFS_Status_KiSi_inv 1;
BA_ "GenSigSwitchedByIgnition" SG_ 975 HBFS_Status_KiSi_inv 0;
BA_ "GenSigSendType" SG_ 975 HBFS_TAG_betaetigt 0;
BA_ "GenSigSwitchedByIgnition" SG_ 975 HBFS_TAG_betaetigt 0;
BA_ "GenSigSendType" SG_ 975 HBFS_TIG_betaetigt 0;
BA_ "GenSigSwitchedByIgnition" SG_ 975 HBFS_TIG_betaetigt 0;
BA_ "GenSigSendType" SG_ 975 HBFS_TIG_betaetigt_schliessen 3;
BA_ "GenSigSwitchedByIgnition" SG_ 975 HBFS_TIG_betaetigt_schliessen 0;
BA_ "GenSigSendType" SG_ 975 HBFS_Tuer_geoeffnet 3;
BA_ "GenSigSwitchedByIgnition" SG_ 975 HBFS_Tuer_geoeffnet 0;
BA_ "GenSigSendType" SG_ 975 HBFS_Tuer_Status 0;
BA_ "GenSigSwitchedByIgnition" SG_ 975 HBFS_Tuer_Status 0;
BA_ "Fehlerwert" SG_ 975 HBFS_Tuer_Status 3;
BA_ "GenSigSendType" SG_ 975 HBFS_Tuer_Status_QBit 0;
BA_ "GenSigSwitchedByIgnition" SG_ 975 HBFS_Tuer_Status_QBit 0;
BA_ "GenSigSendType" SG_ 975 HBFS_Tueroeffnen_Warnung 3;
BA_ "GenSigSwitchedByIgnition" SG_ 975 HBFS_Tueroeffnen_Warnung 0;
BA_ "GenSigSendType" SG_ 975 HBFS_Tuerschloss_defekt 3;
BA_ "GenSigSwitchedByIgnition" SG_ 975 HBFS_Tuerschloss_defekt 0;
BA_ "GenSigSendType" SG_ 975 HBFS_UEKB_aktiviert 0;
BA_ "GenSigSwitchedByIgnition" SG_ 975 HBFS_UEKB_aktiviert 0;
BA_ "GenSigSendType" SG_ 975 HBFS_Unlock_Taster 0;
BA_ "GenSigSwitchedByIgnition" SG_ 975 HBFS_Unlock_Taster 0;
BA_ "GenSigSendType" SG_ 975 HBFS_Unten_Block_erw 0;
BA_ "GenSigSwitchedByIgnition" SG_ 975 HBFS_Unten_Block_erw 0;
BA_ "GenSigSendType" SG_ 975 HBFS_verriegelt 0;
BA_ "GenSigSwitchedByIgnition" SG_ 975 HBFS_verriegelt 0;
BA_ "GenSigSendType" SG_ 975 HBFS_Zuziehhilfe_aktiv 0;
BA_ "GenSigSwitchedByIgnition" SG_ 975 HBFS_Zuziehhilfe_aktiv 0;
BA_ "GenSigSendType" SG_ 975 MTHBFS_M_Taste 0;
BA_ "GenSigSwitchedByIgnition" SG_ 975 MTHBFS_M_Taste 0;
BA_ "GenSigSendType" SG_ 975 MTHBFS_Pos1 0;
BA_ "GenSigSwitchedByIgnition" SG_ 975 MTHBFS_Pos1 0;
BA_ "GenSigSendType" SG_ 975 MTHBFS_Pos2 0;
BA_ "GenSigSwitchedByIgnition" SG_ 975 MTHBFS_Pos2 0;
BA_ "GenSigSendType" SG_ 975 MTHBFS_Pos3 0;
BA_ "GenSigSwitchedByIgnition" SG_ 975 MTHBFS_Pos3 0;
BA_ "GenSigSendType" SG_ 975 SSR_HBFS_Pos_Unten 0;
BA_ "GenSigSwitchedByIgnition" SG_ 975 SSR_HBFS_Pos_Unten 0;
BA_ "GenSigSendType" SG_ 703 HBFS_Push_Tuergriff 3;
BA_ "GenSigSwitchedByIgnition" SG_ 703 HBFS_Push_Tuergriff 0;
BA_ "GenSigSendType" SG_ 703 HBFS_Status_KiSi 3;
BA_ "GenSigSwitchedByIgnition" SG_ 703 HBFS_Status_KiSi 0;
BA_ "GenSigSendType" SG_ 703 HBFS_TCR_Mode_aktiv 3;
BA_ "GenSigSwitchedByIgnition" SG_ 703 HBFS_TCR_Mode_aktiv 0;
BA_ "GenSigSendType" SG_ 703 TSG_HBFS_02_BZ 0;
BA_ "GenSigFuncType" SG_ 703 TSG_HBFS_02_BZ 1;
BA_ "GenSigSwitchedByIgnition" SG_ 703 TSG_HBFS_02_BZ 0;
BA_ "GenSigSendType" SG_ 703 TSG_HBFS_02_CRC 0;
BA_ "GenSigFuncType" SG_ 703 TSG_HBFS_02_CRC 2;
BA_ "GenSigSwitchedByIgnition" SG_ 703 TSG_HBFS_02_CRC 0;
BA_REL_ "GenSigTimeoutTime" BU_SG_REL_ CGS SG_ 1413 SI_NWDF 5000;
BA_REL_ "GenSigTimeoutTime" BU_SG_REL_ CGS SG_ 1413 SI_NWDF_gueltig 5000;
BA_REL_ "GenSigTimeoutTime" BU_SG_REL_ CGS SG_ 1413 SI_BUS_10 5000;
BA_REL_ "GenSigTimeoutTime" BU_SG_REL_ HUD SG_ 505 ACA_QF_Status_Anzeige 500;
BA_REL_ "GenSigTimeoutTime" BU_SG_REL_ HUD SG_ 666 STP_Status_Anzeige 4000;
BA_REL_ "GenSigTimeoutTime" BU_SG_REL_ HUD SG_ 666 STP_FAS_Fkt_Status 4000;
BA_REL_ "GenSigTimeoutTime" BU_SG_REL_ HUD SG_ 666 STP_Primaeranz_02 4000;
BA_REL_ "GenSigTimeoutTime" BU_SG_REL_ HUD SG_ 1413 SI_QRS_Mode 5000;
BA_REL_ "GenSigTimeoutTime" BU_SG_REL_ HUD SG_ 1413 SI_T_Mode 5000;
BA_REL_ "GenSigTimeoutTime" BU_SG_REL_ HUD SG_ 1413 SI_NWDF 5000;
BA_REL_ "GenSigTimeoutTime" BU_SG_REL_ HUD SG_ 1413 SI_NWDF_gueltig 5000;
BA_REL_ "GenSigTimeoutTime" BU_SG_REL_ HUD SG_ 1413 SI_BUS_01 5000;
BA_REL_ "GenSigTimeoutTime" BU_SG_REL_ HUD SG_ 1413 SI_BUS_03 5000;
BA_REL_ "GenSigTimeoutTime" BU_SG_REL_ HUD SG_ 1413 SI_BUS_04 5000;
BA_REL_ "GenSigTimeoutTime" BU_SG_REL_ HUD SG_ 1413 SI_BUS_06 5000;
BA_REL_ "GenSigTimeoutTime" BU_SG_REL_ HUD SG_ 619 TA_aktiv_HMI 4000;
BA_REL_ "GenSigTimeoutTime" BU_SG_REL_ HUD SG_ 619 TA_Fehler 4000;
BA_REL_ "GenSigTimeoutTime" BU_SG_REL_ HUD SG_ 976 FT_verriegelt 1000;
BA_REL_ "GenSigTimeoutTime" BU_SG_REL_ HUD SG_ 997 FT_Tuer_Status 1000;
BA_REL_ "GenSigTimeoutTime" BU_SG_REL_ Kombi SG_ 980 WH_Heckintervall 2000;
BA_REL_ "GenSigTimeoutTime" BU_SG_REL_ Kombi SG_ 980 FAS_Taster 2000;
BA_REL_ "GenSigTimeoutTime" BU_SG_REL_ Kombi SG_ 980 LRH_On_Off 2000;
BA_REL_ "GenSigTimeoutTime" BU_SG_REL_ Kombi SG_ 904 SpoilerSG_01_CRC 1000;
BA_REL_ "GenSigTimeoutTime" BU_SG_REL_ Kombi SG_ 904 SpoilerSG_01_BZ 1000;
BA_REL_ "GenSigTimeoutTime" BU_SG_REL_ Kombi SG_ 904 SpoilerSG_Fehler 1000;
BA_REL_ "GenSigTimeoutTime" BU_SG_REL_ Kombi SG_ 1313 STH_LED 2000;
BA_REL_ "GenSigTimeoutTime" BU_SG_REL_ Kombi SG_ 1313 STH_KVS 2000;
BA_REL_ "GenSigTimeoutTime" BU_SG_REL_ Kombi SG_ 1313 STH_Texte 2000;
BA_REL_ "GenSigTimeoutTime" BU_SG_REL_ Kombi SG_ 1313 STH_KVS_Ueberlauf 2000;
BA_REL_ "GenSigTimeoutTime" BU_SG_REL_ Kombi SG_ 505 ACA_QF_Status_Anzeige 500;
BA_REL_ "GenSigTimeoutTime" BU_SG_REL_ Kombi SG_ 666 STP_Abstand_Zielobjekt 4000;
BA_REL_ "GenSigTimeoutTime" BU_SG_REL_ Kombi SG_ 666 STP_Texte_ESK 4000;
BA_REL_ "GenSigTimeoutTime" BU_SG_REL_ Kombi SG_ 666 STP_Status_Anzeige 4000;
BA_REL_ "GenSigTimeoutTime" BU_SG_REL_ Kombi SG_ 666 STP_Nebenspur_links_ZA 4000;
BA_REL_ "GenSigTimeoutTime" BU_SG_REL_ Kombi SG_ 666 STP_Nebenspur_rechts_ZA 4000;
BA_REL_ "GenSigTimeoutTime" BU_SG_REL_ Kombi SG_ 666 STP_FBM_links_ZA 4000;
BA_REL_ "GenSigTimeoutTime" BU_SG_REL_ Kombi SG_ 666 STP_Geschw_Egofahrzeug_ZA 4000;
BA_REL_ "GenSigTimeoutTime" BU_SG_REL_ Kombi SG_ 666 STP_Egokolonne_ZA 4000;
BA_REL_ "GenSigTimeoutTime" BU_SG_REL_ Kombi SG_ 666 STP_FBM_rechts_ZA 4000;
BA_REL_ "GenSigTimeoutTime" BU_SG_REL_ Kombi SG_ 666 STP_Texte_ZA 4000;
BA_REL_ "GenSigTimeoutTime" BU_SG_REL_ Kombi SG_ 666 STP_Texte_AV 4000;
BA_REL_ "GenSigTimeoutTime" BU_SG_REL_ Kombi SG_ 666 STP_Texte 4000;
BA_REL_ "GenSigTimeoutTime" BU_SG_REL_ Kombi SG_ 666 STP_Primaeranz_02 4000;
BA_REL_ "GenSigTimeoutTime" BU_SG_REL_ Kombi SG_ 666 STP_Nebenspur_Geschw_links_ZA 4000;
BA_REL_ "GenSigTimeoutTime" BU_SG_REL_ Kombi SG_ 666 STP_Nebenspur_Geschw_rechts_ZA 4000;
BA_REL_ "GenSigTimeoutTime" BU_SG_REL_ Kombi SG_ 1172 STS_Texte 2000;
BA_REL_ "GenSigTimeoutTime" BU_SG_REL_ Kombi SG_ 783 SWA_Anzeigen 2000;
BA_REL_ "GenSigTimeoutTime" BU_SG_REL_ Kombi SG_ 783 SWA_Infostufe_SWA_li 2000;
BA_REL_ "GenSigTimeoutTime" BU_SG_REL_ Kombi SG_ 783 SWA_Warnung_SWA_li 2000;
BA_REL_ "GenSigTimeoutTime" BU_SG_REL_ Kombi SG_ 783 ASW_Kombitexte 2000;
BA_REL_ "GenSigTimeoutTime" BU_SG_REL_ Kombi SG_ 783 SWA_Infostufe_SWA_re 2000;
BA_REL_ "GenSigTimeoutTime" BU_SG_REL_ Kombi SG_ 783 SWA_Warnung_SWA_re 2000;
BA_REL_ "GenSigTimeoutTime" BU_SG_REL_ Kombi SG_ 783 Heckradar_Kombitexte 2000;
BA_REL_ "GenSigTimeoutTime" BU_SG_REL_ Kombi SG_ 783 RCTA_Kombitexte 2000;
BA_REL_ "GenSigTimeoutTime" BU_SG_REL_ Kombi SG_ 1413 SI_QRS_Mode 5000;
BA_REL_ "GenSigTimeoutTime" BU_SG_REL_ Kombi SG_ 1413 SI_T_Mode 5000;
BA_REL_ "GenSigTimeoutTime" BU_SG_REL_ Kombi SG_ 1413 SI_NWDF 5000;
BA_REL_ "GenSigTimeoutTime" BU_SG_REL_ Kombi SG_ 1413 SI_NWDF_gueltig 5000;
BA_REL_ "GenSigTimeoutTime" BU_SG_REL_ Kombi SG_ 1413 SI_Sammelfehler 5000;
BA_REL_ "GenSigTimeoutTime" BU_SG_REL_ Kombi SG_ 1413 SI_T_Schutz 5000;
BA_REL_ "GenSigTimeoutTime" BU_SG_REL_ Kombi SG_ 1413 SI_BUS_01 5000;
BA_REL_ "GenSigTimeoutTime" BU_SG_REL_ Kombi SG_ 1413 SI_BUS_03 5000;
BA_REL_ "GenSigTimeoutTime" BU_SG_REL_ Kombi SG_ 1413 SI_BUS_04 5000;
BA_REL_ "GenSigTimeoutTime" BU_SG_REL_ Kombi SG_ 1413 SI_BUS_06 5000;
BA_REL_ "GenSigTimeoutTime" BU_SG_REL_ Kombi SG_ 1413 SI_BUS_10 5000;
BA_REL_ "GenSigTimeoutTime" BU_SG_REL_ Kombi SG_ 1413 SI_BUS_12 5000;
BA_REL_ "GenSigTimeoutTime" BU_SG_REL_ Kombi SG_ 1413 SI_BUS_13 5000;
BA_REL_ "GenSigTimeoutTime" BU_SG_REL_ Kombi SG_ 619 TA_FoD_Status 4000;
BA_REL_ "GenSigTimeoutTime" BU_SG_REL_ Kombi SG_ 619 TA_aktiv_HMI 4000;
BA_REL_ "GenSigTimeoutTime" BU_SG_REL_ Kombi SG_ 619 TA_Fehler 4000;
BA_REL_ "GenSigTimeoutTime" BU_SG_REL_ Kombi SG_ 1604 TG_Geber_1 5000;
BA_REL_ "GenSigTimeoutTime" BU_SG_REL_ Kombi SG_ 1604 TG_Geber_2 5000;
BA_REL_ "GenSigTimeoutTime" BU_SG_REL_ Kombi SG_ 1604 TG_Geber_3 5000;
BA_REL_ "GenSigTimeoutTime" BU_SG_REL_ Kombi SG_ 1604 TG_Geber_4 5000;
BA_REL_ "GenSigTimeoutTime" BU_SG_REL_ Kombi SG_ 1604 TG_Guete_Geber_1 5000;
BA_REL_ "GenSigTimeoutTime" BU_SG_REL_ Kombi SG_ 1604 TG_Guete_Geber_2 5000;
BA_REL_ "GenSigTimeoutTime" BU_SG_REL_ Kombi SG_ 1604 TG_Guete_Geber_3 5000;
BA_REL_ "GenSigTimeoutTime" BU_SG_REL_ Kombi SG_ 1604 TG_Guete_Geber_4 5000;
BA_REL_ "GenSigTimeoutTime" BU_SG_REL_ Kombi SG_ 1001 Thermo_Pred_T_dyn_Innen 1000;
BA_REL_ "GenSigTimeoutTime" BU_SG_REL_ Kombi SG_ 1001 Thermo_Pred_Innen_Kunde_Anf 1000;
BA_REL_ "GenSigTimeoutTime" BU_SG_REL_ Kombi SG_ 1001 Thermo_Pred_P_dyn_Innen 1000;
BA_REL_ "GenSigTimeoutTime" BU_SG_REL_ Kombi SG_ 1001 Thermo_Pred_P_stat_Innen 1000;
BA_REL_ "GenSigTimeoutTime" BU_SG_REL_ Kombi SG_ 1001 Thermo_Verbrauch_BTL 1000;
BA_REL_ "GenSigTimeoutTime" BU_SG_REL_ Kombi SG_ 1001 Thermo_Verbrauch_BTL_Ueberlauf 1000;
BA_REL_ "GenSigTimeoutTime" BU_SG_REL_ Kombi SG_ 1001 Thermo_Verbrauch_Innen 1000;
BA_REL_ "GenSigTimeoutTime" BU_SG_REL_ Kombi SG_ 1001 Thermo_Verbrauch_Innen_Ueberlauf 1000;
BA_REL_ "GenSigTimeoutTime" BU_SG_REL_ Kombi SG_ 1375 TME_Kuehlmittel_Sensor 5000;
BA_REL_ "GenSigTimeoutTime" BU_SG_REL_ Kombi SG_ 1657 TME_TCP_Kond_active 5000;
BA_REL_ "GenSigTimeoutTime" BU_SG_REL_ Kombi SG_ 1657 TME_Systemtemp 5000;
BA_REL_ "GenSigTimeoutTime" BU_SG_REL_ Kombi SG_ 2527679762 TPUI_WarnLvlCmft 2000;
BA_REL_ "GenSigTimeoutTime" BU_SG_REL_ Kombi SG_ 2527679762 TPUI_WarnLvlMaxV 2000;
BA_REL_ "GenSigTimeoutTime" BU_SG_REL_ Kombi SG_ 977 BT_Sp_Blk_def 5000;
BA_REL_ "GenSigTimeoutTime" BU_SG_REL_ Kombi SG_ 977 ASW_Warnung_aktiv_BFS 5000;
BA_REL_ "GenSigTimeoutTime" BU_SG_REL_ Kombi SG_ 977 BT_Tuerschloss_defekt 5000;
BA_REL_ "GenSigTimeoutTime" BU_SG_REL_ Kombi SG_ 977 BT_Tueroeffnen_Warnung 5000;
BA_REL_ "GenSigTimeoutTime" BU_SG_REL_ Kombi SG_ 976 FT_Sp_Blk_def 1000;
BA_REL_ "GenSigTimeoutTime" BU_SG_REL_ Kombi SG_ 976 FT_Kisi_Fehler 1000;
BA_REL_ "GenSigTimeoutTime" BU_SG_REL_ Kombi SG_ 976 ASW_Warnung_aktiv_FS 1000;
BA_REL_ "GenSigTimeoutTime" BU_SG_REL_ Kombi SG_ 976 FT_Tuerschloss_defekt 1000;
BA_REL_ "GenSigTimeoutTime" BU_SG_REL_ Kombi SG_ 997 TSG_FT_02_CRC 1000;
BA_REL_ "GenSigTimeoutTime" BU_SG_REL_ Kombi SG_ 997 TSG_FT_02_BZ 1000;
BA_REL_ "GenSigTimeoutTime" BU_SG_REL_ Kombi SG_ 997 FT_Tuer_Status 1000;
BA_REL_ "GenSigTimeoutTime" BU_SG_REL_ Kombi SG_ 997 FT_Tueroeffnen_Warnung 1000;
BA_REL_ "GenSigTimeoutTime" BU_SG_REL_ Kombi SG_ 975 HBFS_Tuerschloss_defekt 5000;
BA_REL_ "GenSigTimeoutTime" BU_SG_REL_ Kombi SG_ 975 HBFS_Tueroeffnen_Warnung 5000;
BA_REL_ "GenSigTimeoutTime" BU_SG_REL_ Kombi SG_ 975 ASW_Warnung_aktiv_HBFS 5000;
BA_REL_ "GenSigTimeoutTime" BU_SG_REL_ Kombi_LB SG_ 980 WH_Intervall 2000;
BA_REL_ "GenSigTimeoutTime" BU_SG_REL_ Kombi_LB SG_ 980 WH_WischerStufe1 2000;
BA_REL_ "GenSigTimeoutTime" BU_SG_REL_ Kombi_LB SG_ 980 WH_WischerStufe2 2000;
BA_REL_ "GenSigTimeoutTime" BU_SG_REL_ Kombi_LB SG_ 980 WH_Heckintervall 2000;
BA_REL_ "GenSigTimeoutTime" BU_SG_REL_ Kombi_LB SG_ 980 FAS_Taster 2000;
BA_REL_ "GenSigTimeoutTime" BU_SG_REL_ Kombi_LB SG_ 980 LRH_On_Off 2000;
BA_REL_ "GenSigTimeoutTime" BU_SG_REL_ Kombi_LB SG_ 1313 STH_KVS_Ueberlauf 2000;
BA_REL_ "GenSigTimeoutTime" BU_SG_REL_ Kombi_LB SG_ 505 ACA_QF_Status_Anzeige 500;
BA_REL_ "GenSigTimeoutTime" BU_SG_REL_ Kombi_LB SG_ 666 STP_Abstand_Zielobjekt 4000;
BA_REL_ "GenSigTimeoutTime" BU_SG_REL_ Kombi_LB SG_ 666 STP_Texte_ESK 4000;
BA_REL_ "GenSigTimeoutTime" BU_SG_REL_ Kombi_LB SG_ 666 STP_Status_Anzeige 4000;
BA_REL_ "GenSigTimeoutTime" BU_SG_REL_ Kombi_LB SG_ 666 STP_Nebenspur_links_ZA 4000;
BA_REL_ "GenSigTimeoutTime" BU_SG_REL_ Kombi_LB SG_ 666 STP_Nebenspur_rechts_ZA 4000;
BA_REL_ "GenSigTimeoutTime" BU_SG_REL_ Kombi_LB SG_ 666 STP_FBM_links_ZA 4000;
BA_REL_ "GenSigTimeoutTime" BU_SG_REL_ Kombi_LB SG_ 666 STP_Geschw_Egofahrzeug_ZA 4000;
BA_REL_ "GenSigTimeoutTime" BU_SG_REL_ Kombi_LB SG_ 666 STP_Egokolonne_ZA 4000;
BA_REL_ "GenSigTimeoutTime" BU_SG_REL_ Kombi_LB SG_ 666 STP_FBM_rechts_ZA 4000;
BA_REL_ "GenSigTimeoutTime" BU_SG_REL_ Kombi_LB SG_ 666 STP_Texte_ZA 4000;
BA_REL_ "GenSigTimeoutTime" BU_SG_REL_ Kombi_LB SG_ 666 STP_Texte_AV 4000;
BA_REL_ "GenSigTimeoutTime" BU_SG_REL_ Kombi_LB SG_ 666 STP_Texte 4000;
BA_REL_ "GenSigTimeoutTime" BU_SG_REL_ Kombi_LB SG_ 666 STP_Primaeranz_02 4000;
BA_REL_ "GenSigTimeoutTime" BU_SG_REL_ Kombi_LB SG_ 666 STP_Nebenspur_Geschw_links_ZA 4000;
BA_REL_ "GenSigTimeoutTime" BU_SG_REL_ Kombi_LB SG_ 666 STP_Nebenspur_Geschw_rechts_ZA 4000;
BA_REL_ "GenSigTimeoutTime" BU_SG_REL_ Kombi_LB SG_ 1172 STS_Texte 2000;
BA_REL_ "GenSigTimeoutTime" BU_SG_REL_ Kombi_LB SG_ 783 SWA_Anzeigen 2000;
BA_REL_ "GenSigTimeoutTime" BU_SG_REL_ Kombi_LB SG_ 783 ASW_Kombitexte 2000;
BA_REL_ "GenSigTimeoutTime" BU_SG_REL_ Kombi_LB SG_ 783 Heckradar_Kombitexte 2000;
BA_REL_ "GenSigTimeoutTime" BU_SG_REL_ Kombi_LB SG_ 783 RCTA_Kombitexte 2000;
BA_REL_ "GenSigTimeoutTime" BU_SG_REL_ Kombi_LB SG_ 1413 SI_QRS_Mode 5000;
BA_REL_ "GenSigTimeoutTime" BU_SG_REL_ Kombi_LB SG_ 1413 SI_T_Mode 5000;
BA_REL_ "GenSigTimeoutTime" BU_SG_REL_ Kombi_LB SG_ 1413 SI_NWDF 5000;
BA_REL_ "GenSigTimeoutTime" BU_SG_REL_ Kombi_LB SG_ 1413 SI_NWDF_gueltig 5000;
BA_REL_ "GenSigTimeoutTime" BU_SG_REL_ Kombi_LB SG_ 1413 SI_Sammelfehler 5000;
BA_REL_ "GenSigTimeoutTime" BU_SG_REL_ Kombi_LB SG_ 1413 SI_T_Schutz 5000;
BA_REL_ "GenSigTimeoutTime" BU_SG_REL_ Kombi_LB SG_ 1413 SI_BUS_01 5000;
BA_REL_ "GenSigTimeoutTime" BU_SG_REL_ Kombi_LB SG_ 1413 SI_BUS_03 5000;
BA_REL_ "GenSigTimeoutTime" BU_SG_REL_ Kombi_LB SG_ 1413 SI_BUS_04 5000;
BA_REL_ "GenSigTimeoutTime" BU_SG_REL_ Kombi_LB SG_ 1413 SI_BUS_06 5000;
BA_REL_ "GenSigTimeoutTime" BU_SG_REL_ Kombi_LB SG_ 1413 SI_BUS_10 5000;
BA_REL_ "GenSigTimeoutTime" BU_SG_REL_ Kombi_LB SG_ 1413 SI_BUS_12 5000;
BA_REL_ "GenSigTimeoutTime" BU_SG_REL_ Kombi_LB SG_ 1413 SI_BUS_13 5000;
BA_REL_ "GenSigTimeoutTime" BU_SG_REL_ Kombi_LB SG_ 1604 TG_Geber_1 5000;
BA_REL_ "GenSigTimeoutTime" BU_SG_REL_ Kombi_LB SG_ 1604 TG_Geber_2 5000;
BA_REL_ "GenSigTimeoutTime" BU_SG_REL_ Kombi_LB SG_ 1604 TG_Geber_3 5000;
BA_REL_ "GenSigTimeoutTime" BU_SG_REL_ Kombi_LB SG_ 1604 TG_Geber_4 5000;
BA_REL_ "GenSigTimeoutTime" BU_SG_REL_ Kombi_LB SG_ 1604 TG_Guete_Geber_1 5000;
BA_REL_ "GenSigTimeoutTime" BU_SG_REL_ Kombi_LB SG_ 1604 TG_Guete_Geber_2 5000;
BA_REL_ "GenSigTimeoutTime" BU_SG_REL_ Kombi_LB SG_ 1604 TG_Guete_Geber_3 5000;
BA_REL_ "GenSigTimeoutTime" BU_SG_REL_ Kombi_LB SG_ 1604 TG_Guete_Geber_4 5000;
BA_REL_ "GenSigTimeoutTime" BU_SG_REL_ Kombi_LB SG_ 1001 Thermo_Pred_T_dyn_Innen 1000;
BA_REL_ "GenSigTimeoutTime" BU_SG_REL_ Kombi_LB SG_ 1001 Thermo_Pred_Innen_Kunde_Anf 1000;
BA_REL_ "GenSigTimeoutTime" BU_SG_REL_ Kombi_LB SG_ 1001 Thermo_Pred_P_dyn_Innen 1000;
BA_REL_ "GenSigTimeoutTime" BU_SG_REL_ Kombi_LB SG_ 1001 Thermo_Pred_P_stat_Innen 1000;
BA_REL_ "GenSigTimeoutTime" BU_SG_REL_ Kombi_LB SG_ 1001 Thermo_Verbrauch_BTL 1000;
BA_REL_ "GenSigTimeoutTime" BU_SG_REL_ Kombi_LB SG_ 1001 Thermo_Verbrauch_BTL_Ueberlauf 1000;
BA_REL_ "GenSigTimeoutTime" BU_SG_REL_ Kombi_LB SG_ 1001 Thermo_Verbrauch_Innen 1000;
BA_REL_ "GenSigTimeoutTime" BU_SG_REL_ Kombi_LB SG_ 1001 Thermo_Verbrauch_Innen_Ueberlauf 1000;
BA_REL_ "GenSigTimeoutTime" BU_SG_REL_ Kombi_LB SG_ 1375 TME_Kuehlmittel_Sensor 5000;
BA_REL_ "GenSigTimeoutTime" BU_SG_REL_ Kombi_LB SG_ 1657 TME_Systemtemp 5000;
BA_REL_ "GenSigTimeoutTime" BU_SG_REL_ Kombi_LB SG_ 977 BT_Sp_Blk_def 5000;
BA_REL_ "GenSigTimeoutTime" BU_SG_REL_ Kombi_LB SG_ 977 ASW_Warnung_aktiv_BFS 5000;
BA_REL_ "GenSigTimeoutTime" BU_SG_REL_ Kombi_LB SG_ 977 BT_Tuerschloss_defekt 5000;
BA_REL_ "GenSigTimeoutTime" BU_SG_REL_ Kombi_LB SG_ 977 BT_Tueroeffnen_Warnung 5000;
BA_REL_ "GenSigTimeoutTime" BU_SG_REL_ Kombi_LB SG_ 976 FT_Sp_Blk_def 1000;
BA_REL_ "GenSigTimeoutTime" BU_SG_REL_ Kombi_LB SG_ 976 FT_Kisi_Fehler 1000;
BA_REL_ "GenSigTimeoutTime" BU_SG_REL_ Kombi_LB SG_ 976 ASW_Warnung_aktiv_FS 1000;
BA_REL_ "GenSigTimeoutTime" BU_SG_REL_ Kombi_LB SG_ 976 FT_Tuerschloss_defekt 1000;
BA_REL_ "GenSigTimeoutTime" BU_SG_REL_ Kombi_LB SG_ 997 TSG_FT_02_CRC 1000;
BA_REL_ "GenSigTimeoutTime" BU_SG_REL_ Kombi_LB SG_ 997 TSG_FT_02_BZ 1000;
BA_REL_ "GenSigTimeoutTime" BU_SG_REL_ Kombi_LB SG_ 997 FT_Tuer_Status 1000;
BA_REL_ "GenSigTimeoutTime" BU_SG_REL_ Kombi_LB SG_ 997 FT_Tueroeffnen_Warnung 1000;
BA_REL_ "GenSigTimeoutTime" BU_SG_REL_ Kombi_LB SG_ 975 HBFS_Tuerschloss_defekt 5000;
BA_REL_ "GenSigTimeoutTime" BU_SG_REL_ Kombi_LB SG_ 975 HBFS_Tueroeffnen_Warnung 5000;
BA_REL_ "GenSigTimeoutTime" BU_SG_REL_ Kombi_LB SG_ 975 ASW_Warnung_aktiv_HBFS 5000;
BA_REL_ "GenSigTimeoutTime" BU_SG_REL_ Kombi_PAG SG_ 980 LRH_On_Off 2000;
BA_REL_ "GenSigTimeoutTime" BU_SG_REL_ Kombi_PAG SG_ 904 SpoilerSG_01_CRC 1000;
BA_REL_ "GenSigTimeoutTime" BU_SG_REL_ Kombi_PAG SG_ 904 SpoilerSG_01_BZ 1000;
BA_REL_ "GenSigTimeoutTime" BU_SG_REL_ Kombi_PAG SG_ 904 SpoilerSG_HSpoiler_IstPos 1000;
BA_REL_ "GenSigTimeoutTime" BU_SG_REL_ Kombi_PAG SG_ 904 SpoilerSG_Fehler 1000;
BA_REL_ "GenSigTimeoutTime" BU_SG_REL_ Kombi_PAG SG_ 904 SpoilerSG_Status 1000;
BA_REL_ "GenSigTimeoutTime" BU_SG_REL_ Kombi_PAG SG_ 904 LFE_Status 1000;
BA_REL_ "GenSigTimeoutTime" BU_SG_REL_ Kombi_PAG SG_ 1313 STH_LED 2000;
BA_REL_ "GenSigTimeoutTime" BU_SG_REL_ Kombi_PAG SG_ 1313 STH_KVS 2000;
BA_REL_ "GenSigTimeoutTime" BU_SG_REL_ Kombi_PAG SG_ 1313 STH_Texte 2000;
BA_REL_ "GenSigTimeoutTime" BU_SG_REL_ Kombi_PAG SG_ 1313 STH_KVS_Ueberlauf 2000;
BA_REL_ "GenSigTimeoutTime" BU_SG_REL_ Kombi_PAG SG_ 505 ACA_QF_Status_Anzeige 500;
BA_REL_ "GenSigTimeoutTime" BU_SG_REL_ Kombi_PAG SG_ 505 ACA_QF_Fahreruebernahme 500;
BA_REL_ "GenSigTimeoutTime" BU_SG_REL_ Kombi_PAG SG_ 666 STP_Abstand_Zielobjekt 4000;
BA_REL_ "GenSigTimeoutTime" BU_SG_REL_ Kombi_PAG SG_ 666 STP_Texte_ESK 4000;
BA_REL_ "GenSigTimeoutTime" BU_SG_REL_ Kombi_PAG SG_ 666 STP_Status_Anzeige 4000;
BA_REL_ "GenSigTimeoutTime" BU_SG_REL_ Kombi_PAG SG_ 666 STP_Nebenspur_links_ZA 4000;
BA_REL_ "GenSigTimeoutTime" BU_SG_REL_ Kombi_PAG SG_ 666 STP_Nebenspur_rechts_ZA 4000;
BA_REL_ "GenSigTimeoutTime" BU_SG_REL_ Kombi_PAG SG_ 666 STP_FBM_links_ZA 4000;
BA_REL_ "GenSigTimeoutTime" BU_SG_REL_ Kombi_PAG SG_ 666 STP_Geschw_Egofahrzeug_ZA 4000;
BA_REL_ "GenSigTimeoutTime" BU_SG_REL_ Kombi_PAG SG_ 666 STP_Egokolonne_ZA 4000;
BA_REL_ "GenSigTimeoutTime" BU_SG_REL_ Kombi_PAG SG_ 666 STP_FBM_rechts_ZA 4000;
BA_REL_ "GenSigTimeoutTime" BU_SG_REL_ Kombi_PAG SG_ 666 STP_Texte_ZA 4000;
BA_REL_ "GenSigTimeoutTime" BU_SG_REL_ Kombi_PAG SG_ 666 STP_Texte_AV 4000;
BA_REL_ "GenSigTimeoutTime" BU_SG_REL_ Kombi_PAG SG_ 666 STP_Texte 4000;
BA_REL_ "GenSigTimeoutTime" BU_SG_REL_ Kombi_PAG SG_ 666 STP_Primaeranz_02 4000;
BA_REL_ "GenSigTimeoutTime" BU_SG_REL_ Kombi_PAG SG_ 1172 STS_Texte 2000;
BA_REL_ "GenSigTimeoutTime" BU_SG_REL_ Kombi_PAG SG_ 783 SWA_Anzeigen 2000;
BA_REL_ "GenSigTimeoutTime" BU_SG_REL_ Kombi_PAG SG_ 783 SWA_Sta_aktiv 2000;
BA_REL_ "GenSigTimeoutTime" BU_SG_REL_ Kombi_PAG SG_ 783 SWA_Sta_passiv 2000;
BA_REL_ "GenSigTimeoutTime" BU_SG_REL_ Kombi_PAG SG_ 783 ASW_Status 2000;
BA_REL_ "GenSigTimeoutTime" BU_SG_REL_ Kombi_PAG SG_ 783 ASW_Kombitexte 2000;
BA_REL_ "GenSigTimeoutTime" BU_SG_REL_ Kombi_PAG SG_ 783 Heckradar_Kombitexte 2000;
BA_REL_ "GenSigTimeoutTime" BU_SG_REL_ Kombi_PAG SG_ 783 RCTA_Kombitexte 2000;
BA_REL_ "GenSigTimeoutTime" BU_SG_REL_ Kombi_PAG SG_ 1413 SI_QRS_Mode 5000;
BA_REL_ "GenSigTimeoutTime" BU_SG_REL_ Kombi_PAG SG_ 1413 SI_T_Mode 5000;
BA_REL_ "GenSigTimeoutTime" BU_SG_REL_ Kombi_PAG SG_ 1413 SI_NWDF 5000;
BA_REL_ "GenSigTimeoutTime" BU_SG_REL_ Kombi_PAG SG_ 1413 SI_NWDF_gueltig 5000;
BA_REL_ "GenSigTimeoutTime" BU_SG_REL_ Kombi_PAG SG_ 1413 SI_T_Schutz 5000;
BA_REL_ "GenSigTimeoutTime" BU_SG_REL_ Kombi_PAG SG_ 1413 SI_BUS_01 5000;
BA_REL_ "GenSigTimeoutTime" BU_SG_REL_ Kombi_PAG SG_ 1413 SI_BUS_03 5000;
BA_REL_ "GenSigTimeoutTime" BU_SG_REL_ Kombi_PAG SG_ 1413 SI_BUS_04 5000;
BA_REL_ "GenSigTimeoutTime" BU_SG_REL_ Kombi_PAG SG_ 1413 SI_BUS_06 5000;
BA_REL_ "GenSigTimeoutTime" BU_SG_REL_ Kombi_PAG SG_ 1413 SI_BUS_10 5000;
BA_REL_ "GenSigTimeoutTime" BU_SG_REL_ Kombi_PAG SG_ 1413 SI_BUS_12 5000;
BA_REL_ "GenSigTimeoutTime" BU_SG_REL_ Kombi_PAG SG_ 1413 SI_BUS_13 5000;
BA_REL_ "GenSigTimeoutTime" BU_SG_REL_ Kombi_PAG SG_ 1604 TG_Geber_1 5000;
BA_REL_ "GenSigTimeoutTime" BU_SG_REL_ Kombi_PAG SG_ 1604 TG_Geber_2 5000;
BA_REL_ "GenSigTimeoutTime" BU_SG_REL_ Kombi_PAG SG_ 1604 TG_Geber_3 5000;
BA_REL_ "GenSigTimeoutTime" BU_SG_REL_ Kombi_PAG SG_ 1604 TG_Geber_4 5000;
BA_REL_ "GenSigTimeoutTime" BU_SG_REL_ Kombi_PAG SG_ 1604 TG_Guete_Geber_1 5000;
BA_REL_ "GenSigTimeoutTime" BU_SG_REL_ Kombi_PAG SG_ 1604 TG_Guete_Geber_2 5000;
BA_REL_ "GenSigTimeoutTime" BU_SG_REL_ Kombi_PAG SG_ 1604 TG_Guete_Geber_3 5000;
BA_REL_ "GenSigTimeoutTime" BU_SG_REL_ Kombi_PAG SG_ 1604 TG_Guete_Geber_4 5000;
BA_REL_ "GenSigTimeoutTime" BU_SG_REL_ Kombi_PAG SG_ 1001 Thermo_Verbrauch_BTL 1000;
BA_REL_ "GenSigTimeoutTime" BU_SG_REL_ Kombi_PAG SG_ 1001 Thermo_Verbrauch_BTL_Ueberlauf 1000;
BA_REL_ "GenSigTimeoutTime" BU_SG_REL_ Kombi_PAG SG_ 1001 Thermo_Verbrauch_Innen 1000;
BA_REL_ "GenSigTimeoutTime" BU_SG_REL_ Kombi_PAG SG_ 1001 Thermo_Verbrauch_Innen_Ueberlauf 1000;
BA_REL_ "GenSigTimeoutTime" BU_SG_REL_ Kombi_PAG SG_ 1375 TME_VoKo_Strategie_Anzeige 5000;
BA_REL_ "GenSigTimeoutTime" BU_SG_REL_ Kombi_PAG SG_ 1375 TME_Kuehlmittel_Sensor 5000;
BA_REL_ "GenSigTimeoutTime" BU_SG_REL_ Kombi_PAG SG_ 1657 TME_TCP_Kond_active 5000;
BA_REL_ "GenSigTimeoutTime" BU_SG_REL_ Kombi_PAG SG_ 977 BT_Tuer_Status 5000;
BA_REL_ "GenSigTimeoutTime" BU_SG_REL_ Kombi_PAG SG_ 977 BT_Sp_Blk_def 5000;
BA_REL_ "GenSigTimeoutTime" BU_SG_REL_ Kombi_PAG SG_ 977 BT_TCR_Mode_aktiv 5000;
BA_REL_ "GenSigTimeoutTime" BU_SG_REL_ Kombi_PAG SG_ 977 ASW_Warnung_aktiv_BFS 5000;
BA_REL_ "GenSigTimeoutTime" BU_SG_REL_ Kombi_PAG SG_ 977 BT_Tuerschloss_defekt 5000;
BA_REL_ "GenSigTimeoutTime" BU_SG_REL_ Kombi_PAG SG_ 977 BT_Tueroeffnen_Warnung 5000;
BA_REL_ "GenSigTimeoutTime" BU_SG_REL_ Kombi_PAG SG_ 976 FT_Sp_Blk_def 1000;
BA_REL_ "GenSigTimeoutTime" BU_SG_REL_ Kombi_PAG SG_ 976 FT_Kisi_Fehler 1000;
BA_REL_ "GenSigTimeoutTime" BU_SG_REL_ Kombi_PAG SG_ 976 ASW_Warnung_aktiv_FS 1000;
BA_REL_ "GenSigTimeoutTime" BU_SG_REL_ Kombi_PAG SG_ 976 FT_Tuerschloss_defekt 1000;
BA_REL_ "GenSigTimeoutTime" BU_SG_REL_ Kombi_PAG SG_ 997 TSG_FT_02_CRC 1000;
BA_REL_ "GenSigTimeoutTime" BU_SG_REL_ Kombi_PAG SG_ 997 TSG_FT_02_BZ 1000;
BA_REL_ "GenSigTimeoutTime" BU_SG_REL_ Kombi_PAG SG_ 997 FT_Tuer_Status 1000;
BA_REL_ "GenSigTimeoutTime" BU_SG_REL_ Kombi_PAG SG_ 997 FT_Tueroeffnen_Warnung 1000;
BA_REL_ "GenSigTimeoutTime" BU_SG_REL_ Kombi_PAG SG_ 997 FT_TCR_Mode_aktiv 1000;
BA_REL_ "GenSigTimeoutTime" BU_SG_REL_ Kombi_PAG SG_ 975 HBFS_Tuerschloss_defekt 5000;
BA_REL_ "GenSigTimeoutTime" BU_SG_REL_ Kombi_PAG SG_ 975 HBFS_Tuer_Status 5000;
BA_REL_ "GenSigTimeoutTime" BU_SG_REL_ Kombi_PAG SG_ 975 HBFS_Tueroeffnen_Warnung 5000;
BA_REL_ "GenSigTimeoutTime" BU_SG_REL_ Kombi_PAG SG_ 975 ASW_Warnung_aktiv_HBFS 5000;
BA_REL_ "GenSigTimeoutTime" BU_SG_REL_ Kombi_PAG SG_ 975 HBFS_Status_KiSi 5000;
BA_REL_ "GenSigTimeoutTime" BU_SG_REL_ Kombi_PAG SG_ 703 HBFS_TCR_Mode_aktiv 1000;
BA_REL_ "GenSigTimeoutTime" BU_SG_REL_ Waehlhebel_SB SG_ 1413 SI_NWDF 5000;
BA_REL_ "GenSigTimeoutTime" BU_SG_REL_ Waehlhebel_SB SG_ 1413 SI_NWDF_gueltig 5000;
BA_REL_ "GenSigTimeoutTime" BU_SG_REL_ Waehlhebel_SB SG_ 1413 SI_BUS_10 5000;
VAL_ 980 BH_Blinker_li 0 "nicht_betaetigt" 1 "Blinkerhebel_Pos_li_betaetigt" ;
VAL_ 980 BH_Blinker_re 0 "nicht_betaetigt" 1 "Blinkerhebel_Pos_re_betaetigt" ;
VAL_ 980 BH_Lichthupe 0 "nicht_betaetigt" 1 "Blinkerhebel in Richtung Lichthupe betaetigt" ;
VAL_ 980 BH_Fernlicht 0 "nicht_betaetigt" 1 "Blinkerhebel_in_Richtung_Fernlicht_betaetigt" ;
VAL_ 980 WH_Tipwischen 0 "nicht_betaetigt" 1 "betaetigt" ;
VAL_ 980 WH_Intervall 0 "aus" 1 "Wischerhebel in Stellung Intervall" ;
VAL_ 980 WH_WischerStufe1 0 "aus" 1 "Wischerhebel in Stufe Wischen 1" ;
VAL_ 980 WH_WischerStufe2 0 "aus" 1 "Wischerhebel in Stufe Wischen 2" ;
VAL_ 980 WH_Frontwaschen 0 "aus" 1 "Wischerhebel in Stellung Wisch Wasch vorne" ;
VAL_ 980 WH_Heckintervall 0 "nicht_betaetigt" 1 "Wischerhebel in Stellung Heckintervall" ;
VAL_ 980 WH_Heckwaschen 0 "nicht_betaetigt" 1 "Wischerhebel in Stellung Wisch Wasch hinten" ;
VAL_ 980 WH_Intervallstufen 0 "Init / Default" 1 "Intervallstufe 1" 5 "Intervallstufe 2" 9 "Intervallstufe 3" 13 "Intervallstufe 4" 15 "Fehler" ;
VAL_ 980 FAS_Taster 0 "nicht_betaetigt" 1 "betaetigt" ;
VAL_ 980 FAS_Taster_Fehler 0 "kein_Fehler" 1 "Fehler" ;
VAL_ 980 SMLS_Hupe 0 "nicht_betaetigt" 1 "Hupe_gedrueckt" ;
VAL_ 980 LRH_On_Off 0 "LRH_aus__keine Anzeige" 1 "LRH_aus" 2 "LRH_ein" 3 "Fehler" ;
VAL_ 980 LRH_aktiv 0 "inaktiv" 1 "aktiv" ;
VAL_ 980 SMLS_P_verriegelt_plausibel 0 "unplausibel" 1 "plausibel" ;
VAL_ 980 WH_SRA 0 "SRA_Aus" 1 "SRA_Ein" ;
VAL_ 980 WH_Wischer_Fehler 0 "kein_Fehler" 1 "Fehler" ;
VAL_ 980 BH_Blinker_Fehler 0 "kein_Fehler" 1 "Fehler" ;
VAL_ 980 SMLS_PTT 0 "nicht_betaetigt" 1 "PTT_gedrueckt" ;
VAL_ 980 WH_Tipwischen_lang 0 "nicht_betaetigt" 1 "betaetigt" ;
VAL_ 904 SpoilerSG_HSpoiler_IstPos 254 "Init" 255 "Fehler" ;
VAL_ 904 SpoilerSG_Fehler 0 "Init_bzw_kein_Fehler" 1 "Stoerung_Spoiler_weiss" 2 "Fehler_Spoiler_Prio1_rot" 3 "Fehler_Spoiler_Prio2_rot" ;
VAL_ 904 SpoilerSG_Anf_ESP_Zuschaltung 0 "Init_keine_Anforderung" 1 "ESP_Zuschaltung_angefordert" ;
VAL_ 904 SpoilerSG_Status 0 "Spoiler_eingefahren__Init" 1 "Spoiler_ausgefahren" 2 "Diagnose_aktiv" 3 "Spoiler_verfaehrt_oder_Zwischenstellung" ;
VAL_ 904 LFE_Status 0 "LFE_verriegelt___Init" 1 "LFE_entriegelt" ;
VAL_ 904 TE_TrunkEntrapment_Fehler 0 "inaktiv" 1 "aktiv" ;
VAL_ 904 SpoilerSG_AeroZustand 0 "Zustand_0" 1 "Zustand_1" 2 "Zustand_2" 3 "Zustand_3" 4 "Zustand_4" 5 "Zustand_5" 6 "Zustand_6" 7 "Zustand_7" 8 "Zustand_8" 9 "Zustand_9" 10 "Zustand_10" 11 "Zustand_11" 12 "Zustand_12" 13 "Zustand_13" 14 "init" 15 "Fehler" ;
VAL_ 904 BugSp_AOCCT_Fehlerstatus 0 "no_failure" 1 "failure" ;
VAL_ 904 BugSp_AOCCT_Teststatus 0 "diag_incomplete" 1 "diag_complete" ;
VAL_ 904 BugSp_AOCCT_timer1_count 0 "inactive" 1 "active" ;
VAL_ 904 BugSp_AOCCT_timer1_verbaut 0 "not_current" 1 "installed_and_coded" ;
VAL_ 904 BugSp_AOCCT_timer2_count 0 "inactiv" 1 "active" ;
VAL_ 904 BugSp_AOCCT_timer2_verbaut 0 "not_current" 1 "installed_and_coded" ;
VAL_ 904 HeckSp_AOCCT_Fehlerstatus 0 "no_failure" 1 "failure" ;
VAL_ 904 HeckSp_AOCCT_Teststatus 0 "diag_incomplete" 1 "diag_complete" ;
VAL_ 904 HeckSp_AOCCT_timer1_count 0 "inactive" 1 "active" ;
VAL_ 904 HeckSp_AOCCT_timer1_verbaut 0 "not_current" 1 "installed_and_coded" ;
VAL_ 904 HeckSp_AOCCT_timer2_count 0 "inactive" 1 "active" ;
VAL_ 904 HeckSp_AOCCT_timer2_verbaut 0 "not_current" 1 "installed_and_coded" ;
VAL_ 904 SpoilerSG_SKE_PosSens_Status 0 "Init" 1 "SKE_geschlossen" 2 "SKE_offen" 3 "Fehler" ;
VAL_ 1313 STH_Funk_ein 0 "kein Funkbefehl zum Einschalten" 1 "Funkbefehl zum Einschalten erhalten" ;
VAL_ 1313 STH_Funk_aus 0 "kein Funkbefehl" 1 "Funkbefehl zum Ausschalten erhalten" ;
VAL_ 1313 STH_Zusatzheizung 0 "Zuheizer aus" 1 "Zuheizer ein" ;
VAL_ 1313 STH_LED 0 "keine Rückmeldung" 1 "Rueckmeldung Standheizung in Betrieb" ;
VAL_ 1313 STH_Geblaese 0 "kein Einschaltbefehl an die Klimaanlage, Gebläse" 1 "Einschaltbefehl an die Klimaanlage, Gebläse" ;
VAL_ 1313 STH_EKP_Anst 0 "EKP nicht ansteuern" 1 "EKP ansteuern" ;
VAL_ 1313 STH_Start_folgt 0 "kein_Start_folgt" 1 "Start_folgt" ;
VAL_ 1313 STH_Ventil_Status 0 "Ventil_offen__grosser_Kreislauf" 1 "Ventil_geschlossen__kleiner_Kreislauf" ;
VAL_ 1313 STH_Fehler_ElWaPu 0 "kein_Fehler" 1 "Fehler" ;
VAL_ 1313 STH_Pumpen_Anf_extern 0 "nicht_angefordert" 1 "angefordert" ;
VAL_ 1313 STH_KL_HUP 0 "Aus" 1 "Ein" ;
VAL_ 1313 STH_Fehlerstatus 0 "kein_Fehler" 1 "Unterspannung" 2 "Tankfuellstand_zu_gering" 3 "Fehler_Betrieb_verhindert" 4 "Heizgeraet_verriegelt" 5 "Fehler_Betrieb_nicht_verhindert" 6 "Emissionsüberschreitung" ;
VAL_ 1313 STH_Wassertemp 254 "Init" 255 "Fehler" ;
VAL_ 1313 STH_Texte 0 "keine_Anzeige" 1 "Batteriemanagementeinschraenkung" 2 "Kraftstoffmangel" 3 "interner_Systemfehler" 4 "Heizzeitueberschreitung" ;
VAL_ 1313 STH_Motorvorwaermung 0 "keine Motorvorwärmung erfolgt" 1 "Aufheizung mit Motorvorwärmung erfolgt" ;
VAL_ 1313 STH_Servicemode 0 "Servicemode nicht aktiv" 1 "Servicemode aktiv" ;
VAL_ 1313 STH_war_aktiv 0 "war inaktiv" 1 "Standheizung war letzte halbe Stunde aktiv" ;
VAL_ 1313 STH_KVS_Ueberlauf 0 "kein Überlauf" 1 "Kraftstoffverbrauchssignal, mindestens ein Überlauf hat stattgefunden" ;
VAL_ 1313 STH_SH_ZH 0 "Heizgeraet_WZH" 1 "Heizgeraet_ZH" ;
VAL_ 505 STP_Slave_Status 0 "STP_Slave_Init" 1 "STP_Slave_Deaktiviert" 2 "STP_Slave_Ready" 3 "Vorhalt" 4 "STP_Slave_Aktivierverhinderung" 5 "STP_Slave_Aktiv" 6 "STP_Slave_ESK_Uebernahme" 7 "STP_Slave_Uebergabe" 8 "STP_Slave_ESK0_Anf" 9 "STP_Slave_ESK1_Anf" 10 "STP_Slave_ESK2_Anf" 11 "STP_Slave_ESK3_Anf" 12 "STP_Slave_stabiler_Zustand" 13 "STP_Slave_Notlauf_Aktiv" 14 "STP_Slave_nicht_verfuegbar" 15 "STP_Slave_Error" ;
VAL_ 505 FZE_STP_Abschaltbedingung 0 "Vorhalt" 1 "STP_Abschaltbedingung_liegt_nicht_an" 2 "Vorhalt" 3 "STP_ESK0" 4 "STP_ESK1" 5 "STP_ESK2" 6 "STP_ESK3" 7 "STP_NL" ;
VAL_ 505 ACA_HF_Grund_AV_AB 0 "Liegt_nicht_an_oder_init" 1 "LRR_Kriterium" 2 "Fahrerbeobachtung" 3 "Fahrerlenkeingriff" 4 "Vorhalt" 5 "Vorhalt" 6 "Vorhalt" 7 "Vorhalt" ;
VAL_ 505 FZE_STP_Status 0 "Init" 1 "Ready" 2 "Fehler_reversible" 3 "Fehler_irreversible" ;
VAL_ 505 STP_Notlaufaktivierung 0 "Notlauf_nicht_angefordert" 1 "Notlauf_angefordert" ;
VAL_ 505 STP_Funktion_freigegeben 0 "nicht_freigegeben" 1 "freigegeben" ;
VAL_ 505 ACA_QF_Status_Anzeige 0 "ACA_QF_nicht_codiert" 1 "ACA_QF_INIT" 2 "ACA_QF_AUS" 3 "ACA_QF_PASSIV" 4 "ACA_QF_AKTIV" 5 "ACA_QF_UEBERLENKT" 6 "ACA_QF_Abschaltreaktion" 7 "ACA_QF_reversibler_Fehler" 8 "ACA_QF_irreversibler_Fehler" 9 "ACA_QF_Sensor_Blindheit" ;
VAL_ 505 ACF_SwuFahrerUnaufmerksam 0 "Swu_Fahrer_Nicht_unaufmerksam" 1 "Swu_Fahrer_unaufmerksam" ;
VAL_ 505 ACA_QF_Fahreruebernahme 0 "keine" 1 "Uebernahme_1" 2 "Uebernahme_2" 3 "Uebernahme_3" ;
VAL_ 505 ACA_HF_Status 0 "ACA_HF_nicht_codiert" 1 "ACA_HF_Init" 2 "ACA_HF_aus" 3 "ACA_HF_nicht_verfuegbar" 4 "ACA_HF_verfuegbar" 5 "ACA_HF_aktiv" 6 "Vorhalt" 7 "ACA_HF_reversibler_Fehler" 8 "ACA_HF_irreversibler_Fehler" 9 "ACA_HF_Uebernahme_1" 10 "ACA_HF_Uebernahme_2" 11 "Vorhalt" 12 "Vorhalt" 13 "Vorhalt" 14 "Vorhalt" 15 "Vorhalt" ;
VAL_ 505 FZE_Spurwechsel_erkannt_li 0 "kein_Spurwechsel_erkannt" 1 "Spurwechsel_erkannt_links" ;
VAL_ 505 FZE_Spurwechsel_erkannt_re 0 "kein_Spurwechsel_erkannt" 1 "Spurwechsel_erkannt_rechts" ;
VAL_ 505 ACF_Spurwechsel_moeglich 0 "keine_Spurwechselmoeglichkeit_vorhanden" 1 "Spurwechselmoeglichkeit_vorhanden" ;
VAL_ 505 ACF_Spurwechsel_wahrscheinlich 0 "kein_Spurwechsel" 1 "Spurwechsel_wahrscheinlich" ;
VAL_ 505 FZE_STP_Aktivierverhinderung 0 "liegt_nicht_an" 1 "Fahrer_nicht_erkannt" 2 "Vorhalt" 3 "Vorhalt" ;
VAL_ 666 STP_Abstand_Zielobjekt 0 "keine_Anzeige_oder_init" ;
VAL_ 666 STP_Texte_ESK 0 "keine_Anzeige" 1 "STP_ESK_keine_Laenderverfuegbarkeit" 2 "STP_ESK_Abfahrt_erkannt" 3 "STP_ESK_falsche_Strassenkat" 4 "STP_ESK_Delta_v_zu_hoch" 5 "STP_ESK_Stabilisierungsys_aktiv" 6 "STP_ESK_keine_Trennung_zum_Gv" 7 "STP_ESK_Fussgaenger_erkannt" 8 "STP_ESK_kein_Stau_auf_Nachbars" 9 "STP_ESK_V_Streckenabsch_unplaus" 10 "STP_ESK_pACC_nicht_verfuegbar" 11 "STP_ESK_Rettungsg_stark_versetzt" 12 "STP_ESK_Baustelle" 13 "STP_ESK_Sicherheitskor_verletzt" ;
VAL_ 666 STP_Status_Anzeige 0 "STP_INIT" 1 "STP_AUS" 2 "STP_PASSIV" 3 "STP_AKTIV_1" 4 "STP_AKTIV_2" 5 "STP_Eskalationsstufe_1" 6 "STP_Eskalationsstufe_2" 7 "STP_Eskalationsstufe_3" 8 "STP_Eskalationsstufe_4" 9 "STP_Fehler" ;
VAL_ 666 STP_Nebenspur_links_ZA 0 "keine_Anzeige_oder_init" 1 "Nachbarkolonne" 2 "Randbebauung" ;
VAL_ 666 STP_Nebenspur_rechts_ZA 0 "keine_Anzeige_oder_init" 1 "Nachbarkolonne" 2 "Randbebauung" ;
VAL_ 666 STP_FBM_links_ZA 0 "keine_Anzeige_oder_init" 1 "FBM_an" ;
VAL_ 666 STP_Geschw_Egofahrzeug_ZA 0 "statisch_init" 1 "dynamisch" ;
VAL_ 666 STP_Egokolonne_ZA 0 "keine_Anzeige_oder_init" 1 "eng" 2 "weit" 3 "Warnung" ;
VAL_ 666 STP_FBM_rechts_ZA 0 "keine_Anzeige_oder_init" 1 "FBM_an" ;
VAL_ 666 STP_FAS_Fkt_Status 0 "Init" 1 "Funktion_Ist_Ein" 2 "Funktion_Ist_Aus" 3 "Fehler" 4 "Pilot_Aktiv" ;
VAL_ 666 STP_Texte_ZA 0 "keine_Anzeige" 1 "STP_Uebernahme_1" 2 "STP_Uebernahme_2" 3 "Unklare_Verkehrssituation" 4 "Kurvenradius" 5 "Gurt_offen" 6 "Stauende" 7 "Wegfall_Fahrspur" 8 "STP_Car_Pool_Lane" 9 "Fahrer_nicht_erkannt" 10 "STP_unzulaessige_Fahrspur" ;
VAL_ 666 STP_Texte_AV 0 "keine_Anzeige" 1 "STP_AV_CarMenue_aus" 2 "STP_AV_Anhaengerbetrieb" 3 "STP_AV_Wegfall_Fahrspur" 4 "STP_AV_Kurvenradius" 5 "STP_AV_Abfahrt_erkannt" 6 "STP_AV_Unklare_Verkehrssituation" 7 "STP_AV_Delta_v_zu_hoch" 8 "STP_AV_Stabilisierungssys_aktiv" 9 "STP_AV_Gangstufe_nicht_erlaubt" 10 "STP_AV_keine_Trennung_zum_Gv" 11 "STP_AV_Fussgaenger_erkannt" 12 "STP_AV_kein_Stau_auf_Nachbarstr" 13 "STP_AV_Rettungsg_stark_versetzt" 14 "STP_AV_Baustelle" 15 "STP_AV_Sicherheitskor_verletzt" ;
VAL_ 666 STP_Texte 0 "keine_Anzeige" 1 "STP_nicht_verfuegbar" 2 "STP_Stoerung" 3 "STP_Uebernahme_1" 4 "STP_Uebernahme_2" 5 "STP_Lenkung_Pedalerie_freigeben" 6 "STP_Pilottaste_druecken" 7 "STP_Aktivierverhinderung" 8 "STP_Eskalationsstufe_2" 9 "STP_Eskalationsstufe_3" 10 "STP_Eskalationsstufe_4" 11 "STP_deaktiviert" 12 "STP_Bremsung_1" 13 "STP_Bremsung_2" 14 "STP_Fahrer_nicht_erkannt" 15 "STP_aktiv" 16 "STP_keine_Laenderverfuegbarkeit" 17 "STP_unzulaessige_Fahrspur" 18 "STP_Baustelle_voraus" 19 "STP_Rampe_voraus" 20 "STP_Autobahnende_voraus" ;
VAL_ 666 STP_Primaeranz_02 0 "keine_Anzeige" 1 "Verfuegbar" 2 "Aktiv" 3 "Uebernahme" 4 "Aktiv_Warnung" 5 "Nicht_Verfuegbar" ;
VAL_ 666 STP_Nebenspur_Geschw_links_ZA 255 "keine_Anzeige" ;
VAL_ 666 STP_Nebenspur_Geschw_rechts_ZA 255 "keine_Anzeige" ;
VAL_ 1172 STS_Car_not_under_theft 0 "false" 1 "true" ;
VAL_ 1172 STS_Car_under_theft 0 "false" 1 "true" ;
VAL_ 1172 STS_Door_Lock 0 "Init" 1 "door_lock" ;
VAL_ 1172 STS_Anlassersperre 0 "inaktiv" 1 "aktiv" ;
VAL_ 1172 STS_Typencodierung 0 "Basis" 1 "E-Gas" 4 "Sonderschutz" ;
VAL_ 1172 STS_Spiegel_Anklappen 0 "Init" 1 "Spiegel_anklappen" ;
VAL_ 1172 GW_STS2_Privatsphaere 0 "Aus" 1 "Ein" ;
VAL_ 1172 STS_Standlicht 0 "inaktiv" 1 "aktiv" ;
VAL_ 1172 STS_Fahrlicht 0 "inaktiv" 1 "aktiv" ;
VAL_ 1172 STS_Alarm_still 0 "inaktiv" 1 "aktiv" ;
VAL_ 1172 STS_Texte 0 "kein_Text" 1 "Text_01" 2 "Text_02" 3 "Text_03" 4 "Text_04" 5 "Text_05" 6 "Text_06" 7 "Text_07" 8 "Text_08" 9 "Text_09" 10 "Text_10" 11 "Text_11" 12 "Text_12" 13 "Text_13" 14 "Init" 15 "Fehler" ;
VAL_ 1172 STS_Laderelais 0 "Relais_offen" 1 "Relais_geschlossen" ;
VAL_ 1172 STS_Summer 0 "inaktiv" 1 "aktiv" ;
VAL_ 1172 STS_Alarm_Blinker 0 "Init" ;
VAL_ 1172 STS_Notstart 0 "kein_Notstart" 1 "Notstart" ;
VAL_ 1172 STS_Signalhorn 0 "inaktiv" 1 "aktiv" ;
VAL_ 1172 STS_Leerlaufschaltung 0 "inaktiv" 1 "aktiv" ;
VAL_ 783 SWA_Anzeigen 0 "keine_Anzeige" 1 "Text_1_SWA_zurzeit_nicht_verfuegbar" 2 "Text_2_SWA_Systemstoerung" 3 "Text_3_SWA_zurzeit_nicht_verfuegbar_Keine_Sensorsicht" 4 "Text_4_SWA_zurzeit_nicht_verfuegbar_Anhaengerbetrieb" 5 "Text_5_SWA_Eskalation" 6 "Text_6_SWA_eingeschränkt" ;
VAL_ 783 SWA_Blindheit_erkannt 0 "nicht erkannt" 1 "erkannt" ;
VAL_ 783 SWA_rel_Nichtverf 0 "verfuegbar" 1 "nicht verfuegbar" ;
VAL_ 783 SWA_rel_Fehler 0 "kein Fehler" 1 "Fehler" ;
VAL_ 783 SWA_Sta_aktiv 0 "Aus" 1 "Ein" ;
VAL_ 783 SWA_Sta_passiv 0 "Aus" 1 "Ein" ;
VAL_ 783 SWA_FT_RueckLED 0 "inaktiv" 1 "aktiv" ;
VAL_ 783 ASW_Status 0 "Passiv" 1 "Aktiv" 2 "Fehler" 3 "AUS" ;
VAL_ 783 SWA_Standziele_li 0 "Abstand i.O." 1 "Abstand zu gering" ;
VAL_ 783 SWA_Kolonne_li 0 "zwei_oder_weniger_Fahrzeuge_auf_der_Spur" 1 "mehr_als_zwei_Fahrzeuge_auf_der_Spur" ;
VAL_ 783 SWA_Infostufe_SWA_li 0 "keine_Aktion" 1 "Aktion" ;
VAL_ 783 SWA_Warnung_SWA_li 0 "keine Warnung" 1 "Warnung aktiv" ;
VAL_ 783 ASW_Warnung_FS 0 "inaktiv" 1 "aktiv" ;
VAL_ 783 ASW_Warnung_BFS 0 "inaktiv" 1 "aktiv" ;
VAL_ 783 ASW_Kombitexte 0 "keine Anzeige.    //    Prio 5" 1 "Text_1_ASW_zur_Zeit_nicht_verfuegbar_und_Akustik    //    Prio 2" 2 "Text_2_ASW_Systemfehler_und_Akustik    //    Prio 1" 3 "Text_3_ASW_Sensor_blockiert_und_Akustik    //    Prio 3" 4 "Text_4_ASW_im_Anhaengerbetrieb_nicht_verfuegbar_und_Akustik    //    Prio 4" 5 "Text_5_ASW_Warnung_FS_und_Akustik" 6 "Text_6_ASW_Warnung_BFS_und_Akustik" 7 "Text_7_ASW_aus" ;
VAL_ 783 SWA_Kolonne_mi 0 "zwei_oder_weniger_Fahrzeuge_auf_der_Spur" 1 "mehr_als_zwei_Fahrzeuge_auf_der_Spur" ;
VAL_ 783 ASW_Modus 0 "kein_Fehler_KL15" 1 "kein_Fehler_KL30" 2 "reserve" 3 "Anhaengerbetrieb" 4 "Init_nicht_codiert" 5 "keine_Sensorsicht_blindheit" 6 "Zur_zeit_nicht_verfuegbar_temp_Fehler" 7 "Systemstoerung_dauer_fehler" ;
VAL_ 783 SWA_Modus 0 "kein_Fehler_verfuegbar" 1 "kein_Fehler_eingeschr_Reichweite" 2 "reserve" 3 "Anhaengerbetrieb" 4 "Init_nicht_codiert" 5 "keine_Sensorsicht_blindheit" 6 "Zur_zeit_nicht_verfuegbar_temp_Fehler" 7 "Systemstoerung_dauer_fehler" ;
VAL_ 783 SWA_Standziele_re 0 "Abstand i.O." 1 "Abstand zu gering" ;
VAL_ 783 SWA_Kolonne_re 0 "zwei_oder_weniger_Fahrzeuge_auf_der_Spur" 1 "mehr_als_zwei_Fahrzeuge_auf_der_Spur" ;
VAL_ 783 SWA_Infostufe_SWA_re 0 "keine_Aktion" 1 "Aktion" ;
VAL_ 783 SWA_Warnung_SWA_re 0 "keine Warnung" 1 "Warnung aktiv" ;
VAL_ 783 HRE_Anzeigetexte 0 "keine_Anzeige" 1 "BSD_RTA_zZt_nicht_verfuegbar" 2 "BSD_RTA_Systemfehler" 3 "BSD_RTA_Sensor_blockiert" 4 "BSD_RTA_Anhaengerbetrieb" 5 "RTA_Warnung" 6 "BSD_Warnung" 7 "Fahreruebernahme_Notbremsung" 8 "RTA_nicht_verfuegbar" 9 "BSD_RTA_ASW_zZt_nicht_verfuegbar" 10 "BSD_RTA_ASW_Systemfehler" 11 "BSD_RTA_ASW_Sensor_blockiert" 12 "BSD_RTA_ASW_Anhaengerbetrieb" ;
VAL_ 783 SWA_Status_02 0 "aus" 1 "passiv" 2 "aktiv" 3 "Fehler" ;
VAL_ 783 Heckradar_Kombitexte 0 "keine Anzeige.    //    Prio 5" 1 "Text_1_SWA_und_ASW_zur_Zeit_nicht_verfuegbar_und_Akustik    //    Prio 2" 2 "Text_2_SWA_und_ASW_Systemfehler_und_Akustik    //    Prio 1" 3 "Text_3_SWA_und_ASW_Sensor_blockiert_und_Akustik    //    Prio 3" 4 "Text_4_SWA_und_ASW_im_Anhaengerbetrieb_nicht_verfuegbar_und_Akustik    //    Prio 4" 5 "Text_1_SWA_und_RCTA_zur_Zeit_nicht_verfuegbar_und_Akustik // Prio 2" 6 "Text_2_SWA_und_RCTA_Systemfehler_und_Akustik // Prio 1" 7 "		Text_3_SWA_und_RCTA_Sensor_blockiert_und_Akustik // Prio 3" 8 "Text_4_SWA_und_RCTA_im_Anhaengerbetrieb_nicht_verfuegbar_und_Akustik // Prio 4" 9 "Text_1_ASW_und_RCTA_zur_Zeit_nicht_verfuegbar_und_Akustik // Prio 2" 10 "Text_2_ASW_und_RCTA_Systemfehler_und_Akustik // Prio 1" 11 "Text_3_ASW_und_RCTA_Sensor_blockiert_und_Akustik // Prio 3" 12 "Text_4_ASW_und_RCTA_im_Anhaengerbetrieb_nicht_verfuegbar_und_Akustik // Prio 4" 13 "Text_1_SWA_und_ASW_und_RCTA_zur_Zeit_nicht_verfuegbar_und_Akustik // Prio 2" 14 "Text_2_SWA_und_ASW_und_RCTA_Systemfehler_und_Akustik // Prio 1" 15 "Text_3_SWA_und_ASW_und_RCTA_Sensor_blockiert_und_Akustik // Prio 3" 16 "Text_4_SWA_und_ASW_und_RCTA_im_Anhaengerbetrieb_nicht_verfuegbar_und_Akustik // Prio 4" 17 "reserviert" 18 "reserviert" 19 "reserviert" 20 "reserviert" 21 "reserviert" 22 "reserviert" 23 "reserviert" 24 "reserviert" 25 "reserviert" 26 "reserviert" 27 "reserviert" 28 "reserviert" 29 "reserviert" ;
VAL_ 783 RCTA_Kombitexte 0 "keine_Anzeige" 1 "RCTA_zur_Zeit_nicht_verfuegbar" 2 "RCTA_Systemfehler" 3 "RCTA_Sensor_blockiert" 4 "RCTA_im_Anhaengerbetrieb" 5 "RTA_Warnung" 6 "Fahreruebernahme_Notbremsung" 7 "Eingeschraenkt_verfuegbar_ESCaus" ;
VAL_ 1413 SI_Sammel_SG_Fehler 61 "Reserviert" 62 "Overflow" 63 "ungueltig" ;
VAL_ 1413 SI_Diagnose_Aktiv 0 "inaktiv" 1 "aktiv" ;
VAL_ 1413 SI_QRS_Mode 0 "QRS_Messmodus_nicht_aktiv" 1 "QRS_Messmodus_aktiv" ;
VAL_ 1413 SI_T_Mode 0 "Transportmodus_nicht_aktiv" 1 "Transportmodus_aktiv" ;
VAL_ 1413 SI_NWDF 0 "Ueberwachung_nicht_freigegeben" 1 "Ueberwachung_freigegeben" ;
VAL_ 1413 SI_NWDF_gueltig 0 "NWDF_wird_nicht_unterstuetzt" 1 "NWDF_wird_unterstuetzt" ;
VAL_ 1413 SI_Sammelfehler 0 "kein_Sammelfehler" 1 "Sammelfehler" ;
VAL_ 1413 GW_KD_Fehler 0 "kein_KD_Fehler" 1 "KD_Fehler" ;
VAL_ 1413 SI_T_Schutz 0 "Transportschutz_nicht_aktiv" 1 "Transportschutz_aktiv" ;
VAL_ 1413 SI_BUS_01 0 "keine_Busruhe" 1 "Busruhe" ;
VAL_ 1413 SI_BUS_02 0 "keine_Busruhe" 1 "Busruhe" ;
VAL_ 1413 SI_BUS_03 0 "keine_Busruhe" 1 "Busruhe" ;
VAL_ 1413 SI_BUS_04 0 "keine_Busruhe" 1 "Busruhe" ;
VAL_ 1413 SI_BUS_05 0 "keine_Busruhe" 1 "Busruhe" ;
VAL_ 1413 SI_BUS_06 0 "keine_Busruhe" 1 "Busruhe" ;
VAL_ 1413 SI_BUS_07 0 "keine_Busruhe" 1 "Busruhe" ;
VAL_ 1413 SI_BUS_08 0 "keine_Busruhe" 1 "Busruhe" ;
VAL_ 1413 SI_BUS_09 0 "keine_Busruhe" 1 "Busruhe" ;
VAL_ 1413 SI_BUS_10 0 "keine_Busruhe" 1 "Busruhe" ;
VAL_ 1413 SI_BUS_11 0 "keine_Busruhe" 1 "Busruhe" ;
VAL_ 1413 SI_BUS_12 0 "keine_Busruhe" 1 "Busruhe" ;
VAL_ 1413 SI_BUS_13 0 "keine_Busruhe" 1 "Busruhe" ;
VAL_ 1413 SI_BUS_14 0 "keine_Busruhe" 1 "Busruhe" ;
VAL_ 1413 SI_BUS_15 0 "keine_Busruhe" 1 "Busruhe" ;
VAL_ 1413 SI_Bus_Identifikation 16 "CAN_Diagnose" 17 "CAN_Antrieb" 18 "CAN_Komfort" 19 "CAN_Infotainment" 20 "CAN_Fahrwerk" 21 "CAN_Extended" 22 "CAN_Hybrid" 23 "CAN_Lade" 24 "CAN_Kombi" 25 "CAN_Komfort_2" 26 "CAN_AFS" 27 "CAN_MIB" 33 "CAN_FahrerAssistenzSysteme" 34 "CAN_Migration" 35 "CAN_Connect" 36 "CAN_AnzeigeBedienung" 37 "CAN_ElectricalVehicle" 40 "CAN_Telematik" 41 "CAN_MFL" 42 "CAN_FahrerAssistenzSysteme_2" 47 "CAN_Komfort_3" 48 "FlexRay_A" 49 "FlexRay_B" 97 "VLAN_FAS" 98 "VLAN_Infotainment" 99 "VLAN_Connect" 100 "VLAN_Komfort" 101 "VLAN_Antrieb" 102 "VLAN_Diagnose" 103 "VLAN_Internet" 104 "VLAN_Gateway" 105 "VLAN_Remote_FC" 106 "VLAN_Connect_2" 107 "VLAN_Licht" 108 "VLAN_Charge" 109 "VLAN_Cockpit" 176 "HCP1_CANFD01" 177 "HCP1_CANFD02" 178 "HCP1_CANFD03" 179 "HCP1_CANFD04" 180 "HCP1_CANFD05" 181 "HCP1_CANFD06" 182 "HCP1_CANFD07" 183 "HCP1_CANFD08" 186 "HCP4_CANFD03" 187 "HCP4_CANFD04" 188 "HCP1_CANFD09" 189 "HCP4_CANFD06" 190 "HCP4_CANFD07" 191 "HCP4_CANFD08" 192 "HCP4_CANFD09" 193 "HCP4_CANFD10" 194 "HCP1_CANFD10" 195 "ICAS1_CANFD2_HCP5_CANFD02" 196 "HCP1_CANFD11" 197 "WU_HCP1_CANFD" 199 "WU_HCP2_CANFD" 200 "WU_HCP3_CANFD" 201 "WU_HCP4_CANFD" 202 "HCP3_CANFD02" 204 "ESC_CANFD" 205 "HCP4_CANFD11" 206 "HCP4_CANFD12" 207 "HCP5_CANFD04" 208 "HCP5_CANFD05" 212 "WU_ConMod_CANFD" 213 "WU_PASD_CANFD" 215 "CAN_MobileDeviceKey" ;
VAL_ 1413 SI_CAB 0 "inaktiv" 1 "CAB_01__Tueren" 2 "CAB_02__Anhaenger" 4 "CAB_03__Nightvision" 8 "CAB_04__Sitzverstellung" 16 "CAB_05__Klappen" 32 "CAB_06__Infotainment" 64 "CAB_07__Sub_Infotainment" 128 "CAB_08__Anzeige" 256 "CAB_09__Laden" 512 "CAB_10__Klima" 1024 "CAB_11__FlexRay" 262144 "CAB_19_VLAN_Remote_FC" 524288 "CAB_20_VLAN_Komfort" 1048576 "CAB_21_VLAN_Internet" 2097152 "CAB_22_VLAN_Connect" 4194304 "CAB_23_VLAN_Infotainment" 8388608 "CAB_24_VLAN_FAS" ;
VAL_ 619 TA_FoD_Status 0 "Init" 1 "kein_TA_verbaut" 2 "TA_Low_verbaut" 3 "TA_Low_und_TA_High_verbaut" ;
VAL_ 619 TA_aktiv_HMI 0 "nicht_aktiv" 1 "TA_Low_aktiv" 2 "TA_High_aktiv" ;
VAL_ 619 TA_Fehler 0 "kein_Fehler" 1 "Fehler_TA_Low" 2 "Fehler_TA_Low_keine_Sensorsicht" 3 "Fehler_TA_High" 4 "Fehler_TA_High_keine_Sensorsicht" ;
VAL_ 1604 TG_Geber_1 0 "Init_bzw_nicht_verbaut" 4095 "Fehler" ;
VAL_ 1604 TG_Geber_2 0 "Init_bzw_nicht_verbaut" 4095 "Fehler" ;
VAL_ 1604 TG_Geber_3 0 "Init_bzw_nicht_verbaut" 4095 "Fehler" ;
VAL_ 1604 TG_Geber_4 0 "Init_bzw_nicht_verbaut" 4095 "Fehler" ;
VAL_ 1604 TG_Guete_Geber_1 12 "Unter_oder_Ueberspannung" 13 "nicht_verbaut" 14 "Init" 15 "Fehler" ;
VAL_ 1604 TG_Guete_Geber_2 12 "Unter_oder_Ueberspannung" 13 "nicht_verbaut" 14 "Init" 15 "Fehler" ;
VAL_ 1604 TG_Guete_Geber_3 12 "Unter_oder_Ueberspannung" 13 "nicht_verbaut" 14 "Init" 15 "Fehler" ;
VAL_ 1604 TG_Guete_Geber_4 12 "Unter_oder_Ueberspannung" 13 "nicht_verbaut" 14 "Init" 15 "Fehler" ;
VAL_ 1001 Thermo_Pred_T_dyn_Innen 254 "Init" 255 "Fehler" ;
VAL_ 1001 Thermo_Pred_P_dyn_Innen 2046 "Init" 2047 "Fehler" ;
VAL_ 1001 Thermo_Pred_P_stat_Innen 2046 "Init" 2047 "Fehler" ;
VAL_ 1001 Thermo_Verbrauch_BTL_Ueberlauf 0 "kein_Ueberlauf" 1 "Ueberlauf" ;
VAL_ 1001 Thermo_Verbrauch_Innen_Ueberlauf 0 "kein_Ueberlauf" 1 "Ueberlauf" ;
VAL_ 1375 TME_VoKo_Strategie_Anzeige 0 "Inaktiv" 1 "Standby" 2 "Lueften_elektrisch" 3 "Lueften_konventionell" 4 "Kuehlen_elektrisch" 5 "Reheat_elektrisch" 6 "Heizen_elektrisch" 7 "Heizen_verbrennungstechnisch" 8 "Reserve" 14 "Init" 15 "Fehler" ;
VAL_ 1375 TME_Zuheizer_Freigabe 0 "keine_Freigabe" 1 "Freigabe" ;
VAL_ 1375 TME_AC_LED 0 "LED_aus" 1 "LED_ein" ;
VAL_ 1375 TME_Heizstrategie 0 "Init" 1 "Aus" 2 "Spuelen" 3 "Kanalkuehlung" 4 "Kuehhlwasserzirkulation" 5 "aktive_Kuehlung" 6 "Heizen" 7 "Reheat" 8 "Heizen_elektrisch" 9 "Heizen_verbrennungstechnisch" 10 "Konditionierung_n_moeglich" 11 "Heizstrategie_11" 12 "Heizstrategie_12" 13 "Heizstrategie_13" 14 "Heizstrategie_14" 15 "Fehler" ;
VAL_ 1375 TME_Systemstatus 0 "System_IO" 1 "System_reduziert__Akkustik" 2 "System_reduziert__HV_Management" 3 "Fehler" ;
VAL_ 1375 TME_Kbr_Innenraum 0 "nicht_verfuegbar" 1 "verfuegbar" ;
VAL_ 1375 TME_Freigabe_Vorkond 0 "keine_Freigabe" 1 "Freigabe" ;
VAL_ 1375 TME_Verdampfer_Status 0 "inaktiv" 1 "aktiv" ;
VAL_ 1375 TME_Kuehlmittel_Sensor 0 "Kuehlkreis_OK" 1 "Kuehlmittelmangel_Pumpenfehler" ;
VAL_ 1375 TME_AC_Rueckmeldung 0 "EKK_laeuft_nicht" 1 "EKK_laeuft_reduziert" 2 "EKK_laeuft" 3 "Fehler" ;
VAL_ 1375 TME_Heizungspumpen_Anst 13 "Fehler" 14 "Init" 15 "nicht_verbaut" ;
VAL_ 1375 TME_Frischluftklappe_Soll 126 "Init" 127 "Fehler" ;
VAL_ 1375 TME_Freigabe_Luft_PTC 0 "keine_Freigabe" 1 "Freigabe" ;
VAL_ 1375 TME_Umluftklappe_Soll 126 "Init" 127 "Fehler" ;
VAL_ 1375 TME_Waermepumpe_aktiv 0 "inaktiv" 1 "aktiv" ;
VAL_ 1375 TME_Absperrventil1_oeffnen 0 "nicht_verfuegbar" 1 "Ansteuerung_Ventil_zulaessig" 2 "Ventil_oeffnen_oder_geoeffnet" 3 "Ventil_schliessen_oder_geschlossen" ;
VAL_ 1375 TME_Klima_Defizit 254 "Init" 255 "Fehler" ;
VAL_ 1375 TME_Temp_KM_vor_HWT 254 "Init" 255 "Fehler" ;
VAL_ 1657 TME_TCP_Kond_active 0 "TCP_Konditionierung_inaktiv" 1 "TCP_Konditionierung_aktiv" ;
VAL_ 1657 TME_Temp_KM_vor_eATL 254 "Init" 255 "Fehler" ;
VAL_ 1657 TME_Temp_KM_nach_EM 253 "Nicht_verbaut" 254 "Init" 255 "Fehler" ;
VAL_ 1657 TME_EKK_ProtectionMode 0 "ProtectionMode_inactive" 1 "ProtectionMode_active" ;
VAL_ 1657 TME_Klimaanforderung 0 "keine_Anforderung_durch_TME" 1 "Klimaleistungspraediktion_aktiv" 2 "berechnung_Vorkonditionierung_aktiv" 3 "Vorkonditionierung_aktiv" ;
VAL_ 1657 TME_SKE_Pos_Summe 14 "Init" ;
VAL_ 1657 TME_Waermebilanz_Status 0 "kein_Fehler" 1 "TP_TC_OBDI" 2 "TP_TC_OBDII" 3 "Fehler" ;
VAL_ 1657 TME_Waermebilanz 0 "kein_Waermestrom" 1 "kleiner_Waermestrom" 2 "mittlerer_Waermestrom" 3 "hoher_Waermestrom" ;
VAL_ 1657 TME_Klimaleistung 126 "Init" ;
VAL_ 1657 TME_SKE_PosResp 0 "SKE_Soll_nicht_erreicht" 1 "SKE_Soll_erreicht" ;
VAL_ 1657 TME_SKE_Position_1 0 "Geoeffnet" 1 "Teilgeschlossen" 2 "Geschlossen" 3 "Init" ;
VAL_ 1657 TME_Systemtemp 254 "Init" 255 "Fehler" ;
VAL_ 1657 TME_Eingriff_SKE_Oeffnung 0 "Init" 1 "offen" 2 "teilgeschlossen" 3 "geschlossen" ;
VAL_ 1657 TME_SKE_Status 0 "Init" 1 "geschlossen" 2 "offen" 3 "Fehler" ;
VAL_ 1657 TME_Status_Kuehlmittel_Tmp_CrChk 0 "Pruefung_nicht_erfolgt" 1 "kein_Fehler_Kuehlmittel_Temp" 2 "Fehler_Kuehlmittel_Temp" ;
VAL_ 1657 TME_Temperatur_Ruecklauf_VKM 254 "Init" 255 "Fehler" ;
VAL_ 2527679762 TPUI_WarnLvlCmft 0 "160_kmh" 1 "170_kmh" 2 "180_kmh" 3 "190_kmh" 4 "200_kmh" 5 "210_kmh" 6 "240_kmh" 7 "250_kmh" 8 "270_kmh" 9 "290_kmh" 10 "300_kmh" 11 "310_kmh" 14 "Init" 15 "Fehler" ;
VAL_ 2527679762 TPUI_WarnLvlMaxV 0 "200_kmh" 1 "210_kmh" 2 "220_kmh" 3 "230_kmh" 4 "240_kmh" 5 "250_kmh" 6 "260_kmh" 7 "270_kmh" 8 "280_kmh" 9 "290_kmh" 10 "300_kmh" 11 "310_kmh" 14 "Init" 15 "Fehler" ;
VAL_ 977 BT_Tuer_geoeffnet 0 "geschlossen" 1 "offen" ;
VAL_ 977 BT_verriegelt 0 "Init" 1 "verriegelt" ;
VAL_ 977 BT_gesafet 0 "Init" 1 "gesafet" ;
VAL_ 977 BT_Schluesselschalter_auf 0 "Init" 1 "Schluesselschalter_auf_betaetigt" ;
VAL_ 977 BT_Schluesselschalter_zu 0 "Init" 1 "Schluesselschalter_zu_betaetigt" ;
VAL_ 977 BT_Unlock_Taster 0 "Init" 1 "Unlock_Taster_betaetigt" ;
VAL_ 977 BT_Lock_Taster 0 "Init" 1 "Lock_Taster_betaetigt" ;
VAL_ 977 BT_Sperrklinke 0 "Schloss_in_Vorraste_und_Hauptraste" 1 "Tuer_auf_oder_Tuer_Position_zwischen_Vor_und_Hauptraste" ;
VAL_ 977 BT_TAG_betaetigt 0 "Init" 1 "Tuerinnengriff_betaetigt" ;
VAL_ 977 BT_TIG_betaetigt 0 "Init" 1 "Tuerinnengriff_betaetigt" ;
VAL_ 977 BT_Tuer_Status 0 "Init" 1 "Tuer_geschlossen" 2 "Tuer_offen" 3 "Fehler" ;
VAL_ 977 BT_TSG_hinten_verbaut 0 "nicht verbaut" 1 "verbaut" ;
VAL_ 977 BT_Sp_Blk_def 0 "iO" 1 "Spiegel_Blinker_defekt" ;
VAL_ 977 BT_FH_S_ManHoch 0 "Init" 1 "FH_Schalter_man_hoch_gedrueckt" ;
VAL_ 977 BT_FH_S_AutoHoch 0 "Init" 1 "FH_Schalter_auto_hoch_gedrueckt" ;
VAL_ 977 BT_FH_S_ManTief 0 "Init" 1 "FH_Schalter_man_tief_gedrueckt" ;
VAL_ 977 BT_FH_S_AutoTief 0 "Init" 1 "FH_Schalter_auto_tief_gedrueckt" ;
VAL_ 977 BT_FH_Bew_hoch 0 "Init" 1 "FH_ist_in_Bewegung_hoch" ;
VAL_ 977 BT_FH_Bew_tief 0 "Init" 1 "FH_ist_in_Bewegung_tief" ;
VAL_ 977 BT_FH_Fang 0 "ausserhalb_Fangbereich" 1 "innerhalb_Fangbereich" ;
VAL_ 977 BT_FH_Block 0 "Init" 1 "Fensterheber_Block" ;
VAL_ 977 BT_FH_Thermo 0 "Init" 1 "Thermoschutz_aktiv" ;
VAL_ 977 BT_UEKB_aktiviert 0 "Init" 1 "aktiv" ;
VAL_ 977 BT_Kisi_Fehler 0 "kein_Fehler" 1 "Fehler" ;
VAL_ 977 BT_FH_normiert 0 "Init" 1 "Fenster_normiert" ;
VAL_ 977 BT_Schliesstaster 1 "betaetigt" ;
VAL_ 977 BT_Zuziehhilfe_aktiv 0 "Init" 1 "Zuziehhilfe_aktiv" ;
VAL_ 977 BT_SP_ausgerastet 0 "Init" 1 "Spiegel_ausgerastet" ;
VAL_ 977 BT_SP_lr_aktiv 0 "Init" 1 "Spiegel_xAchse_aktiv" ;
VAL_ 977 BT_SP_ht_aktiv 0 "Init" 1 "Spiegel_yAchse_aktiv" ;
VAL_ 977 BT_SP_Heizung_aktiv 1 "BF Spiegelheizung ein" ;
VAL_ 977 BT_Oben_Block_erw 0 "Fensterheber_nicht_in_Blockerwar" 1 "Fensterheber_in_Blockerwartung_o" ;
VAL_ 977 BT_Unten_Block_erw 0 "Fensterheber_nicht_in_Blockerwar" 1 "Fensterheber_in_Blockerwartung_u" ;
VAL_ 977 BT_Tuer_Status_QBit 0 "Status_Tuerkontakt_sicher" 1 "Status_Tuerkontakt_unsicher" ;
VAL_ 977 BFS_Status_eTAG 0 "Init" 1 "Griff_ausgefahren" 2 "Griff_eingefahren" 3 "Fehler" ;
VAL_ 977 BT_TCR_Mode_aktiv 0 "TCR_Mode_deaktiv" 1 "TCR_Mode_aktiv" ;
VAL_ 977 BT_SP_Heizung_Status 0 "Init" 1 "Status_Spiegelheizung_ein" ;
VAL_ 977 ASW_Warnung_aktiv_BFS 0 "nicht_angefordert" 1 "angefordert" ;
VAL_ 977 BT_FH_Pos_oben 1 "Scheibe oben (nach Absenken auf Position) " ;
VAL_ 977 BT_Tuerschloss_defekt 0 "Tuerschloss_funktionsfaehig" 1 "Tuerschloss_defekt" ;
VAL_ 977 BT_Tueroeffnen_Warnung 0 "Tuerwarnung_nicht_aktiv" 1 "Tuerwarnung_aktiv" ;
VAL_ 977 BT_Lock_Taster_inv 0 "Lock Taster betätigt" 1 "Lock Taster nicht betätigt" ;
VAL_ 977 BT_Schluesselschalter_zu_inv 0 "Schlüsselschalter betätigt" 1 "Schlüsselschalter nicht betätigt" ;
VAL_ 977 BT_SWA_HMI_defekt 0 "SWA_kein_Fehler" 1 "SWA_Fehler" ;
VAL_ 977 BT_ASW_HMI_defekt 0 "ASW_kein_Fehler" 1 "ASW_Fehler" ;
VAL_ 976 FT_Tuer_geoeffnet 0 "geschlossen" 1 "Tuer_offen" ;
VAL_ 976 FT_verriegelt 0 "Init" 1 "verriegelt" ;
VAL_ 976 FT_gesafet 0 "Init" 1 "gesafet" ;
VAL_ 976 FT_Schluesselschalter_auf 0 "Init" 1 "Schluesselschalter_auf_betaetigt" ;
VAL_ 976 FT_Schluesselschalter_zu 1 "Schluesselschalter zu betaetigt" ;
VAL_ 976 FT_Unlock_Taster 0 "Init" 1 "Unlock_Taster_betaetigt" ;
VAL_ 976 FT_Lock_Taster 0 "Init" 1 "Lock_Taster_betaetigt" ;
VAL_ 976 FT_Sperrklinke 0 "Schloss_in_Vorraste_und_Hauptraste" 1 "Tuer_auf_oder_Tuer_Position_zwischen_Vor_und_Hauptraste" ;
VAL_ 976 FT_TAG_betaetigt 0 "nicht_betaetigt" 1 "betaetigt" ;
VAL_ 976 FT_TIG_betaetigt 0 "nicht_betaetigt" 1 "betaetigt" ;
VAL_ 976 FT_IRUE_Taste 0 "Init" 1 "IRUE_Taste_betaetigt" ;
VAL_ 976 FT_HD_Taste 0 "nicht_betaetigt" 1 "Heckdeckeltaste_betaetigt" ;
VAL_ 976 FT_TD_Taste_Fehler 0 "iO" 1 "defekt" ;
VAL_ 976 FT_TD_Taste 0 "Init" 1 "Tankdeckel_Taster_betaetigt" ;
VAL_ 976 SSR_Temp_Freigabe 0 "SSR_Deaktiviert" 1 "SSR_Freigegeben" ;
VAL_ 976 FT_HD_Taste_2 0 "Taste_nicht_gedrueckt" 1 "Taste_gedrueckt" ;
VAL_ 976 FT_TSG_hinten_verbaut 0 "nicht verbaut" 1 "verbaut" ;
VAL_ 976 FT_Sp_Blk_def 0 "iO" 1 "defekt" ;
VAL_ 976 FT_FH_S_ManHoch 0 "Init" 1 "FH_Schalter_man_hoch_betaetigt" ;
VAL_ 976 FT_FH_S_AutoHoch 0 "Init" 1 "FH_Schalter_auto_hoch_betaetigt" ;
VAL_ 976 FT_FH_S_ManTief 0 "Init" 1 "FH_Schalter_man_tief_betaetigt" ;
VAL_ 976 FT_FH_S_AutoTief 0 "Init" 1 "FH_Schalter_auto_tief_betaetigt" ;
VAL_ 976 FT_FH_Bew_hoch 0 "Init" 1 "FH_in_Bewegung_hoch" ;
VAL_ 976 FT_FH_Bew_tief 0 "Init" 1 "FH_in_Bewegung_tief" ;
VAL_ 976 FT_FH_Fang 0 "ausserhalb_Fangbereich" 1 "innerhalb_Fangbereich" ;
VAL_ 976 FT_FH_Block 0 "Init" 1 "Fenster_Block" ;
VAL_ 976 FT_FH_Thermo 0 "Init" 1 "Thermoschutz_aktiv" ;
VAL_ 976 FT_UEKB_aktiviert 0 "Init" 1 "UEKB_aktiv" ;
VAL_ 976 ASW_HMI_defekt 0 "iO" 1 "defekt" ;
VAL_ 976 FT_FH_normiert 0 "Init" 1 "Fenster_normiert" ;
VAL_ 976 FT_Schliesstaster 1 "Schliesstaster_betaetigt" ;
VAL_ 976 FT_Zuziehhilfe_aktiv 0 "Init" 1 "Zuziehilfe_aktiv" ;
VAL_ 976 FT_SP_ausgerastet 0 "Init" 1 "Spiegel_ausgerastet" ;
VAL_ 976 FT_SP_lr_aktiv 0 "Init" 1 "Spiegel_xAchse_aktiv" ;
VAL_ 976 FT_SP_ht_aktiv 0 "Init" 1 "Spiegel_yAchse_aktiv" ;
VAL_ 976 ASW_wakeup 0 "Sleep" 1 "Wakeup" ;
VAL_ 976 FT_Oben_Block_erw 0 "Fensterheber_nicht_in_Blockerwar" 1 "Fensterheber_in_Blockerwartung_o" ;
VAL_ 976 FT_Unten_Block_erw 0 "Fensterheber_nicht_in_Blockerwar" 1 "Fensterheber_in_Blockerwartung_u" ;
VAL_ 976 FT_Kisi_li_aktiv 0 "inaktiv" 1 "aktiv" ;
VAL_ 976 FT_Kisi_re_aktiv 0 "inaktiv" 1 "aktiv" ;
VAL_ 976 FT_Kisi_Taster_li 0 "nicht_betaetigt" 1 "betaetigt" ;
VAL_ 976 FT_Kisi_Taster_re 0 "nicht_betaetigt" 1 "betaetigt" ;
VAL_ 976 FT_BFS_Fond_Freigabe 0 "Init" 1 "Freigabe_fuer_Fondbedienung_BFS" ;
VAL_ 976 FT_Kisi_Fehler 0 "kein_Fehler" 1 "Fehler" ;
VAL_ 976 FT_Daemmglas 0 "Normalglas_verbaut" 1 "Daemmglas_verbaut" ;
VAL_ 976 FT_SP_Heizung_Status 0 "Init" 1 "Status_Spiegelheizung_ein" ;
VAL_ 976 ASW_Warnung_aktiv_FS 0 "nicht_angefordert" 1 "angefordert" ;
VAL_ 976 FT_FH_Pos_oben 1 "Scheibe oben (nach Absenken auf Position) " ;
VAL_ 976 FT_Tuerschloss_defekt 0 "Tuerschloss_funktionsfaehig" 1 "Tuerschloss_defekt" ;
VAL_ 976 FT_SWA_Taster 0 "Taster_nicht_betaetigt" 1 "Taster_betaetigt" ;
VAL_ 976 SWA_HMI_Diagnose 0 "kein_Fehler_erkannt" 1 "Fehler_Taster_erkannt" 2 "Fehler_LED_erkannt" 3 "Fehler_LED_und_Taster_erkannt" ;
VAL_ 976 FS_Status_eTAG 0 "Init" 1 "Griff_ausgefahren" 2 "Griff_eingefahren" 3 "Fehler" ;
VAL_ 997 FT_Tuer_Status 0 "Init" 1 "Tuer_geschlossen" 2 "Tuer_offen" 3 "Fehler" ;
VAL_ 997 FT_Tuer_Status_QBit 0 "Status_Tuerkontakt_sicher" 1 "Status_Tuerkontakt_unsicher" ;
VAL_ 997 FT_Lock_Taster_02 0 "nicht_betaetigt" 1 "betaetigt" ;
VAL_ 997 FT_Schluesselschalter_zu_02 0 "nicht_betaetigt" 1 "betaetigt" ;
VAL_ 997 FT_BFS_Tuer_Status 0 "Init" 1 "Tuer_geschlossen" 2 "Tuer_offen" 3 "Fehler" ;
VAL_ 997 FT_HBFS_Tuer_Status 0 "Init" 1 "Tuer_geschlossen" 2 "Tuer_offen" 3 "Fehler" ;
VAL_ 997 FT_HFS_Tuer_Status 0 "Init" 1 "Tuer_geschlossen" 2 "Tuer_offen" 3 "Fehler" ;
VAL_ 997 FT_Tueroeffnen_Warnung 0 "Tuerwarnung_nicht_aktiv" 1 "Tuerwarnung_aktiv" ;
VAL_ 997 FT_SP_Heizung_ein 0 "Aus" 1 "Ein" ;
VAL_ 997 FT_Kisi_Taster_li_02 0 "nicht_betaetigt" 1 "betaetigt" ;
VAL_ 997 FT_Kisi_Taster_re_02 0 "nicht_betaetigt" 1 "betaetigt" ;
VAL_ 997 FT_TD_Taste_Status 0 "kein_Fehler" 1 "Kurzschluss_nach_Minus" 2 "Kurzschluss_nach_Plus" 3 "Leitungsunterbrechung" ;
VAL_ 997 FT_TCR_Mode_aktiv 0 "TCR_Mode_deaktiv" 1 "TCR_Mode_aktiv" ;
VAL_ 997 FS_Push_Tuergriff 0 "nicht_erkannt" 1 "erkannt" ;
VAL_ 975 HBFS_Tuer_geoeffnet 0 "geschlossen" 1 "offen" ;
VAL_ 975 HBFS_verriegelt 0 "nicht_verriegelt" 1 "verriegelt" ;
VAL_ 975 HBFS_gesafet 0 "nicht_gesafet" 1 "gesafet" ;
VAL_ 975 HBFS_Heckrollotaster_betaetigt 0 "keine_Verfahranweisung_in_Richtung_Hoch" 1 "In_Richtung_Hoch_Verfahren" ;
VAL_ 975 HBFS_Tuerschloss_defekt 0 "Tuerschloss_funktionsfaehig" 1 "Tuerschloss_defekt" ;
VAL_ 975 HBFS_Unlock_Taster 0 "nicht_betaetigt" 1 "betaetigt" ;
VAL_ 975 HBFS_Lock_Taster 0 "nicht_betaetigt" 1 "betaetigt" ;
VAL_ 975 HBFS_Sperrklinke 0 "Schloss_in_Vorraste_und_Hauptraste" 1 "Tuer_auf_oder_Tuer_Position_zwischen_Vor_und_Hauptraste" ;
VAL_ 975 HBFS_TAG_betaetigt 0 "nicht_betaetigt" 1 "betaetigt" ;
VAL_ 975 HBFS_TIG_betaetigt 0 "nicht_betaetigt" 1 "betaetigt" ;
VAL_ 975 HBFS_FH_S_HFS_AutoHoch 0 "keine_Bedienung" 1 "Automatiklauf_Angefordert" ;
VAL_ 975 HBFS_FH_S_HFS_AutoTief 0 "keine_Bedienung" 1 "Automatiklauf_Angefordert" ;
VAL_ 975 HBFS_FH_S_HFS_ManHoch 0 "keine_Bedienung" 1 "Manueller_Lauf_Angefordert" ;
VAL_ 975 HBFS_FH_S_HFS_ManTief 0 "keine_Bedienung" 1 "Manueller_Lauf_Angefordert" ;
VAL_ 975 HBFS_Tuer_Status 0 "Init" 1 "Tuer_geschlossen" 2 "Tuer_offen" 3 "Fehler" ;
VAL_ 975 HBFS_SAD_Schalter 0 "nicht_betaetigt" 5 "AUF_manuell" 6 "AUF_automatik" 7 "ZU_manuell" 8 "ZU_automatik" 13 "nicht_verfuegbar" 14 "Init" 15 "Fehler" ;
VAL_ 975 HBFS_FH_S_ManHoch 0 "nicht_betaetigt" 1 "betaetigt" ;
VAL_ 975 HBFS_FH_S_AutoHoch 0 "nicht_betaetigt" 1 "betaetigt" ;
VAL_ 975 HBFS_FH_S_ManTief 0 "nicht_betaetigt" 1 "betaetigt" ;
VAL_ 975 HBFS_FH_S_AutoTief 0 "nicht_betaetigt" 1 "betaetigt" ;
VAL_ 975 HBFS_FH_Bew_hoch 0 "inaktiv" 1 "aktiv" ;
VAL_ 975 HBFS_FH_Bew_tief 0 "inaktiv" 1 "aktiv" ;
VAL_ 975 HBFS_FH_Fang 0 "ausserhalb_Fangbereich" 1 "innerhalb_Fangbereich" ;
VAL_ 975 HBFS_FH_Block 0 "inaktiv" 1 "aktiv" ;
VAL_ 975 HBFS_FH_Thermo 0 "inaktiv" 1 "aktiv" ;
VAL_ 975 HBFS_UEKB_aktiviert 0 "inaktiv" 1 "aktiv" ;
VAL_ 975 HBFS_Tueroeffnen_Warnung 0 "Tuerwarnung_nicht_aktiv" 1 "Tuerwarnung_aktiv" ;
VAL_ 975 HBFS_FH_normiert 0 "inaktiv" 1 "aktiv" ;
VAL_ 975 ASW_Warnung_aktiv_HBFS 0 "nicht_angefordert" 1 "angefordert" ;
VAL_ 975 HBFS_Zuziehhilfe_aktiv 0 "Init" 1 "Zuziehhilfe_aktiv" ;
VAL_ 975 HBFS_Seitenrollo_hoch 1 "Seitenrollo_in_Bewegung_hoch" ;
VAL_ 975 HBFS_Seitenrollo_tief 0 "Init" 1 "Seitenrollo_in_Bewegung_tief" ;
VAL_ 975 HBFS_Status_KiSi 0 "inaktiv" 1 "aktiv" ;
VAL_ 975 SSR_HBFS_Pos_Unten 0 "SSR_Oben" 1 "SSR_Unten" ;
VAL_ 975 HBFS_Oben_Block_erw 0 "Fensterheber_nicht_in_Blockerwar" 1 "Fensterheber_in_Blockerwartung_o" ;
VAL_ 975 HBFS_Unten_Block_erw 0 "Fensterheber_nicht_in_Blockerwar" 1 "Fensterheber_in_Blockerwartung_u" ;
VAL_ 975 MTHBFS_M_Taste 0 "nicht_betaetigt" 1 "betaetigt" ;
VAL_ 975 MTHBFS_Pos1 0 "nicht_betaetigt" 1 "betaetigt" ;
VAL_ 975 MTHBFS_Pos2 0 "nicht_betaetigt" 1 "betaetigt" ;
VAL_ 975 MTHBFS_Pos3 0 "nicht_betaetigt" 1 "betaetigt" ;
VAL_ 975 HBFS_MRollo_Schalter 0 "nicht_betaetigt" 1 "ZU_manuell" 2 "ZU_automatik" 3 "AUF_manuell" 4 "AUF_automatik" 5 "nicht_verfuegbar" 6 "Init" 7 "Fehler" ;
VAL_ 975 HBFS_Lock_Taster_inv 0 "Lock Taster betätgit" 1 "Lock Taster nicht betätigt" ;
VAL_ 975 HBFS_Status_KiSi_inv 0 "aktiv" 1 "inaktiv" ;
VAL_ 975 HBFS_Status_eTAG 0 "Init" 1 "Griff_ausgefahren" 2 "Griff_eingefahren" 3 "Fehler" ;
VAL_ 975 HBFS_Tuer_Status_QBit 0 "Status_Tuerkontakt_sicher" 1 "Status_Tuerkontakt_unsicher" ;
VAL_ 975 HBFS_TIG_betaetigt_schliessen 0 "nicht_betaetigt" 1 "betaetigt" ;
VAL_ 703 HBFS_Status_KiSi 0 "inaktiv" 1 "aktiv" ;
VAL_ 703 HBFS_Push_Tuergriff 0 "nicht_erkannt" 1 "erkannt" ;
VAL_ 703 HBFS_TCR_Mode_aktiv 0 "TCR_Mode_deaktiv" 1 "TCR_Mode_aktiv" ;
